VERSION "Version"

NS_ :

BS_:

BU_: VDC_VCU BMS MCU EVCC EOP VDC_ITS GWM Tester IPS DCU ITS IPU TEL VCU VDC AVNT LPC DCDC

BO_ 864 VCU_2_E: 8 VDC_VCU
 SG_ VCU_AHFShutImme : 23|1@0+ (1,0) [0|1] ""  GWM,TEL,ITS,MCU,DCU
 SG_ VCU_AHFDelayEn : 48|1@0+ (1,0) [0|1] ""  GWM,TEL,ITS,MCU,DCU
 SG_ VCU_AHFActivationSt : 51|3@0+ (1,0) [0|7] ""  GWM,TEL,ITS,MCU,DCU
 SG_ VCU_PlgConnSt : 63|1@0+ (1,0) [0|1] ""  GWM,TEL,ITS,MCU,DCU,IPU

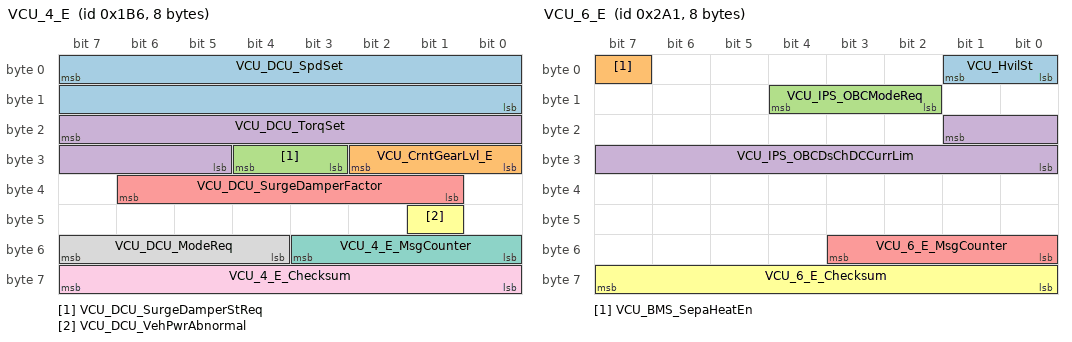
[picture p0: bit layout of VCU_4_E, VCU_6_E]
BO_ 438 VCU_4_E: 8 VDC_VCU
 SG_ VCU_DCU_SpdSet : 7|16@0+ (1,-32767) [-32767|32766] "rpm"  GWM,TEL,MCU,DCU,IPU
 SG_ VCU_CrntGearLvl_E : 26|3@0+ (1,0) [0|7] ""  GWM,TEL,MCU,DCU,IPU
 SG_ VCU_DCU_SurgeDamperStReq : 28|2@0+ (1,0) [0|3] ""  GWM,TEL,MCU,DCU,IPU
 SG_ VCU_DCU_TorqSet : 23|11@0+ (1,-1023) [-1023|1022] "Nm"  GWM,TEL,MCU,DCU,IPU
 SG_ VCU_DCU_SurgeDamperFactor : 38|6@0+ (0.125,0) [0|7.625] ""  GWM,TEL,MCU,DCU,IPU
 SG_ VCU_DCU_VehPwrAbnormal : 41|1@0+ (1,0) [0|1] ""  GWM,MCU,DCU
 SG_ VCU_4_E_MsgCounter : 51|4@0+ (1,0) [0|15] ""  GWM,TEL,MCU,DCU,IPU
 SG_ VCU_DCU_ModeReq : 55|4@0+ (1,0) [0|15] ""  GWM,TEL,MCU,DCU,IPU
 SG_ VCU_4_E_Checksum : 63|8@0+ (1,0) [0|255] ""  GWM,TEL,MCU,DCU,IPU

BO_ 680 VCU_5_E: 8 VDC_VCU
 SG_ VCU_IPS_DCDCVoltLvSet : 7|8@0+ (0.1,0) [0|25.5] "V"  GWM,TEL,MCU,IPS
 SG_ VCU_IPS_DCDCModeReq : 10|3@0+ (1,0) [0|7] ""  GWM,TEL,MCU,IPS
 SG_ VCU_IPS_DCDCLvCurrLim : 45|10@0+ (0.5,0) [0|511.5] "A"  GWM,TEL,MCU,IPS
 SG_ VCU_5_E_MsgCounter : 51|4@0+ (1,0) [0|15] ""  GWM,TEL,BMS,MCU,IPS
 SG_ VCU_5_E_Checksum : 63|8@0+ (1,0) [0|255] ""  GWM,TEL,BMS,MCU,IPS

BO_ 673 VCU_6_E: 8 VDC_VCU
 SG_ VCU_HvilSt : 1|2@0+ (1,0) [0|3] ""  GWM,TEL,BMS,MCU,DCU
 SG_ VCU_BMS_SepaHeatEn : 7|1@0+ (1,0) [0|1] ""  GWM,TEL,ITS,BMS,MCU,IPS
 SG_ VCU_IPS_OBCModeReq : 12|3@0+ (1,0) [0|7] ""  GWM,TEL,MCU,IPS
 SG_ VCU_IPS_OBCDsChDCCurrLim : 17|10@0+ (0.1,0) [0|102.3] "A"  GWM,TEL,MCU,IPS
 SG_ VCU_6_E_MsgCounter : 51|4@0+ (1,0) [0|15] ""  GWM,TEL,BMS,MCU,IPS
 SG_ VCU_6_E_Checksum : 63|8@0+ (1,0) [0|255] ""  GWM,TEL,BMS,MCU,IPS

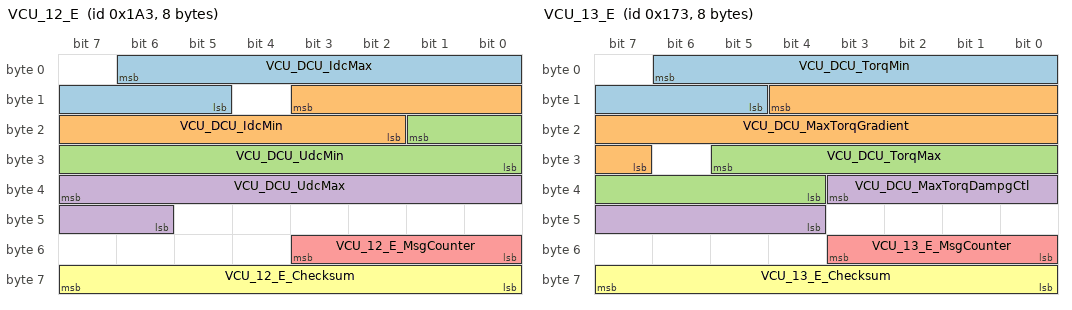
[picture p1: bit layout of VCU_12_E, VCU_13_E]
BO_ 419 VCU_12_E: 8 VDC_VCU
 SG_ VCU_DCU_IdcMax : 6|10@0+ (1,0) [0|1023] "A"  GWM,TEL,MCU,DCU,IPU
 SG_ VCU_DCU_IdcMin : 11|10@0+ (1,-1023) [-1023|0] "A"  GWM,TEL,MCU,DCU,IPU
 SG_ VCU_DCU_UdcMin : 17|10@0+ (1,0) [0|1021] "V"  GWM,TEL,MCU,DCU,IPU
 SG_ VCU_DCU_UdcMax : 39|10@0+ (1,0) [0|1021] "V"  GWM,TEL,MCU,DCU,IPU
 SG_ VCU_12_E_MsgCounter : 51|4@0+ (1,0) [0|15] ""  GWM,TEL,MCU,DCU,IPU
 SG_ VCU_12_E_Checksum : 63|8@0+ (1,0) [0|255] ""  GWM,TEL,MCU,DCU,IPU

BO_ 371 VCU_13_E: 8 VDC_VCU
 SG_ VCU_DCU_TorqMin : 6|10@0+ (1,-1023) [-1023|0] "Nm"  GWM,TEL,MCU,DCU,IPU
 SG_ VCU_DCU_MaxTorqGradient : 12|14@0+ (32,0) [0|524192] "Nm/s"  GWM,TEL,MCU,DCU,IPU
 SG_ VCU_DCU_TorqMax : 29|10@0+ (1,0) [0|1023] "Nm"  GWM,TEL,MCU,DCU,IPU
 SG_ VCU_DCU_MaxTorqDampgCtl : 35|8@0+ (1,0) [0|253] "Nm"  GWM,TEL,MCU,DCU,IPU
 SG_ VCU_13_E_MsgCounter : 51|4@0+ (1,0) [0|15] ""  GWM,TEL,MCU,DCU,IPS,IPU
 SG_ VCU_13_E_Checksum : 63|8@0+ (1,0) [0|255] ""  GWM,TEL,MCU,DCU,IPS,IPU

BO_ 893 VCU_16_E: 8 VDC_VCU
 SG_ VCU_IPS_OBCChgVoltReq : 7|16@0+ (0.1,0) [0|6553.5] "V"  GWM,TEL,MCU,IPS
 SG_ VCU_IPS_OBCChgCurrReq : 23|16@0+ (0.1,0) [0|6553.5] "A"  GWM,TEL,MCU,IPS
 SG_ VCU_16_E_MsgCounter : 51|4@0+ (1,0) [0|15] ""  GWM,TEL,MCU,IPS
 SG_ VCU_16_E_Checksum : 63|8@0+ (1,0) [0|255] ""  GWM,TEL,MCU,IPS

BO_ 779 VCU_20_E: 8 VDC_VCU
 SG_ VCU_AHFActivatePwr : 7|14@0+ (10,0) [0|163830] "W"  GWM,TEL,ITS,MCU,DCU
 SG_ VCU_DCU_IdcMeasure : 9|14@0+ (0.1,-819.2) [-819.2|819.1] "A"  GWM,TEL,ITS,MCU,DCU
 SG_ VCU_SwapHvBattModeSt : 62|2@0+ (1,0) [0|3] ""  DCU,ITS,GWM,EOP,MCU,DCDC,IPS,BMS
 SG_ VCU_SwapHvBattModeStVD : 63|1@0+ (1,0) [0|1] ""  DCU,ITS,GWM,EOP,MCU,DCDC,IPS,BMS

BO_ 964 VCU_22_E: 8 VDC_VCU
 SG_ VCU_22_E_MsgCounter : 51|4@0+ (1,0) [0|15] ""  GWM,TEL,MCU,DCU
 SG_ VCU_22_E_Checksum : 63|8@0+ (1,0) [0|255] ""  GWM,TEL,MCU,DCU

BO_ 983 VCU_25_E: 8 VDC_VCU
 SG_ VCU_TEL_AccPedalActPst : 39|8@0+ (1,0) [0|100] "%"  GWM,TEL,MCU,DCU

BO_ 357 VCU_42_E: 8 VDC_VCU
 SG_ VCU_DCU_SpdLmt : 7|16@0+ (1,-32767) [-32767|32766] "rpm"  GWM,TEL,MCU,DCU,IPU
 SG_ VCU_BrkPedPst_E : 23|8@0+ (0.392,0) [0|99.96] "%"  GWM,MCU,DCU
 SG_ VCU_EMS_AccPedalActPst_E : 31|8@0+ (0.392,0) [0|99.96] "%"  GWM,MCU,DCU

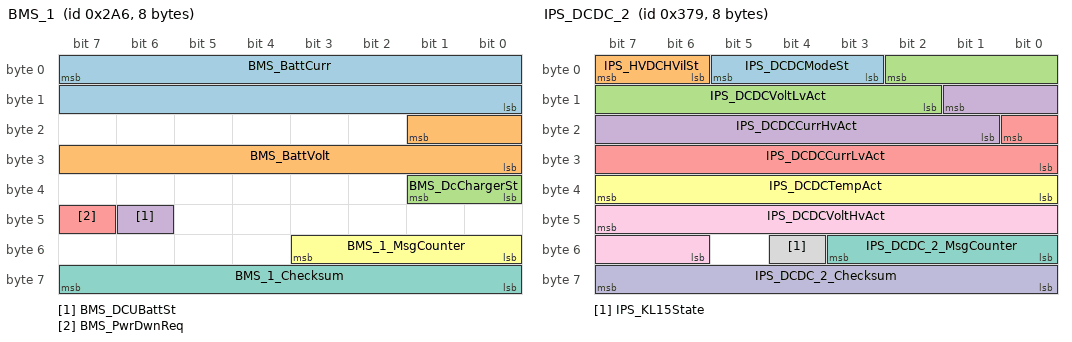
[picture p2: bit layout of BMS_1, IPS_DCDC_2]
BO_ 678 BMS_1: 8 BMS
 SG_ BMS_BattCurr : 7|16@0+ (0.1,-1000) [-1000|1000] "A"  GWM,TEL,MCU,DCU,IPU,VCU,VDC
 SG_ BMS_BattVolt : 17|10@0+ (1,0) [0|600] "V"  GWM,TEL,MCU,DCU,IPU,VCU,VDC,EVCC
 SG_ BMS_DcChargerSt : 33|2@0+ (1,0) [0|3] ""  GWM,TEL,MCU,DCU,IPU,VCU,VDC
 SG_ BMS_DCUBattSt : 46|1@0+ (1,0) [0|1] ""  GWM,TEL,ITS,MCU,DCU,IPS,IPU,VCU,VDC
 SG_ BMS_PwrDwnReq : 47|1@0+ (1,0) [0|1] ""  GWM,TEL,MCU,DCU,IPS,IPU,VCU,VDC
 SG_ BMS_1_MsgCounter : 51|4@0+ (1,0) [0|15] ""  GWM,TEL,MCU,DCU,IPS,IPU,VCU,VDC
 SG_ BMS_1_Checksum : 63|8@0+ (1,0) [0|255] ""  GWM,TEL,MCU,DCU,IPS,IPU,VCU,VDC

BO_ 887 BMS_3: 8 BMS
 SG_ BMS_DCVoltRx : 23|16@0+ (0.1,0) [0|750] "V"  GWM,TEL,MCU,DCU,VCU,VDC
 SG_ BMS_DCCurrRx : 39|16@0+ (0.1,-1000) [-1000|1000] "A"  GWM,TEL,MCU,DCU,VCU,VDC

BO_ 444 BMS_16: 8 BMS
 SG_ BMS_SepaHeatSt : 35|2@0+ (1,0) [0|3] ""  GWM,TEL,ITS,MCU,IPS,VCU,VDC
 SG_ BMS_16_MsgCounter : 51|4@0+ (1,0) [0|15] ""  GWM,TEL,MCU,IPS
 SG_ BMS_16_Checksum : 63|8@0+ (1,0) [0|255] ""  GWM,TEL,MCU,IPS

BO_ 889 IPS_DCDC_2: 8 MCU
 SG_ IPS_DCDCModeSt : 5|3@0+ (1,0) [0|7] ""  GWM,TEL,VCU,VDC
 SG_ IPS_HVDCHVilSt : 7|2@0+ (1,0) [0|3] ""  GWM,TEL,VCU,VDC
 SG_ IPS_DCDCVoltLvAct : 2|9@0+ (0.1,0) [0|51.1] "V"  GWM,TEL,ITS,DCU,VCU,VDC
 SG_ IPS_DCDCCurrHvAct : 9|9@0+ (0.125,0) [0|63.875] "A"  GWM,TEL,DCU,VCU,VDC
 SG_ IPS_DCDCCurrLvAct : 16|9@0+ (1,0) [0|511] "A"  GWM,TEL,VCU,VDC
 SG_ IPS_DCDCTempAct : 39|8@0+ (1,-40) [-40|215] "degC"  GWM,TEL,ITS,VCU,VDC
 SG_ IPS_DCDC_2_MsgCounter : 51|4@0+ (1,0) [0|15] ""  GWM,TEL,DCU,VCU,VDC
 SG_ IPS_KL15State : 52|1@0+ (1,0) [0|1] ""  GWM,TEL,VCU,VDC
 SG_ IPS_DCDCVoltHvAct : 47|10@0+ (1,0) [0|1023] "V"  GWM,TEL,DCU,VCU,VDC
 SG_ IPS_DCDC_2_Checksum : 63|8@0+ (1,0) [0|255] ""  GWM,TEL,DCU,VCU,VDC

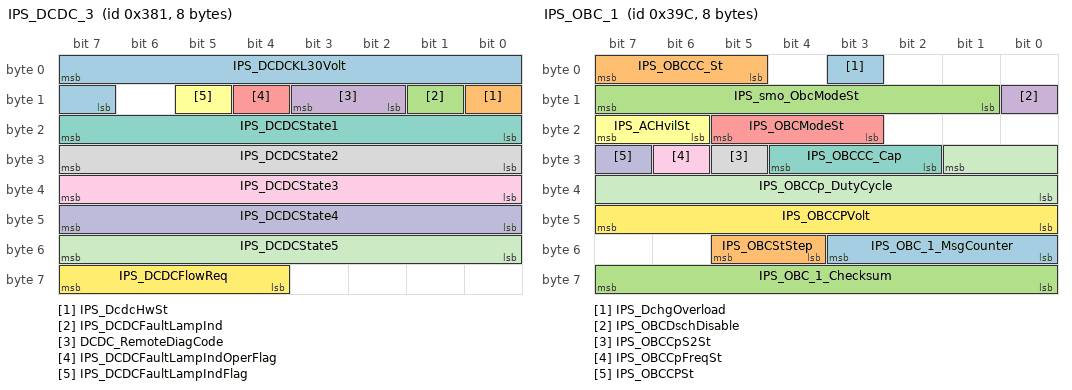
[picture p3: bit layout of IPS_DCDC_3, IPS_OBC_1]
BO_ 897 IPS_DCDC_3: 8 MCU
 SG_ IPS_DCDCKL30Volt : 7|9@0+ (0.125,0) [0|63.875] "V"  GWM,TEL,VCU,VDC
 SG_ IPS_DcdcHwSt : 8|1@0+ (1,0) [0|1] ""  GWM,TEL,VCU,VDC
 SG_ IPS_DCDCFaultLampInd : 9|1@0+ (1,0) [0|1] ""  GWM,TEL
 SG_ DCDC_RemoteDiagCode : 11|2@0+ (1,0) [0|3] ""  GWM,TEL,VCU,VDC
 SG_ IPS_DCDCFaultLampIndOperFlag : 12|1@0+ (1,0) [0|1] ""  GWM,TEL,VCU,VDC
 SG_ IPS_DCDCFaultLampIndFlag : 13|1@0+ (1,0) [0|1] ""  GWM,TEL,VCU,VDC
 SG_ IPS_DCDCState1 : 23|8@0+ (1,0) [0|255] ""  GWM,TEL
 SG_ IPS_DCDCState2 : 31|8@0+ (1,0) [0|255] ""  GWM,TEL
 SG_ IPS_DCDCState3 : 39|8@0+ (1,0) [0|255] ""  GWM,TEL
 SG_ IPS_DCDCState4 : 47|8@0+ (1,0) [0|255] ""  GWM,TEL
 SG_ IPS_DCDCState5 : 55|8@0+ (1,0) [0|255] ""  GWM,TEL
 SG_ IPS_DCDCFlowReq : 63|4@0+ (1,0) [0|15] "LpMin"  GWM,TEL,VCU,VDC

BO_ 924 IPS_OBC_1: 8 MCU
 SG_ IPS_DchgOverload : 3|1@0+ (1,0) [0|1] ""  GWM,TEL,VCU,VDC
 SG_ IPS_OBCCC_St : 7|3@0+ (1,0) [0|7] ""  GWM,TEL,ITS,BMS,DCU,VCU,VDC,EVCC
 SG_ IPS_smo_ObcModeSt : 15|7@0+ (1,0) [0|127] ""  GWM,TEL,VCU,VDC
 SG_ IPS_OBCDschDisable : 8|1@0+ (1,0) [0|1] ""  GWM,TEL,VCU,VDC
 SG_ IPS_OBCModeSt : 21|3@0+ (1,0) [0|7] ""  GWM,TEL,ITS,VCU,VDC
 SG_ IPS_ACHvilSt : 23|2@0+ (1,0) [0|3] ""  GWM,TEL,VCU,VDC
 SG_ IPS_OBCCC_Cap : 28|3@0+ (1,0) [0|7] ""  GWM,TEL,BMS,VCU,VDC
 SG_ IPS_OBCCpS2St : 29|1@0+ (1,0) [0|1] ""  GWM,TEL,VCU,VDC,EVCC
 SG_ IPS_OBCCpFreqSt : 30|1@0+ (1,0) [0|1] ""  GWM,TEL,VCU,VDC
 SG_ IPS_OBCCPSt : 31|1@0+ (1,0) [0|1] ""  GWM,TEL,VCU,VDC
 SG_ IPS_OBCCp_DutyCycle : 25|10@0+ (0.1,0) [0|100] ""  GWM,TEL
 SG_ IPS_OBCCPVolt : 47|8@0+ (0.1,0) [0|12.7] "V"  GWM,TEL,VCU,VDC
 SG_ IPS_OBC_1_MsgCounter : 51|4@0+ (1,0) [0|15] ""  GWM,TEL,BMS,VCU
 SG_ IPS_OBCStStep : 53|2@0+ (1,0) [0|3] ""  GWM,TEL
 SG_ IPS_OBC_1_Checksum : 63|8@0+ (1,0) [0|255] ""  GWM,TEL,VCU

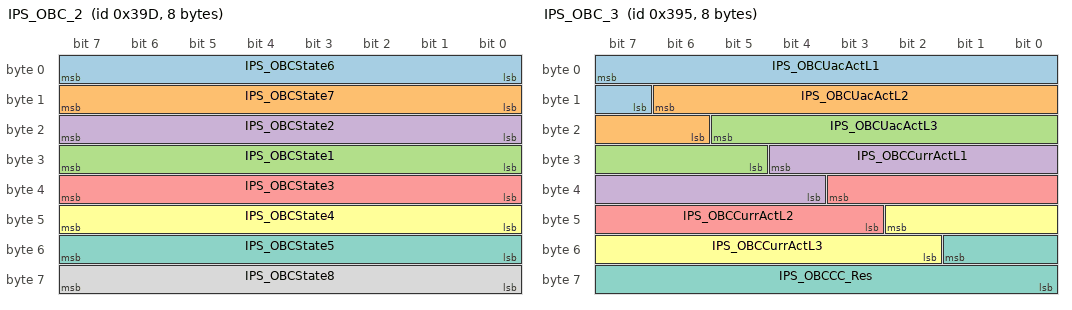
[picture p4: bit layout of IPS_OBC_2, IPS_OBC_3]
BO_ 925 IPS_OBC_2: 8 MCU
 SG_ IPS_OBCState6 : 7|8@0+ (1,0) [0|255] ""  GWM,TEL
 SG_ IPS_OBCState7 : 15|8@0+ (1,0) [0|255] ""  GWM,TEL
 SG_ IPS_OBCState1 : 31|8@0+ (1,0) [0|255] ""  GWM,TEL
 SG_ IPS_OBCState2 : 23|8@0+ (1,0) [0|255] ""  GWM,TEL
 SG_ IPS_OBCState3 : 39|8@0+ (1,0) [0|255] ""  GWM,TEL
 SG_ IPS_OBCState4 : 47|8@0+ (1,0) [0|255] ""  GWM,TEL
 SG_ IPS_OBCState5 : 55|8@0+ (1,0) [0|255] ""  GWM,TEL
 SG_ IPS_OBCState8 : 63|8@0+ (1,0) [0|255] ""  GWM,TEL

BO_ 917 IPS_OBC_3: 8 MCU
 SG_ IPS_OBCUacActL1 : 7|9@0+ (1,0) [0|511] "V"  GWM,TEL,VCU,VDC
 SG_ IPS_OBCUacActL2 : 14|9@0+ (1,0) [0|511] "V"  GWM,TEL,VCU,VDC
 SG_ IPS_OBCUacActL3 : 21|9@0+ (1,0) [0|511] "V"  GWM,TEL,VCU,VDC
 SG_ IPS_OBCCurrActL1 : 28|9@0+ (0.1,0) [0|51.1] "A"  GWM,TEL,VCU,VDC
 SG_ IPS_OBCCurrActL2 : 35|9@0+ (0.1,0) [0|51.1] "A"  GWM,TEL,VCU,VDC
 SG_ IPS_OBCCurrActL3 : 42|9@0+ (0.1,0) [0|51.1] "A"  GWM,TEL,VCU,VDC
 SG_ IPS_OBCCC_Res : 49|10@0+ (10,0) [0|10230] "Ω"  GWM,TEL,VCU,VDC

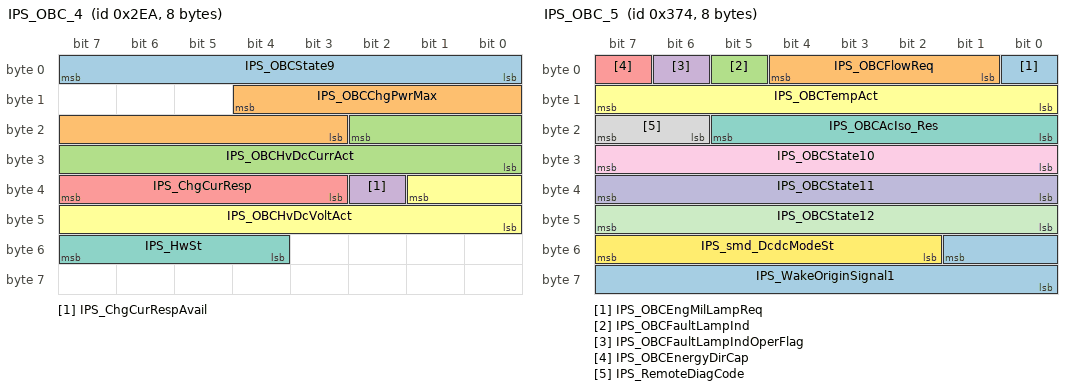
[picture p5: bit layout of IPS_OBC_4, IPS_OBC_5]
BO_ 746 IPS_OBC_4: 8 MCU
 SG_ IPS_OBCState9 : 7|8@0+ (1,0) [0|255] ""  GWM,TEL
 SG_ IPS_OBCChgPwrMax : 12|10@0+ (0.05,0) [0|51.15] "kW"  GWM,TEL,VCU,VDC
 SG_ IPS_OBCHvDcCurrAct : 18|11@0+ (0.1,-102.4) [-102.4|102.3] "A"  GWM,TEL,BMS,VCU,VDC
 SG_ IPS_ChgCurRespAvail : 34|1@0+ (1,0) [0|1] ""  GWM,TEL
 SG_ IPS_ChgCurResp : 39|5@0+ (1,0) [0|31] ""  GWM,TEL
 SG_ IPS_OBCHvDcVoltAct : 33|10@0+ (1,0) [0|1023] "V"  GWM,TEL,VCU,VDC
 SG_ IPS_HwSt : 55|4@0+ (1,0) [0|15] ""  GWM,TEL,VCU,VDC

BO_ 884 IPS_OBC_5: 8 MCU
 SG_ IPS_OBCEngMilLampReq : 0|1@0+ (1,0) [0|1] ""  GWM
 SG_ IPS_OBCFlowReq : 4|4@0+ (1,0) [0|15] "LpMin"  GWM,TEL,VCU,VDC
 SG_ IPS_OBCFaultLampInd : 5|1@0+ (1,0) [0|1] ""  GWM,TEL
 SG_ IPS_OBCFaultLampIndOperFlag : 6|1@0+ (1,0) [0|1] ""  GWM,TEL,VCU,VDC
 SG_ IPS_OBCEnergyDirCap : 7|1@0+ (1,0) [0|1] ""  GWM,TEL,VCU,VDC
 SG_ IPS_OBCTempAct : 15|8@0+ (1,-40) [-40|215] "degC"  GWM,TEL,ITS,VCU,VDC
 SG_ IPS_OBCAcIso_Res : 21|6@0+ (20,0) [0|1260] "kohm"  GWM,TEL
 SG_ IPS_RemoteDiagCode : 23|2@0+ (1,0) [0|3] ""  GWM,TEL,AVNT
 SG_ IPS_OBCState10 : 31|8@0+ (1,0) [0|255] ""  GWM,TEL
 SG_ IPS_OBCState11 : 39|8@0+ (1,0) [0|255] ""  GWM,TEL
 SG_ IPS_OBCState12 : 47|8@0+ (1,0) [0|255] ""  GWM
 SG_ IPS_smd_DcdcModeSt : 55|6@0+ (1,0) [0|63] ""  GWM
 SG_ IPS_WakeOriginSignal1 : 49|10@0+ (1,0) [0|1023] ""  GWM

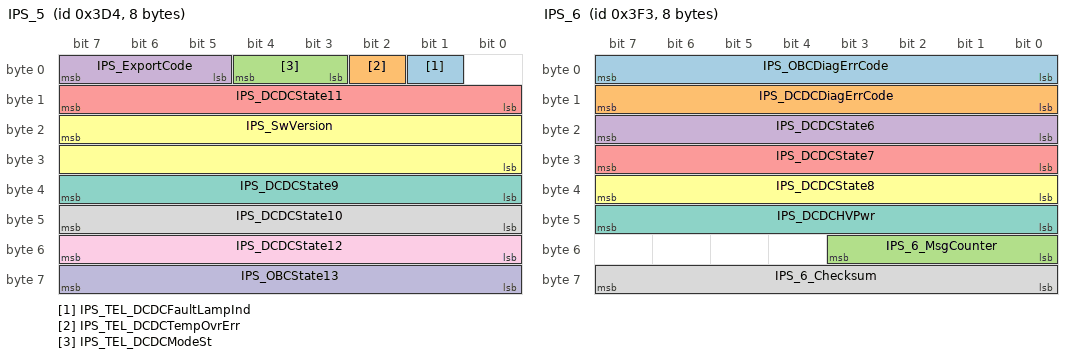
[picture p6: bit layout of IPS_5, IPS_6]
BO_ 980 IPS_5: 8 MCU
 SG_ IPS_TEL_DCDCFaultLampInd : 1|1@0+ (1,0) [0|1] ""  GWM,TEL
 SG_ IPS_TEL_DCDCTempOvrErr : 2|1@0+ (1,0) [0|1] ""  GWM,TEL
 SG_ IPS_TEL_DCDCModeSt : 4|2@0+ (1,0) [0|3] ""  GWM,TEL
 SG_ IPS_ExportCode : 7|3@0+ (1,0) [0|7] ""  GWM,TEL
 SG_ IPS_DCDCState11 : 15|8@0+ (1,0) [0|255] ""  GWM,TEL
 SG_ IPS_SwVersion : 23|16@0+ (1,0) [0|65535] ""  GWM,TEL
 SG_ IPS_DCDCState9 : 39|8@0+ (1,0) [0|255] ""  GWM,TEL
 SG_ IPS_DCDCState10 : 47|8@0+ (1,0) [0|255] ""  GWM,TEL
 SG_ IPS_DCDCState12 : 55|8@0+ (1,0) [0|255] ""  GWM,TEL
 SG_ IPS_OBCState13 : 63|8@0+ (1,0) [0|255] ""  GWM,TEL

BO_ 1011 IPS_6: 8 MCU
 SG_ IPS_OBCDiagErrCode : 7|8@0+ (1,0) [0|255] ""  GWM,TEL,VCU,VDC
 SG_ IPS_DCDCDiagErrCode : 15|8@0+ (1,0) [0|255] ""  GWM,TEL,VCU,VDC
 SG_ IPS_6_MsgCounter : 51|4@0+ (1,0) [0|15] ""  GWM,TEL,VCU,VDC
 SG_ IPS_DCDCState6 : 23|8@0+ (1,0) [0|255] ""  GWM,TEL
 SG_ IPS_DCDCState7 : 31|8@0+ (1,0) [0|255] ""  GWM,TEL
 SG_ IPS_DCDCState8 : 39|8@0+ (1,0) [0|255] ""  GWM,TEL
 SG_ IPS_DCDCHVPwr : 47|8@0+ (5,0) [0|1023] "W"  GWM,TEL
 SG_ IPS_6_Checksum : 63|8@0+ (1,0) [0|255] ""  GWM,TEL,VCU,VDC

BO_ 2683306134 IPS_DEBUG_1: 8 MCU
 SG_ IPS_ocm_AswVersion : 7|8@0+ (1,0) [0|255] ""  Tester
 SG_ IPS_PfcVersion : 47|8@0+ (1,0) [0|255] ""  Tester
 SG_ IPS_LlcVersion : 55|8@0+ (1,0) [0|255] ""  Tester
 SG_ IPS_DcdcVersion : 63|8@0+ (1,0) [0|255] ""  Tester

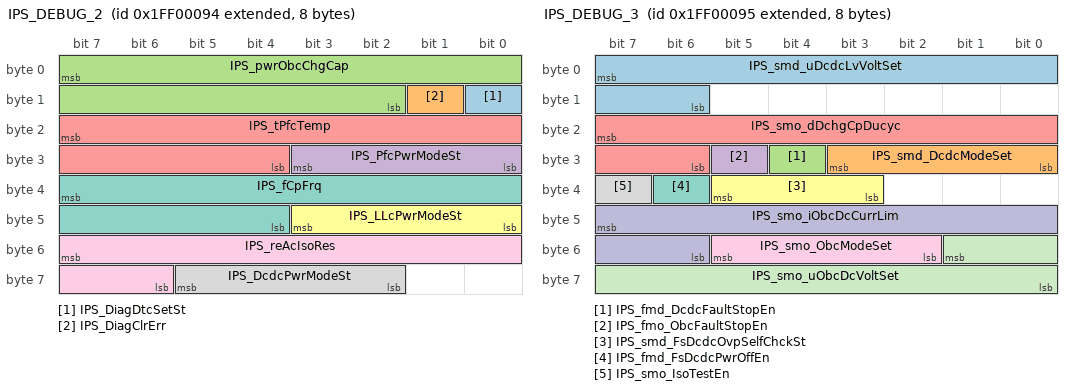
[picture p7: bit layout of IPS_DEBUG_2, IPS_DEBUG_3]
BO_ 2683306132 IPS_DEBUG_2: 8 MCU
 SG_ IPS_DiagDtcSetSt : 8|1@0+ (1,0) [0|1] ""  Tester
 SG_ IPS_DiagClrErr : 9|1@0+ (1,0) [0|1] ""  Tester
 SG_ IPS_pwrObcChgCap : 7|14@0+ (0.01,0) [0|163.83] "KW"  Tester
 SG_ IPS_PfcPwrModeSt : 27|4@0+ (1,0) [0|15] ""  Tester
 SG_ IPS_tPfcTemp : 23|12@0+ (0.1,-50) [-50|359.5] "degC"  Tester
 SG_ IPS_LLcPwrModeSt : 43|4@0+ (1,0) [0|15] ""  Tester
 SG_ IPS_fCpFrq : 39|12@0+ (1,0) [0|4095] "Hz"  Tester
 SG_ IPS_DcdcPwrModeSt : 61|4@0+ (1,0) [0|15] ""  Tester
 SG_ IPS_reAcIsoRes : 55|10@0+ (1,0) [0|1023] "KOhm"  Tester

BO_ 2683306133 IPS_DEBUG_3: 8 MCU
 SG_ IPS_smd_uDcdcLvVoltSet : 7|10@0+ (0.1,0) [0|102.3] "V"  Tester
 SG_ IPS_smd_DcdcModeSet : 27|4@0+ (1,0) [0|15] ""  Tester
 SG_ IPS_fmd_DcdcFaultStopEn : 28|1@0+ (1,0) [0|1] ""  Tester
 SG_ IPS_fmo_ObcFaultStopEn : 29|1@0+ (1,0) [0|1] ""  Tester
 SG_ IPS_smo_dDchgCpDucyc : 23|10@0+ (0.1,0) [0|100] "%"  Tester
 SG_ IPS_smd_FsDcdcOvpSelfChckSt : 37|3@0+ (1,0) [0|7] ""  Tester
 SG_ IPS_fmd_FsDcdcPwrOffEn : 38|1@0+ (1,0) [0|1] ""  Tester
 SG_ IPS_smo_IsoTestEn : 39|1@0+ (1,0) [0|1] ""  Tester
 SG_ IPS_smo_ObcModeSet : 53|4@0+ (1,0) [0|15] ""  Tester
 SG_ IPS_smo_iObcDcCurrLim : 47|10@0+ (0.1,0) [0|102.3] "A"  Tester
 SG_ IPS_smo_uObcDcVoltSet : 49|10@0+ (1,0) [0|1023] "V"  Tester

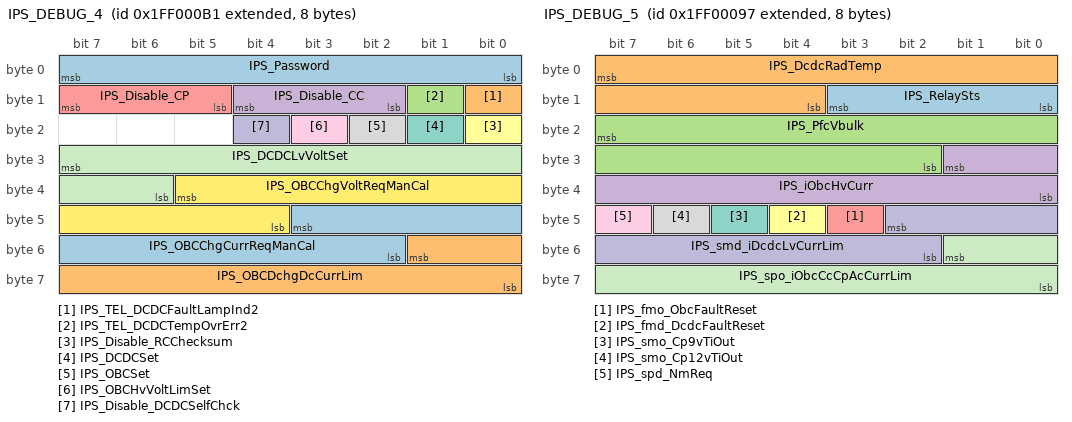
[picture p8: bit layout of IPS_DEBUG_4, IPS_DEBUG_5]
BO_ 2683306161 IPS_DEBUG_4: 8 Tester
 SG_ IPS_Password : 7|8@0+ (1,0) [0|255] ""  MCU
 SG_ IPS_TEL_DCDCFaultLampInd2 : 8|1@0+ (1,0) [0|1] ""  MCU
 SG_ IPS_TEL_DCDCTempOvrErr2 : 9|1@0+ (1,0) [0|1] ""  MCU
 SG_ IPS_Disable_CC : 12|3@0+ (1,0) [0|7] ""  MCU
 SG_ IPS_Disable_CP : 15|3@0+ (1,0) [0|7] ""  MCU
 SG_ IPS_Disable_RCChecksum : 16|1@0+ (1,0) [0|1] ""  MCU
 SG_ IPS_DCDCSet : 17|1@0+ (1,0) [0|1] ""  MCU
 SG_ IPS_OBCSet : 18|1@0+ (1,0) [0|1] ""  MCU
 SG_ IPS_OBCHvVoltLimSet : 19|1@0+ (1,0) [0|1] ""  MCU
 SG_ IPS_Disable_DCDCSelfChck : 20|1@0+ (1,0) [0|1] ""  MCU
 SG_ IPS_DCDCLvVoltSet : 31|10@0+ (0.1,0) [0|102.3] "V"  MCU
 SG_ IPS_OBCChgVoltReqManCal : 37|10@0+ (1,0) [0|1023] "V"  MCU
 SG_ IPS_OBCChgCurrReqManCal : 43|10@0+ (0.1,0) [0|102.3] "A"  MCU
 SG_ IPS_OBCDchgDcCurrLim : 49|10@0+ (0.1,0) [0|102.3] "A"  MCU

BO_ 2683306135 IPS_DEBUG_5: 8 MCU
 SG_ IPS_RelaySts : 11|4@0+ (1,0) [0|15] ""  Tester
 SG_ IPS_DcdcRadTemp : 7|12@0+ (0.1,-50) [-50|359.5] "degC"  Tester
 SG_ IPS_PfcVbulk : 23|14@0+ (0.1,0) [0|1638.3] "V"  Tester
 SG_ IPS_iObcHvCurr : 25|10@0+ (0.1,0) [0|102.3] "A"  Tester
 SG_ IPS_fmo_ObcFaultReset : 43|1@0+ (1,0) [0|1] ""  Tester
 SG_ IPS_fmd_DcdcFaultReset : 44|1@0+ (1,0) [0|1] ""  Tester
 SG_ IPS_smo_Cp9vTiOut : 45|1@0+ (1,0) [0|1] ""  Tester
 SG_ IPS_smo_Cp12vTiOut : 46|1@0+ (1,0) [0|1] ""  Tester
 SG_ IPS_spd_NmReq : 47|1@0+ (1,0) [0|1] ""  Tester
 SG_ IPS_smd_iDcdcLvCurrLim : 42|9@0+ (1,0) [0|511] "A"  Tester
 SG_ IPS_spo_iObcCcCpAcCurrLim : 49|10@0+ (0.1,0) [0|102.4] "A"  Tester

BO_ 2683306140 IPS_DEBUG_6: 8 MCU
 SG_ IPS_DcdcSRSts : 23|4@0+ (1,0) [0|15] ""  Tester
 SG_ IPS_LlcWorkFreq : 19|12@0+ (0.1,0) [0|409.5] ""  Tester
 SG_ IPS_DcdcBuckDuty : 39|10@0+ (0.1,0) [0|100] "%"  Tester
 SG_ IPS_uFsDcdcLvVolt : 45|10@0+ (0.1,0) [0|102.3] "V"  Tester

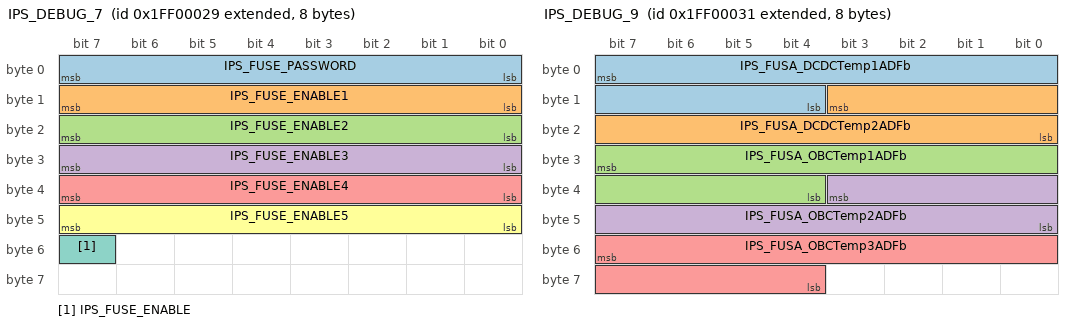
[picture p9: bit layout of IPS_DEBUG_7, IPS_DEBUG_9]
BO_ 2683306025 IPS_DEBUG_7: 8 Tester
 SG_ IPS_FUSE_PASSWORD : 7|8@0+ (1,0) [0|255] ""  MCU
 SG_ IPS_FUSE_ENABLE1 : 15|8@0+ (1,0) [0|255] ""  MCU
 SG_ IPS_FUSE_ENABLE2 : 23|8@0+ (1,0) [0|255] ""  MCU
 SG_ IPS_FUSE_ENABLE3 : 31|8@0+ (1,0) [0|255] ""  MCU
 SG_ IPS_FUSE_ENABLE4 : 39|8@0+ (1,0) [0|255] ""  MCU
 SG_ IPS_FUSE_ENABLE5 : 47|8@0+ (1,0) [0|255] ""  MCU
 SG_ IPS_FUSE_ENABLE : 55|1@0+ (1,0) [0|1] ""  MCU

BO_ 2683306032 IPS_DEBUG_8: 8 MCU
 SG_ IPS_FUSA_DCDCLvVsVoltADFb : 7|12@0+ (1,0) [0|4095] ""  Tester
 SG_ IPS_FUSA_DCDCLvVdVoltADFb : 11|12@0+ (1,0) [0|4095] ""  Tester
 SG_ IPS_FUSA_DCDCLvCur1ADFb : 31|12@0+ (1,0) [0|4095] ""  Tester
 SG_ IPS_FUSA_DCDCLvCur2ADFb : 35|12@0+ (1,0) [0|4095] ""  Tester

BO_ 2683306033 IPS_DEBUG_9: 8 MCU
 SG_ IPS_FUSA_DCDCTemp1ADFb : 7|12@0+ (1,0) [0|4095] ""  Tester
 SG_ IPS_FUSA_DCDCTemp2ADFb : 11|12@0+ (1,0) [0|4095] ""  Tester
 SG_ IPS_FUSA_OBCTemp1ADFb : 31|12@0+ (1,0) [0|4095] ""  Tester
 SG_ IPS_FUSA_OBCTemp2ADFb : 35|12@0+ (1,0) [0|4095] ""  Tester
 SG_ IPS_FUSA_OBCTemp3ADFb : 55|12@0+ (1,0) [0|4095] ""  Tester

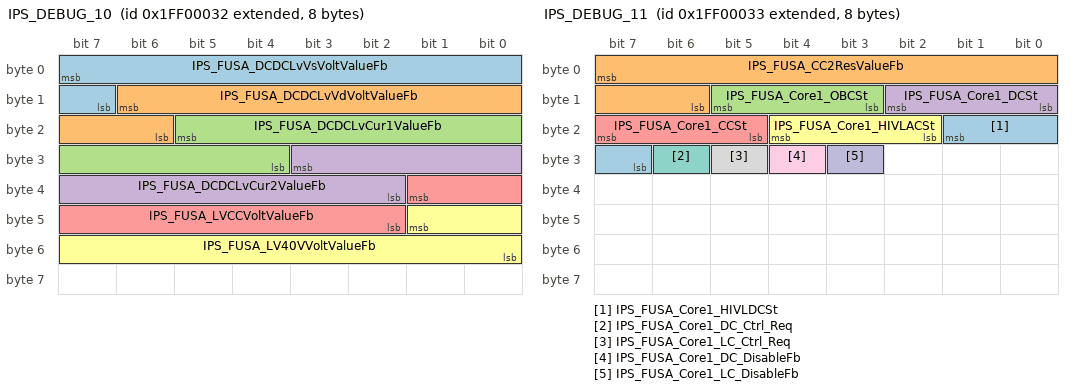
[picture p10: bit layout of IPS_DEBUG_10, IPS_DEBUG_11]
BO_ 2683306034 IPS_DEBUG_10: 8 MCU
 SG_ IPS_FUSA_DCDCLvVsVoltValueFb : 7|9@0+ (0.1,0) [0|51.1] "V"  Tester
 SG_ IPS_FUSA_DCDCLvVdVoltValueFb : 14|9@0+ (0.1,0) [0|51.1] "V"  Tester
 SG_ IPS_FUSA_DCDCLvCur1ValueFb : 21|10@0+ (1,-511) [-511|512] "A"  Tester
 SG_ IPS_FUSA_DCDCLvCur2ValueFb : 27|10@0+ (1,-511) [-511|512] "A"  Tester
 SG_ IPS_FUSA_LVCCVoltValueFb : 33|8@0+ (0.1,0) [0|25.5] "V"  Tester
 SG_ IPS_FUSA_LV40VVoltValueFb : 41|10@0+ (0.1,0) [0|102.3] "V"  Tester

BO_ 2683306035 IPS_DEBUG_11: 8 MCU
 SG_ IPS_FUSA_Core1_HIVLDCSt : 17|3@0+ (1,0) [0|7] ""  Tester
 SG_ IPS_FUSA_CC2ResValueFb : 7|10@0+ (10,0) [0|10230] "¦¸"  Tester
 SG_ IPS_FUSA_Core1_OBCSt : 13|3@0+ (1,0) [0|7] ""  Tester
 SG_ IPS_FUSA_Core1_DCSt : 10|3@0+ (1,0) [0|7] ""  Tester
 SG_ IPS_FUSA_Core1_CCSt : 23|3@0+ (1,0) [0|7] ""  Tester
 SG_ IPS_FUSA_Core1_HIVLACSt : 20|3@0+ (1,0) [0|7] ""  Tester
 SG_ IPS_FUSA_Core1_DC_Ctrl_Req : 30|1@0+ (1,0) [0|1] ""  Tester
 SG_ IPS_FUSA_Core1_LC_Ctrl_Req : 29|1@0+ (1,0) [0|1] ""  Tester
 SG_ IPS_FUSA_Core1_DC_DisableFb : 28|1@0+ (1,0) [0|1] ""  Tester
 SG_ IPS_FUSA_Core1_LC_DisableFb : 27|1@0+ (1,0) [0|1] ""  Tester

BO_ 2683306036 IPS_DEBUG_12: 8 MCU
 SG_ IPS_FUSA_Core1_MCUSBC_Byte0 : 7|8@0+ (1,0) [0|255] ""  Tester
 SG_ IPS_FUSA_Core1_MCUSBC_Byte1 : 15|8@0+ (1,0) [0|255] ""  Tester
 SG_ IPS_FUSA_Core1_MCUSBC_Byte2 : 23|8@0+ (1,0) [0|255] ""  Tester
 SG_ IPS_FUSA_Core1_MCUSBC_Byte3 : 31|8@0+ (1,0) [0|255] ""  Tester
 SG_ IPS_FUSA_Core1_MCUSBC_Byte4 : 39|8@0+ (1,0) [0|255] ""  Tester
 SG_ IPS_FUSA_Core1_MCUSBC_Byte5 : 47|8@0+ (1,0) [0|255] ""  Tester
 SG_ IPS_FUSA_Core1_MCUSBC_Byte6 : 55|8@0+ (1,0) [0|255] ""  Tester

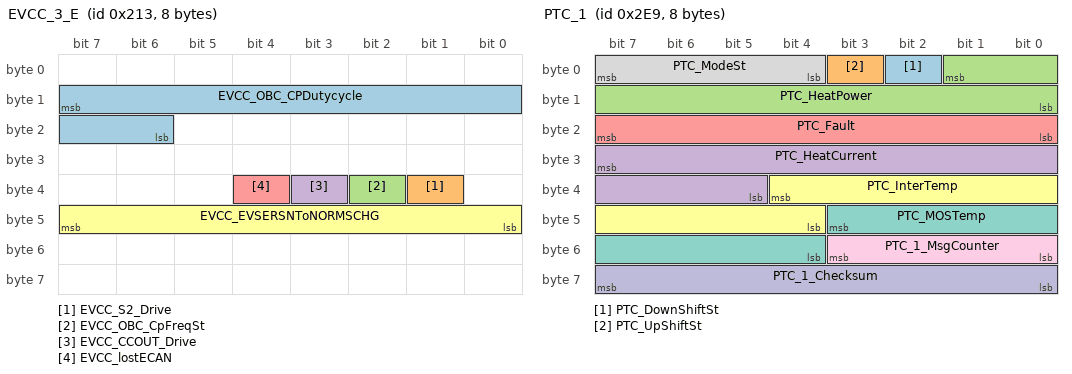
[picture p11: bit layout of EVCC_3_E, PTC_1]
BO_ 531 EVCC_3_E: 8 EVCC
 SG_ EVCC_OBC_CPDutycycle : 15|10@0+ (0.1,0) [0|102.3] ""  GWM,TEL,MCU,IPS
 SG_ EVCC_S2_Drive : 33|1@0+ (1,0) [0|1] ""  GWM,TEL,MCU,IPS
 SG_ EVCC_OBC_CpFreqSt : 34|1@0+ (1,0) [0|1] ""  GWM,TEL,MCU,IPS
 SG_ EVCC_CCOUT_Drive : 35|1@0+ (1,0) [0|1] ""  GWM,TEL,MCU,IPS
 SG_ EVCC_lostECAN : 36|1@0+ (1,0) [0|1] ""  GWM,TEL,MCU,IPS
 SG_ EVCC_EVSERSNToNORMSCHG : 47|8@0+ (1,0) [0|255] ""  GWM,TEL,MCU,IPS

BO_ 745 PTC_1: 8 MCU
 SG_ PTC_DownShiftSt : 2|1@0+ (1,0) [0|1] ""  GWM,TEL
 SG_ PTC_UpShiftSt : 3|1@0+ (1,0) [0|1] ""  GWM,TEL
 SG_ PTC_HeatPower : 1|10@0+ (10,0) [0|10200] "W"  GWM,TEL,ITS,VCU,VDC
 SG_ PTC_HeatCurrent : 31|11@0+ (0.1,-102.3) [-102.3|102.3] "A"  GWM,TEL,ITS,VDC
 SG_ PTC_Fault : 23|8@0+ (1,0) [0|255] ""  GWM,TEL,ITS,VDC
 SG_ PTC_InterTemp : 36|9@0+ (1,-40) [-40|471] "degC"  GWM,TEL,ITS,VCU,VDC
 SG_ PTC_MOSTemp : 43|8@0+ (1,-40) [-40|215] "degC"  GWM,TEL,ITS,VCU,VDC
 SG_ PTC_ModeSt : 7|4@0+ (1,0) [0|15] ""  GWM,TEL,ITS,VDC
 SG_ PTC_1_MsgCounter : 51|4@0+ (1,0) [0|15] ""  GWM,TEL,ITS,VCU,VDC
 SG_ PTC_1_Checksum : 63|8@0+ (1,0) [0|255] ""  GWM,TEL,ITS,VCU,VDC

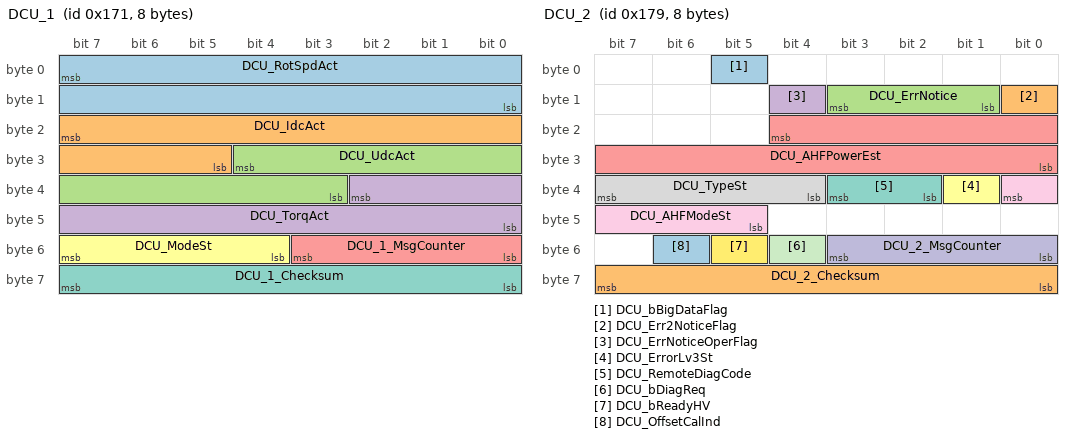
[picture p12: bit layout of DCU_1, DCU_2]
BO_ 369 DCU_1: 8 MCU
 SG_ DCU_RotSpdAct : 7|16@0+ (1,-32767) [-32767|32766] "rpm"  GWM,TEL,VCU,VDC
 SG_ DCU_IdcAct : 23|11@0+ (1,-1023) [-1023|1024] "A"  GWM,TEL,BMS,VCU,VDC
 SG_ DCU_UdcAct : 28|10@0+ (1,0) [0|1023] "V"  GWM,TEL,BMS,VCU,VDC
 SG_ DCU_TorqAct : 34|11@0+ (1,-1023) [-1023|1024] "Nm"  GWM,TEL,VCU,VDC
 SG_ DCU_1_MsgCounter : 51|4@0+ (1,0) [0|15] ""  GWM,TEL,BMS,VCU,VDC
 SG_ DCU_ModeSt : 55|4@0+ (1,0) [0|15] ""  GWM,TEL,BMS,VCU,VDC
 SG_ DCU_1_Checksum : 63|8@0+ (1,0) [0|255] ""  GWM,TEL,BMS,VCU,VDC

BO_ 377 DCU_2: 8 MCU
 SG_ DCU_bBigDataFlag : 5|1@0+ (1,0) [0|1] ""  GWM,TEL
 SG_ DCU_Err2NoticeFlag : 8|1@0+ (1,0) [0|1] ""  GWM,TEL
 SG_ DCU_ErrNotice : 11|3@0+ (1,0) [0|7] ""  GWM,TEL
 SG_ DCU_ErrNoticeOperFlag : 12|1@0+ (1,0) [0|1] ""  GWM,TEL
 SG_ DCU_AHFPowerEst : 20|13@0+ (10,0) [0|81910] ""  GWM,TEL,ITS,VCU,VDC
 SG_ DCU_ErrorLv3St : 33|1@0+ (1,0) [0|1] ""  GWM,TEL
 SG_ DCU_RemoteDiagCode : 35|2@0+ (1,0) [0|3] ""  GWM,TEL
 SG_ DCU_TypeSt : 39|4@0+ (1,0) [0|15] ""  GWM,TEL,VCU,VDC
 SG_ DCU_AHFModeSt : 32|4@0+ (1,0) [0|15] ""  GWM,TEL,ITS,VCU,VDC
 SG_ DCU_2_MsgCounter : 51|4@0+ (1,0) [0|15] ""  GWM,TEL,VCU,VDC
 SG_ DCU_bDiagReq : 52|1@0+ (1,0) [0|1] ""  GWM,TEL
 SG_ DCU_bReadyHV : 53|1@0+ (1,0) [0|1] ""  GWM,TEL
 SG_ DCU_OffsetCalInd : 54|1@0+ (1,0) [0|1] ""  GWM,TEL,VCU,VDC
 SG_ DCU_2_Checksum : 63|8@0+ (1,0) [0|255] ""  GWM,TEL,VCU,VDC

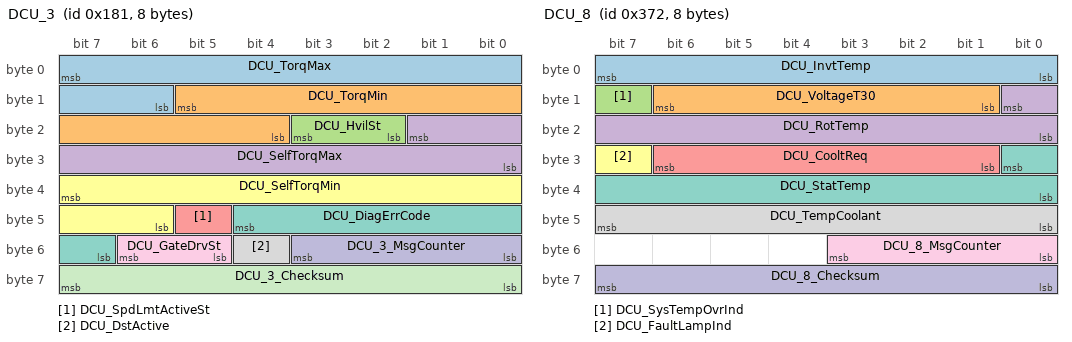
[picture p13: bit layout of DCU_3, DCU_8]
BO_ 385 DCU_3: 8 MCU
 SG_ DCU_TorqMax : 7|10@0+ (1,0) [0|1023] "Nm"  GWM,TEL,VCU,VDC
 SG_ DCU_TorqMin : 13|10@0+ (1,-1023) [-1023|0] "Nm"  GWM,TEL,VCU,VDC
 SG_ DCU_HvilSt : 19|2@0+ (1,0) [0|3] ""  GWM,TEL,VCU,VDC
 SG_ DCU_SelfTorqMax : 17|10@0+ (1,0) [0|1023] "Nm"  GWM,TEL,VCU,VDC
 SG_ DCU_SpdLmtActiveSt : 45|1@0+ (1,0) [0|1] ""  GWM,TEL
 SG_ DCU_SelfTorqMin : 39|10@0+ (1,-1023) [-1023|0] "Nm"  GWM,TEL,VCU,VDC
 SG_ DCU_DiagErrCode : 44|6@0+ (1,0) [0|63] ""  GWM,TEL,VCU,VDC
 SG_ DCU_DstActive : 52|1@0+ (1,0) [0|1] ""  GWM,TEL,VCU,VDC
 SG_ DCU_GateDrvSt : 54|2@0+ (1,0) [0|3] ""  GWM,TEL
 SG_ DCU_3_MsgCounter : 51|4@0+ (1,0) [0|15] ""  GWM,TEL,VCU,VDC
 SG_ DCU_3_Checksum : 63|8@0+ (1,0) [0|255] ""  GWM,TEL,VCU,VDC

BO_ 882 DCU_8: 8 MCU
 SG_ DCU_InvtTemp : 7|8@0+ (1,-40) [-40|215] "deg"  GWM,TEL,VCU,VDC
 SG_ DCU_VoltageT30 : 14|6@0+ (0.5,0) [0|31.5] "V"  GWM,TEL
 SG_ DCU_SysTempOvrInd : 15|1@0+ (1,0) [0|1] ""  GWM,TEL
 SG_ DCU_RotTemp : 8|9@0+ (1,-40) [-40|471] "deg"  GWM,TEL,VCU,VDC
 SG_ DCU_CooltReq : 30|6@0+ (0.25,0) [0|15.5] "L/min"  GWM,TEL,VCU,VDC
 SG_ DCU_FaultLampInd : 31|1@0+ (1,0) [0|1] ""  GWM,TEL
 SG_ DCU_StatTemp : 24|9@0+ (1,-40) [-40|471] "deg"  GWM,TEL,VCU,VDC
 SG_ DCU_TempCoolant : 47|8@0+ (1,-40) [-40|215] "deg"  GWM,TEL,ITS,VCU,VDC
 SG_ DCU_8_MsgCounter : 51|4@0+ (1,0) [0|15] ""  GWM,TEL,VCU,VDC
 SG_ DCU_8_Checksum : 63|8@0+ (1,0) [0|255] ""  GWM,TEL,VCU

BO_ 910 DCU_9: 8 MCU
 SG_ DCU_DataNo M : 7|8@0+ (1,0) [0|255] ""  GWM,TEL
 SG_ DCU_TEL_MotorNumOrder m1 : 15|3@0+ (1,0) [0|7] ""  GWM,TEL
 SG_ DCU_TEL_ECUTempOvrErr m1 : 8|1@0+ (1,0) [0|1] ""  GWM,TEL
 SG_ DCU_TEL_MotTempOvrErr m1 : 9|1@0+ (1,0) [0|1] ""  GWM,TEL
 SG_ DCU_TEL_MotorNumTotal m1 : 12|3@0+ (1,0) [0|7] ""  GWM,TEL
 SG_ DCU_TEL_InvtTemp m1 : 23|8@0+ (1,-40) [-40|215] "deg"  GWM,TEL
 SG_ DCU_TEL_RotSpdAct m1 : 31|16@0+ (1,-20000) [-20000|45535] "rpm"  GWM,TEL
 SG_ DCU_TEL_TorqAct m1 : 47|16@0+ (0.1,-2000) [-2000|4553.5] "Nm"  GWM,TEL
 SG_ DCU_TEL_StatTemp m1 : 63|8@0+ (1,-40) [-40|215] "deg"  GWM,TEL
 SG_ DCU_TEL_ModeSt m2 : 11|3@0+ (1,0) [0|7] ""  GWM,TEL
 SG_ DCU_TEL_CurrActAmend m2 : 23|16@0+ (0.1,-1000) [-1000|1000] "A"  GWM,TEL
 SG_ DCU_TEL_UdcAct m2 : 37|14@0+ (0.1,0) [0|1000] "V"  GWM,TEL
 SG_ DCU_TEL_BattCurr m2 : 55|16@0+ (0.1,-1000) [-1000|1000] "A"  GWM,TEL

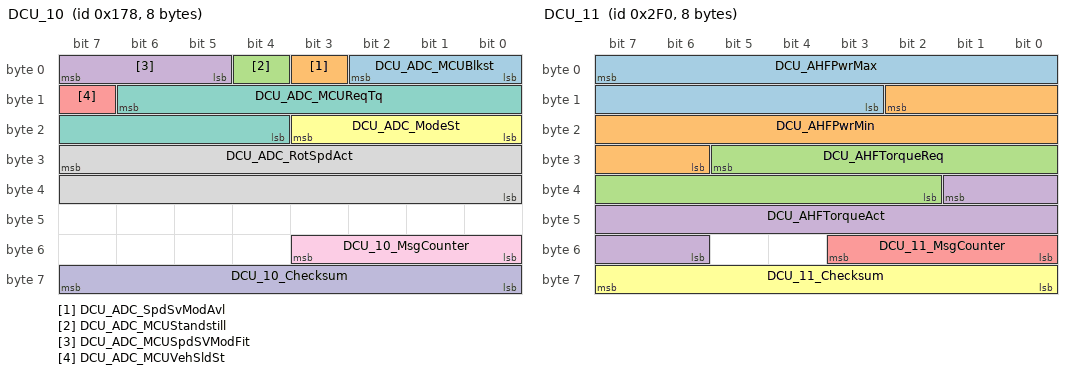
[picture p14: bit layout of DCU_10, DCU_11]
BO_ 376 DCU_10: 8 MCU
 SG_ DCU_ADC_MCUBlkst : 2|3@0+ (1,0) [0|7] ""  GWM,VCU,VDC
 SG_ DCU_ADC_SpdSvModAvl : 3|1@0+ (1,0) [0|1] ""  GWM,VCU,VDC
 SG_ DCU_ADC_MCUStandstill : 4|1@0+ (1,0) [0|1] ""  GWM,VCU,VDC
 SG_ DCU_ADC_MCUSpdSVModFit : 7|3@0+ (1,0) [0|7] ""  GWM,VCU,VDC
 SG_ DCU_ADC_MCUVehSldSt : 15|1@0+ (1,0) [0|1] ""  GWM,VCU,VDC
 SG_ DCU_ADC_ModeSt : 19|4@0+ (1,0) [0|15] ""  GWM,VCU,VDC
 SG_ DCU_ADC_MCUReqTq : 14|11@0+ (1,-1023) [-1023|1023] "Nm"  GWM,VCU,VDC
 SG_ DCU_ADC_RotSpdAct : 31|16@0+ (1,-32767) [-32767|32766] "rpm"  GWM,VCU,VDC
 SG_ DCU_10_MsgCounter : 51|4@0+ (1,0) [0|15] ""  GWM,VCU,VDC
 SG_ DCU_10_Checksum : 63|8@0+ (1,0) [0|255] ""  GWM,VCU,VDC

BO_ 752 DCU_11: 8 MCU
 SG_ DCU_AHFPwrMax : 7|13@0+ (10,0) [0|81910] "W"  GWM,TEL,ITS,VCU,VDC
 SG_ DCU_AHFPwrMin : 10|13@0+ (10,0) [0|81910] "W"  GWM,TEL,ITS,VCU,VDC
 SG_ DCU_AHFTorqueReq : 29|12@0+ (0.2,-409) [-409|409] "Nm"  GWM,TEL,ITS,VCU,VDC
 SG_ DCU_AHFTorqueAct : 33|12@0+ (0.2,-409) [-409|409] "Nm"  GWM,TEL,ITS,VCU,VDC
 SG_ DCU_11_MsgCounter : 51|4@0+ (1,0) [0|15] ""  GWM,TEL,ITS,VCU,VDC
 SG_ DCU_11_Checksum : 63|8@0+ (1,0) [0|255] ""  GWM,TEL,ITS,VCU,VDC

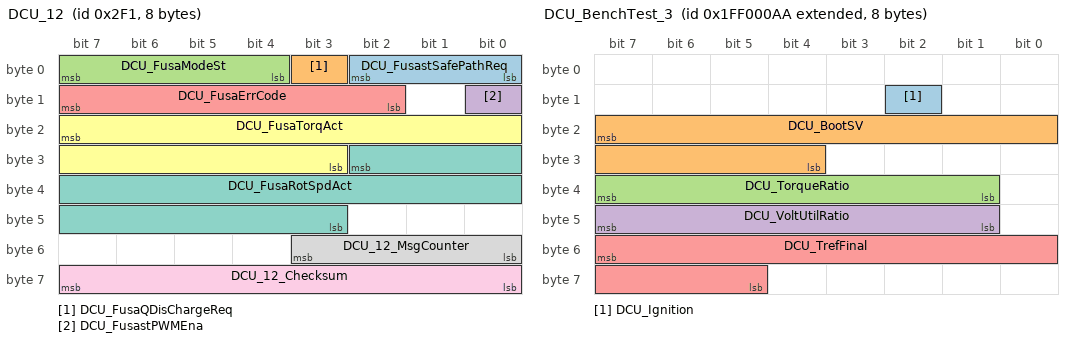
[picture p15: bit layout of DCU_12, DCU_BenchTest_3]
BO_ 753 DCU_12: 8 MCU
 SG_ DCU_FusastSafePathReq : 2|3@0+ (1,0) [0|7] ""  GWM,TEL
 SG_ DCU_FusaQDisChargeReq : 3|1@0+ (1,0) [0|1] ""  GWM,TEL
 SG_ DCU_FusaModeSt : 7|4@0+ (1,0) [0|15] ""  GWM,TEL
 SG_ DCU_FusastPWMEna : 8|1@0+ (1,0) [0|1] ""  GWM,TEL
 SG_ DCU_FusaErrCode : 15|6@0+ (1,0) [0|63] ""  GWM,TEL
 SG_ DCU_FusaTorqAct : 23|13@0+ (0.2,-819) [-819|819] "Nm"  GWM,TEL
 SG_ DCU_FusaRotSpdAct : 26|16@0+ (1,-32767) [-32767|32766] "rpm"  GWM,TEL
 SG_ DCU_12_MsgCounter : 51|4@0+ (1,0) [0|15] ""  GWM,TEL
 SG_ DCU_12_Checksum : 63|8@0+ (1,0) [0|255] ""  GWM,TEL

BO_ 2683306152 DCU_BenchTest_1: 8 MCU
 SG_ DCU_uVoltdRef : 7|15@0+ (0.1,-1500) [-1500|1776.7] "V"  Tester
 SG_ DCU_uVoltqRef : 23|15@0+ (0.1,-1500) [-1500|1776.7] "V"  Tester
 SG_ DCU_iCurdRef : 39|15@0+ (0.1,-1500) [-1500|1776.7] "A"  Tester
 SG_ DCU_iCurqRef : 55|15@0+ (0.1,-1500) [-1500|1776.7] "A"  Tester

BO_ 2683306153 DCU_BenchTest_2: 8 MCU
 SG_ DCU_Id : 7|15@0+ (0.1,-1500) [-1500|1776.7] "A"  Tester
 SG_ DCU_Iq : 23|15@0+ (0.1,-1500) [-1500|1776.7] "A"  Tester
 SG_ DCU_PWMFreq : 39|16@0+ (1,0) [0|65535] "Hz"  Tester
 SG_ DCU_TjMax : 55|8@0+ (1,-40) [-40|215] "degC"  Tester
 SG_ DCU_IgbtNtcTempMax : 63|8@0+ (1,-40) [-40|215] "degC"  Tester

BO_ 2683306154 DCU_BenchTest_3: 8 MCU
 SG_ DCU_Ignition : 10|1@0+ (1,0) [0|1] ""  Tester
 SG_ DCU_BootSV : 23|12@0+ (1,0) [0|4095] ""  Tester
 SG_ DCU_TorqueRatio : 39|7@0+ (0.01,0) [0|1.27] ""  Tester
 SG_ DCU_VoltUtilRatio : 47|7@0+ (0.01,0) [0|1.27] ""  Tester
 SG_ DCU_TrefFinal : 55|11@0+ (1,-1000) [-1000|1047] "Nm"  Tester

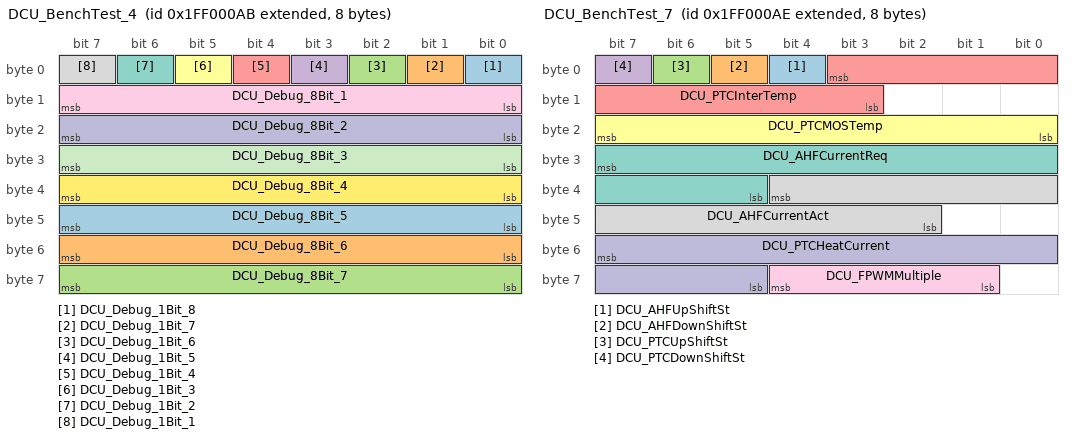
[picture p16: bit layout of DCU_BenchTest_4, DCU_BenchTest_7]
BO_ 2683306155 DCU_BenchTest_4: 8 MCU
 SG_ DCU_Debug_1Bit_8 : 0|1@0+ (1,0) [0|1] ""  Tester
 SG_ DCU_Debug_1Bit_7 : 1|1@0+ (1,0) [0|1] ""  Tester
 SG_ DCU_Debug_1Bit_6 : 2|1@0+ (1,0) [0|1] ""  Tester
 SG_ DCU_Debug_1Bit_5 : 3|1@0+ (1,0) [0|1] ""  Tester
 SG_ DCU_Debug_1Bit_4 : 4|1@0+ (1,0) [0|1] ""  Tester
 SG_ DCU_Debug_1Bit_3 : 5|1@0+ (1,0) [0|1] ""  Tester
 SG_ DCU_Debug_1Bit_2 : 6|1@0+ (1,0) [0|1] ""  Tester
 SG_ DCU_Debug_1Bit_1 : 7|1@0+ (1,0) [0|1] ""  Tester
 SG_ DCU_Debug_8Bit_1 : 15|8@0+ (1,0) [0|255] ""  Tester
 SG_ DCU_Debug_8Bit_2 : 23|8@0+ (1,0) [0|255] ""  Tester
 SG_ DCU_Debug_8Bit_3 : 31|8@0+ (1,0) [0|255] ""  Tester
 SG_ DCU_Debug_8Bit_4 : 39|8@0+ (1,0) [0|255] ""  Tester
 SG_ DCU_Debug_8Bit_5 : 47|8@0+ (1,0) [0|255] ""  Tester
 SG_ DCU_Debug_8Bit_6 : 55|8@0+ (1,0) [0|255] ""  Tester
 SG_ DCU_Debug_8Bit_7 : 63|8@0+ (1,0) [0|255] ""  Tester

BO_ 2683306156 DCU_BenchTest_5: 8 MCU
 SG_ DCU_Debug_16Bit_1 : 7|16@0+ (1,0) [0|65535] ""  Tester
 SG_ DCU_Debug_16Bit_2 : 23|16@0+ (1,0) [0|65535] ""  Tester
 SG_ DCU_Debug_16Bit_3 : 39|16@0+ (1,0) [0|65535] ""  Tester
 SG_ DCU_Debug_16Bit_4 : 55|16@0+ (1,0) [0|65535] ""  Tester

BO_ 2683306157 DCU_BenchTest_6: 8 MCU
 SG_ DCU_MotorTempEst : 11|8@0+ (1,-40) [-40|215] "degC"  Tester
 SG_ DCU_RotorPosn : 19|12@0+ (1,0) [0|4095] ""  Tester
 SG_ DCU_CapTemp : 39|8@0+ (1,-40) [-40|215] "degC"  Tester
 SG_ DCU_CtlBoardTemp : 47|8@0+ (1,-40) [-40|215] "degC"  Tester

BO_ 2683306158 DCU_BenchTest_7: 8 MCU
 SG_ DCU_AHFUpShiftSt : 4|1@0+ (1,0) [0|1] ""  Tester
 SG_ DCU_AHFDownShiftSt : 5|1@0+ (1,0) [0|1] ""  Tester
 SG_ DCU_PTCUpShiftSt : 6|1@0+ (1,0) [0|1] ""  Tester
 SG_ DCU_PTCDownShiftSt : 7|1@0+ (1,0) [0|1] ""  Tester
 SG_ DCU_PTCInterTemp : 3|9@0+ (1,-40) [-40|472] "degC"  Tester
 SG_ DCU_PTCMOSTemp : 23|8@0+ (1,-40) [-40|215] "degC"  Tester
 SG_ DCU_AHFCurrentReq : 31|11@0+ (1,0) [0|2047] "A"  Tester
 SG_ DCU_AHFCurrentAct : 36|11@0+ (1,0) [0|2047] "A"  Tester
 SG_ DCU_FPWMMultiple : 60|4@0+ (1,0) [0|15] ""  Tester
 SG_ DCU_PTCHeatCurrent : 55|11@0+ (0.1,-102.3) [-102.3|102.3] "A"  Tester

BO_ 2683306145 DCU_DEBUG_1: 8 MCU
 SG_ DCU_ID : 7|16@0+ (1,0) [0|65535] ""  Tester
 SG_ DCU_Swversion : 23|16@0+ (1,0) [0|65535] ""  Tester
 SG_ DCU_Hwversion : 39|16@0+ (1,0) [0|65535] ""  Tester
 SG_ DCU_SendDataSt : 53|1@0+ (1,0) [0|1] ""  Tester
 SG_ DCU_StoreDataSt : 55|2@0+ (1,0) [0|3] ""  Tester
 SG_ DCU_OffsetAngle : 51|12@0+ (1,0) [0|4095] ""  Tester

BO_ 2683306146 DCU_DEBUG_2: 8 MCU
 SG_ DCU_Fault1_Debug : 7|32@0+ (1,0) [0|1073741823] ""  Tester
 SG_ DCU_Fault2_Debug : 39|32@0+ (1,0) [0|1073741823] ""  Tester

BO_ 2683306147 DCU_DEBUG_3: 8 MCU
 SG_ DCU_Fault3_Debug : 7|32@0+ (1,0) [0|1073741823] ""  Tester
 SG_ DCU_Fault4_Debug : 39|32@0+ (1,0) [0|1073741823] ""  Tester

BO_ 2683306148 DCU_DEBUG_4: 8 MCU
 SG_ DCU_Fault5_Debug : 7|32@0+ (1,0) [0|1073741823] ""  Tester
 SG_ DCU_Fault6_Debug : 39|32@0+ (1,0) [0|1073741823] ""  Tester

BO_ 2683306149 DCU_DEBUG_5: 8 MCU
 SG_ DCU_FaultInfo7_Debug : 7|32@0+ (1,0) [0|1073741823] ""  Tester
 SG_ DCU_FaultInfo8_Debug : 39|32@0+ (1,0) [0|1073741823] ""  Tester

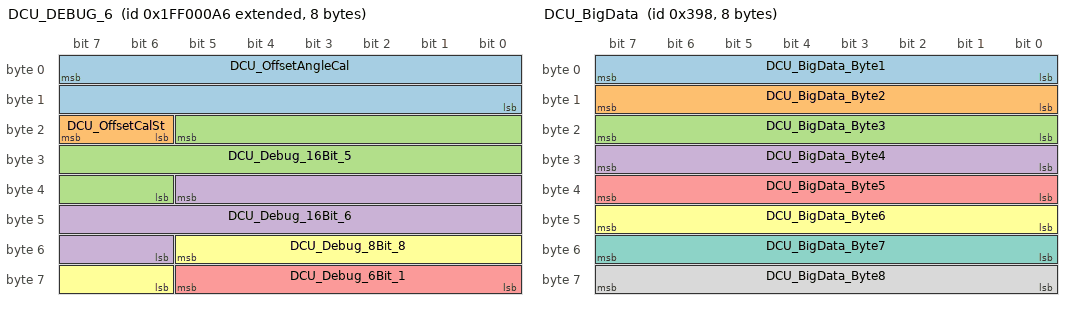
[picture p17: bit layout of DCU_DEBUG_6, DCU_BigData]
BO_ 2683306150 DCU_DEBUG_6: 8 MCU
 SG_ DCU_OffsetAngleCal : 7|16@0+ (1,0) [0|65535] ""  Tester
 SG_ DCU_OffsetCalSt : 23|2@0+ (1,0) [0|3] ""  Tester
 SG_ DCU_Debug_16Bit_5 : 21|16@0+ (1,0) [0|65535] ""  Tester
 SG_ DCU_Debug_16Bit_6 : 37|16@0+ (1,0) [0|65535] ""  Tester
 SG_ DCU_Debug_6Bit_1 : 61|6@0+ (1,0) [0|127] ""  Tester
 SG_ DCU_Debug_8Bit_8 : 53|8@0+ (1,0) [0|255] ""  Tester

BO_ 2683306151 DCU_DEBUG_7: 8 MCU
 SG_ DCU_BSWVersion : 7|16@0+ (1,0) [0|65535] ""  Tester
 SG_ DCU_SWConfig : 23|32@0+ (1,0) [0|4294967295] ""  Tester
 SG_ DCU_HWConfig : 55|16@0+ (1,0) [0|65535] ""  Tester

BO_ 555 DCU_EOP_1: 8 MCU
 SG_ DCU_EOP_SpdSet : 7|12@0+ (1,0) [0|4000] "rpm"  GWM,TEL,EOP
 SG_ DCU_EOP_OilTempAct : 23|8@0+ (1,-40) [-40|180] "degC"  GWM,TEL,EOP
 SG_ DCU_EOP_TrqAntiJerk : 31|8@0+ (1,-127) [-127|128] "Nm"  GWM,TEL,EOP
 SG_ DCU_EOP_stTorqLmtTsc : 39|20@0+ (1,0) [0|1048575] ""  GWM,TEL,EOP
 SG_ DCU_EOP_1_MsgCounter : 51|4@0+ (1,0) [0|15] ""  GWM,TEL,EOP
 SG_ DCU_EOP_1_Checksum : 63|8@0+ (1,0) [0|255] ""  GWM,TEL,EOP

BO_ 920 DCU_BigData: 8 MCU
 SG_ DCU_BigData_Byte1 : 7|8@0+ (1,0) [0|255] ""  GWM,TEL
 SG_ DCU_BigData_Byte2 : 15|8@0+ (1,0) [0|255] ""  GWM,TEL
 SG_ DCU_BigData_Byte3 : 23|8@0+ (1,0) [0|255] ""  GWM,TEL
 SG_ DCU_BigData_Byte4 : 31|8@0+ (1,0) [0|255] ""  GWM,TEL
 SG_ DCU_BigData_Byte5 : 39|8@0+ (1,0) [0|255] ""  GWM,TEL
 SG_ DCU_BigData_Byte6 : 47|8@0+ (1,0) [0|255] ""  GWM,TEL
 SG_ DCU_BigData_Byte7 : 55|8@0+ (1,0) [0|255] ""  GWM,TEL
 SG_ DCU_BigData_Byte8 : 63|8@0+ (1,0) [0|255] ""  GWM,TEL

BO_ 699 NIDU_BigData: 8 MCU
 SG_ NIDU_BigDataNo M : 7|8@0+ (1,0) [0|255] ""  GWM
 SG_ DCU_Fault1 m1 : 15|16@0+ (1,0) [0|65535] ""  GWM
 SG_ DCU_Fault2 m1 : 31|16@0+ (1,0) [0|65535] ""  GWM
 SG_ DCU_Fault3 m1 : 47|16@0+ (1,0) [0|65535] ""  GWM
 SG_ DCU_Fault4 m2 : 15|16@0+ (1,0) [0|65535] ""  GWM
 SG_ DCU_FusaFaultInfo7 m2 : 31|32@0+ (1,0) [0|1073741823] ""  GWM
 SG_ DCU_FusaFaultInfo8 m3 : 15|32@0+ (1,0) [0|1073741823] ""  GWM

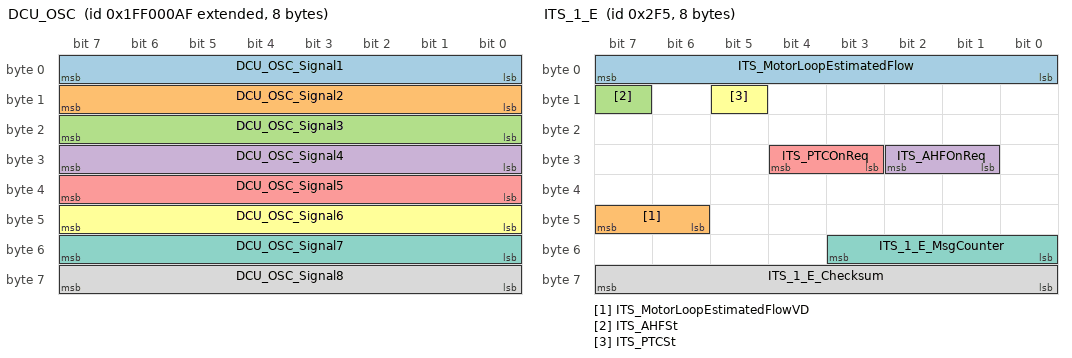
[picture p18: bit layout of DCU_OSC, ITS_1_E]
BO_ 2683306159 DCU_OSC: 8 MCU
 SG_ DCU_OSC_Signal1 : 7|8@0+ (1,0) [0|255] ""  Tester
 SG_ DCU_OSC_Signal2 : 15|8@0+ (1,0) [0|255] ""  Tester
 SG_ DCU_OSC_Signal3 : 23|8@0+ (1,0) [0|255] ""  Tester
 SG_ DCU_OSC_Signal4 : 31|8@0+ (1,0) [0|255] ""  Tester
 SG_ DCU_OSC_Signal5 : 39|8@0+ (1,0) [0|255] ""  Tester
 SG_ DCU_OSC_Signal6 : 47|8@0+ (1,0) [0|255] ""  Tester
 SG_ DCU_OSC_Signal7 : 55|8@0+ (1,0) [0|255] ""  Tester
 SG_ DCU_OSC_Signal8 : 63|8@0+ (1,0) [0|255] ""  Tester

BO_ 556 EOP_1: 8 EOP
 SG_ EOP_SpdAct : 7|16@0+ (1,0) [0|4000] "rpm"  GWM,TEL,MCU,DCU
 SG_ EOP_IdcAct : 23|8@0+ (0.2,0) [0|25] "A"  GWM,TEL,MCU,DCU
 SG_ EOP_CANCommunicationFailure : 24|1@0+ (1,0) [0|1] ""  GWM,TEL,MCU,DCU
 SG_ EOP_SensorFailure : 25|1@0+ (1,0) [0|1] ""  GWM,TEL,MCU,DCU
 SG_ EOP_DriverCircuitFailure : 26|1@0+ (1,0) [0|1] ""  GWM,TEL,MCU,DCU
 SG_ EOP_OverTemperature : 27|1@0+ (1,0) [0|1] ""  GWM,TEL,MCU,DCU
 SG_ EOP_OverVoltage : 28|1@0+ (1,0) [0|1] ""  GWM,TEL,MCU,DCU
 SG_ EOP_LowVoltage : 29|1@0+ (1,0) [0|1] ""  GWM,TEL,MCU,DCU
 SG_ EOP_OverCurrent : 30|1@0+ (1,0) [0|1] ""  GWM,TEL,MCU,DCU
 SG_ EOP_MotorStallingFailure : 31|1@0+ (1,0) [0|1] ""  GWM,TEL,MCU,DCU
 SG_ EOP_ErrLevel : 43|4@0+ (1,0) [0|7] ""  GWM,TEL,MCU,DCU
 SG_ EOP_LimitCurrentFlag : 44|1@0+ (1,0) [0|1] ""  GWM,TEL,MCU,DCU
 SG_ EOP_SelfCheckSt : 46|2@0+ (1,0) [0|3] ""  GWM,TEL,MCU,DCU
 SG_ EOP_UdcAct : 39|9@0+ (0.1,0) [0|25] "V"  GWM,TEL,MCU,DCU
 SG_ EOP_HighTempDePwrFlag : 52|1@0+ (1,0) [0|1] ""  GWM,TEL,MCU,DCU
 SG_ EOP_1_MsgCounter : 51|4@0+ (1,0) [0|15] ""  GWM,TEL,MCU,DCU
 SG_ EOP_1_Checksum : 63|8@0+ (1,0) [0|255] ""  GWM,TEL,MCU,DCU

BO_ 757 ITS_1_E: 8 VDC_ITS
 SG_ ITS_MotorLoopEstimatedFlow : 7|8@0+ (0.1,0) [0|20] "L/min"  DCU,MCU,VCU
 SG_ ITS_MotorLoopEstimatedFlowVD : 47|2@0+ (1,0) [0|3] ""  GWM,TEL,MCU,DCU,VCU
 SG_ ITS_AHFSt : 15|1@0+ (1,0) [0|1] ""  GWM,TEL,MCU,DCU,VCU
 SG_ ITS_AHFOnReq : 26|2@0+ (1,0) [0|3] ""  GWM,TEL,MCU,DCU,VCU
 SG_ ITS_PTCOnReq : 28|2@0+ (1,0) [0|3] ""  GWM,TEL,MCU,DCU
 SG_ ITS_PTCSt : 13|1@0+ (1,0) [0|1] ""  GWM,TEL,MCU,DCU,VCU
 SG_ ITS_1_E_MsgCounter : 51|4@0+ (1,0) [0|15] ""  GWM,TEL,MCU,DCU
 SG_ ITS_1_E_Checksum : 63|8@0+ (1,0) [0|255] ""  GWM,TEL,MCU,DCU

BO_ 831 ITS_2_E: 8 VDC_ITS
 SG_ ITS_ECPPwrConsump : 50|11@0+ (10,0) [0|20320] "w"  GWM,TEL,BMS,MCU,DCU,IPS,VCU

BO_ 834 ITS_3_E: 8 VDC_ITS
 SG_ ITS_MotorInletTemp : 7|16@0+ (0.1,-50) [-50|150] "degC"  GWM,TEL,MCU,DCU,VCU
 SG_ ITS_MotorInletTempErr : 40|1@0+ (1,0) [0|1] ""  DCU,MCU,VCU,TEL,GWM
 SG_ ITS_3_E_MsgCounter : 51|4@0+ (1,0) [0|15] ""  DCU,MCU,TEL,GWM
 SG_ ITS_3_E_Checksum : 63|8@0+ (1,0) [0|255] ""  DCU,MCU,TEL,GWM

BO_ 842 ITS_4_E: 8 VDC_ITS
 SG_ ITS_BattOutletTsnsrErrCode : 7|2@0+ (1,0) [0|3] ""  GWM,TEL,BMS,MCU,DCU
 SG_ ITS_ChlrExvErrCode : 3|9@0+ (1,0) [0|511] ""  GWM,TEL,BMS,MCU,DCU
 SG_ ITS_RawExterTempVD : 25|1@0+ (1,0) [0|1] ""  GWM,TEL,BMS,MCU,DCU,VCU
 SG_ ITS_PTCTargetDuty : 30|5@0+ (5,0) [0|100] "%"  GWM,TEL,MCU,DCU
 SG_ ITS_RawExterTemp : 39|8@0+ (0.5,-40) [-40|87.5] "degC"  GWM,TEL,BMS,MCU,DCU,VCU

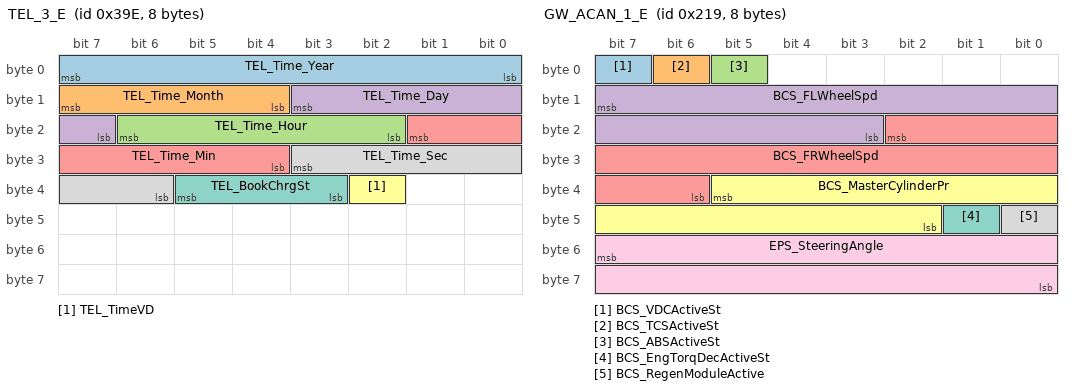
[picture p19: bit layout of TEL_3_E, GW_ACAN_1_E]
BO_ 926 TEL_3_E: 8 GWM
 SG_ TEL_Time_Year : 7|8@0+ (1,2000) [2000|2255] "y"  ITS,BMS,MCU,DCU,IPS,EOP,IPU,LPC,VCU,VDC
 SG_ TEL_Time_Month : 15|4@0+ (1,0) [1|12] "m"  ITS,BMS,MCU,DCU,IPS,EOP,IPU,LPC,VCU,VDC
 SG_ TEL_Time_Hour : 22|5@0+ (1,0) [0|23] "h"  ITS,BMS,MCU,DCU,IPS,EOP,IPU,LPC,VCU,VDC
 SG_ TEL_Time_Day : 11|5@0+ (1,0) [1|31] "d"  ITS,BMS,MCU,DCU,IPS,EOP,IPU,LPC,VCU,VDC
 SG_ TEL_Time_Min : 17|6@0+ (1,0) [0|59] "min"  ITS,BMS,MCU,DCU,IPS,EOP,IPU,LPC,VCU,VDC
 SG_ TEL_TimeVD : 34|1@0+ (1,0) [0|1] ""  ITS,BMS,MCU,EOP,VCU,VDC
 SG_ TEL_BookChrgSt : 37|3@0+ (1,0) [0|7] ""  ITS,BMS,MCU,EOP,VCU,VDC
 SG_ TEL_Time_Sec : 27|6@0+ (1,0) [0|59] "s"  ITS,BMS,MCU,DCU,IPS,EOP,IPU,LPC,VCU,VDC

BO_ 2683306160 Err_OSCManage: 8 Tester
 SG_ Err_OSCManage_Signal2 : 15|8@0+ (1,0) [0|255] ""  MCU
 SG_ Err_OSCManage_Signal1 : 7|8@0+ (1,0) [0|255] ""  MCU

BO_ 2015 Func_Diag_Rx: 8 Tester
 SG_ Func_Diag_Rx : 7|64@0+ (1,0) [0|1.84467440737096E+019] ""  ITS,BMS,MCU,DCU,IPS,EOP,IPU,LPC,VCU,VDC,EVCC

BO_ 1790 NIDU_Diag_Tx: 8 MCU
 SG_ NIDU_Diag_Response : 7|64@0+ (1,0) [0|1.84467440737096E+019] ""  Tester

BO_ 537 GW_ACAN_1_E: 8 GWM
 SG_ BCS_VDCActiveSt : 7|1@0+ (1,0) [0|1] ""  MCU,DCU
 SG_ BCS_TCSActiveSt : 6|1@0+ (1,0) [0|1] ""  MCU,DCU
 SG_ BCS_ABSActiveSt : 5|1@0+ (1,0) [0|1] ""  MCU,DCU
 SG_ BCS_FLWheelSpd : 15|13@0+ (0.05625,0) [0|240] "km/h"  MCU,DCU
 SG_ BCS_FRWheelSpd : 18|13@0+ (0.05625,0) [0|240] "km/h"  MCU,DCU
 SG_ BCS_MasterCylinderPr : 37|12@0+ (0.1,0) [0|250] "bar"  MCU,DCU
 SG_ BCS_EngTorqDecActiveSt : 41|1@0+ (1,0) [0|1] ""  MCU,DCU
 SG_ BCS_RegenModuleActive : 40|1@0+ (1,0) [0|1] ""  MCU,DCU
 SG_ EPS_SteeringAngle : 55|16@0+ (0.1,-780) [-780|779.9] "deg"  MCU,DCU

BO_ 806 GW_ACU_29_B_E: 8 GWM
 SG_ ACU_ACChgCurCfg : 44|5@0+ (1,0) [0|31] ""  TEL,MCU,IPS

BO_ 885 GW_BCM_2_E: 8 GWM
 SG_ BCM_KeySt : 9|2@0+ (1,0) [0|3] ""  ITS,BMS,MCU,DCU,IPS,IPU,LPC,VCU,VDC

BO_ 1507 VCU_NM_ECAN: 8 VDC_VCU
 SG_ VCU_NMNodeAddress : 7|8@0+ (1,0) [0|255] ""  GWM,TEL,ITS,BMS,MCU,DCU,IPS,EOP,IPU,LPC,VCU,VDC,EVCC
 SG_ VCU_NMDataField1 : 15|8@0+ (1,0) [0|255] ""  GWM,TEL,ITS,BMS,MCU,DCU,IPS,EOP,IPU,LPC,VCU,VDC,EVCC
 SG_ VCU_NMWakeupOrigin_ECAN : 23|8@0+ (1,0) [0|255] ""  GWM,TEL,ITS,BMS,MCU,DCU,IPS,EOP,IPU,LPC,VCU,VDC,EVCC
 SG_ VCU_SubNetWakeRq : 31|8@0+ (1,0) [0|255] ""  GWM,TEL,ITS,BMS,MCU,DCU,IPS,EOP,IPU,LPC,VCU,VDC,EVCC
 SG_ VCU_NMKeepingOrigin : 39|8@0+ (1,0) [0|255] ""  GWM,TEL,ITS,BMS,MCU,DCU,IPS,EOP,IPU,LPC,VCU,VDC,EVCC
 SG_ VCU_NMDataField2 : 47|24@0+ (1,0) [0|16777215] ""  GWM,TEL,ITS,BMS,MCU,DCU,IPS,EOP,IPU,LPC,VCU,VDC,EVCC

BO_ 1506 BMS_NM: 8 BMS
 SG_ BMS_NodeAddress : 7|8@0+ (1,0) [0|255] ""  GWM,TEL,ITS,BMS,MCU,DCU,IPS,EOP,IPU,LPC,VCU,VDC,EVCC
 SG_ BMS_NMDataField1 : 15|8@0+ (1,0) [0|255] ""  GWM,TEL,ITS,BMS,MCU,DCU,IPS,EOP,IPU,LPC,VCU,VDC,EVCC
 SG_ BMS_NMWakeupOrigin : 23|8@0+ (1,0) [0|255] ""  GWM,TEL,ITS,BMS,MCU,DCU,IPS,EOP,IPU,LPC,VCU,VDC,EVCC
 SG_ BMS_SubNetWakeRq : 31|8@0+ (1,0) [0|255] ""  GWM,TEL,ITS,BMS,MCU,DCU,IPS,EOP,IPU,LPC,VCU,VDC,EVCC
 SG_ BMS_NMKeepingOrigin : 39|8@0+ (1,0) [0|255] ""  GWM,TEL,ITS,BMS,MCU,DCU,IPS,EOP,IPU,LPC,VCU,VDC,EVCC
 SG_ BMS_NMDataField2 : 47|24@0+ (1,0) [0|16777215] ""  GWM,TEL,ITS,BMS,MCU,DCU,IPS,EOP,IPU,LPC,VCU,VDC,EVCC

BO_ 1510 IPS_NM: 8 IPS
 SG_ IPS_NMNodeAddress : 7|8@0+ (1,0) [0|255] ""  GWM,TEL,ITS,BMS,MCU,DCU,IPS,EOP,IPU,LPC,VCU,VDC,EVCC
 SG_ IPS_NMDataField1 : 15|8@0+ (1,0) [0|255] ""  GWM,TEL,ITS,BMS,MCU,DCU,IPS,EOP,IPU,LPC,VCU,VDC,EVCC
 SG_ IPS_NMWakeupOrigin : 23|8@0+ (1,0) [0|255] ""  GWM,TEL,ITS,BMS,MCU,DCU,IPS,EOP,IPU,LPC,VCU,VDC,EVCC
 SG_ IPS_SubNetWakeRq : 31|8@0+ (1,0) [0|255] ""  GWM,TEL,ITS,BMS,MCU,DCU,IPS,EOP,IPU,LPC,VCU,VDC,EVCC
 SG_ IPS_NMKeepingOrigin : 39|8@0+ (1,0) [0|255] ""  GWM,TEL,ITS,BMS,MCU,DCU,IPS,EOP,IPU,LPC,VCU,VDC,EVCC
 SG_ IPS_NMDataField2 : 47|24@0+ (1,0) [0|16777215] ""  GWM,TEL,ITS,BMS,MCU,DCU,IPS,EOP,IPU,LPC,VCU,VDC,EVCC

BO_ 1533 EVCC_NM: 8 EVCC
 SG_ EVCC_NMNodeAddress : 7|8@0+ (1,0) [0|255] ""  GWM,TEL,ITS,BMS,MCU,DCU,IPS,EOP,IPU,LPC,VCU,VDC
 SG_ EVCC_NMDataField1 : 15|8@0+ (1,0) [0|255] ""  GWM,TEL,ITS,BMS,MCU,DCU,IPS,EOP,IPU,LPC,VCU,VDC
 SG_ EVCC_NMWakeupOrigin : 23|8@0+ (1,0) [0|255] ""  GWM,TEL,ITS,BMS,MCU,DCU,IPS,EOP,IPU,LPC,VCU,VDC
 SG_ EVCC_SubNetWakeRq : 31|8@0+ (1,0) [0|255] ""  GWM,TEL,ITS,BMS,MCU,DCU,IPS,EOP,IPU,LPC,VCU,VDC
 SG_ EVCC_NMKeepingOrigin : 39|8@0+ (1,0) [0|255] ""  GWM,TEL,ITS,BMS,MCU,DCU,IPS,EOP,IPU,LPC,VCU,VDC
 SG_ EVCC_NMDataField2 : 47|24@0+ (1,0) [0|16777215] ""  GWM,TEL,ITS,BMS,MCU,DCU,IPS,EOP,IPU,LPC,VCU,VDC

BO_ 1376 EOP_NM: 8 EOP
 SG_ EOP_NMNodeAddress : 7|8@0+ (1,0) [0|255] ""  GWM,TEL,ITS,BMS,MCU,DCU,IPS,EOP,VCU,VDC,EVCC
 SG_ EOP_NMDataField1 : 15|8@0+ (1,0) [0|255] ""  GWM,TEL,ITS,BMS,MCU,DCU,IPS,EOP,VCU,VDC,EVCC
 SG_ EOP_NMWakeupOrigin : 23|8@0+ (1,0) [0|255] ""  GWM,TEL,ITS,BMS,MCU,DCU,IPS,EOP,VCU,VDC,EVCC
 SG_ EOP_SubNetWakeRq : 31|8@0+ (1,0) [0|255] ""  GWM,TEL,ITS,BMS,MCU,DCU,IPS,EOP,VCU,VDC,EVCC
 SG_ EOP_NMKeepingOrigin : 39|8@0+ (1,0) [0|255] ""  GWM,TEL,ITS,BMS,MCU,DCU,IPS,EOP,VCU,VDC,EVCC
 SG_ EOP_NMDataField2 : 47|24@0+ (1,0) [0|16777215] ""  GWM,TEL,ITS,BMS,MCU,DCU,IPS,EOP,VCU,VDC,EVCC

BO_ 1406 NIDU_NM: 8 MCU
 SG_ NIDU_NMNodeAddress : 7|8@0+ (1,0) [0|255] ""  GWM,TEL,ITS,BMS,MCU,DCU,IPS,EOP,VCU,VDC,EVCC
 SG_ NIDU_NMDataField1 : 15|8@0+ (1,0) [0|255] ""  GWM,TEL,ITS,BMS,MCU,DCU,IPS,EOP,VCU,VDC,EVCC
 SG_ NIDU_NMWakeupOrigin : 23|8@0+ (1,0) [0|255] ""  GWM,TEL,ITS,BMS,MCU,DCU,IPS,EOP,VCU,VDC,EVCC
 SG_ NIDU_SubNetWakeRq : 31|8@0+ (1,0) [0|255] ""  GWM,TEL,ITS,BMS,MCU,DCU,IPS,EOP,VCU,VDC,EVCC
 SG_ NIDU_NMKeepingOrigin : 39|8@0+ (1,0) [0|255] ""  GWM,TEL,ITS,BMS,MCU,DCU,IPS,EOP,VCU,VDC,EVCC
 SG_ NIDU_NMDataField2 : 47|24@0+ (1,0) [0|16777215] ""  GWM,TEL,ITS,BMS,MCU,DCU,IPS,EOP,VCU,VDC,EVCC

BO_ 1508 DCU_NM: 8 DCU
 SG_ DCU_NMNodeAddress : 7|8@0+ (1,0) [0|255] ""  GWM,TEL,ITS,BMS,MCU,DCU,IPS,EOP,VCU,VDC,EVCC
 SG_ DCU_NMDataField1 : 15|8@0+ (1,0) [0|255] ""  GWM,TEL,ITS,BMS,MCU,DCU,IPS,EOP,VCU,VDC,EVCC
 SG_ DCU_NMWakeupOrigin : 23|8@0+ (1,0) [0|255] ""  GWM,TEL,ITS,BMS,MCU,DCU,IPS,EOP,VCU,VDC,EVCC
 SG_ DCU_SubNetWakeRq : 31|8@0+ (1,0) [0|255] ""  GWM,TEL,ITS,BMS,MCU,DCU,IPS,EOP,VCU,VDC,EVCC
 SG_ DCU_NMKeepingOrigin : 39|8@0+ (1,0) [0|255] ""  GWM,TEL,ITS,BMS,MCU,DCU,IPS,EOP,VCU,VDC,EVCC
 SG_ DCU_NMDataField2 : 47|24@0+ (1,0) [0|16777215] ""  GWM,TEL,ITS,BMS,MCU,DCU,IPS,EOP,VCU,VDC,EVCC

BO_ 1531 ITS_NM: 8 ITS
 SG_ ITS_NMNodeAddress : 7|8@0+ (1,0) [0|255] ""  GWM,TEL,ITS,BMS,MCU,DCU,IPS,EOP,VCU,VDC,EVCC
 SG_ ITS_NMDataField1 : 15|8@0+ (1,0) [0|255] ""  GWM,TEL,ITS,BMS,MCU,DCU,IPS,EOP,VCU,VDC,EVCC
 SG_ ITS_NMWakeupOrigin : 23|8@0+ (1,0) [0|255] ""  GWM,TEL,ITS,BMS,MCU,DCU,IPS,EOP,VCU,VDC,EVCC
 SG_ ITS_SubNetWakeRq : 31|8@0+ (1,0) [0|255] ""  GWM,TEL,ITS,BMS,MCU,DCU,IPS,EOP,VCU,VDC,EVCC
 SG_ ITS_NMKeepingOrigin : 39|8@0+ (1,0) [0|255] ""  GWM,TEL,ITS,BMS,MCU,DCU,IPS,EOP,VCU,VDC,EVCC
 SG_ ITS_NMDataField2 : 47|24@0+ (1,0) [0|16777215] ""  GWM,TEL,ITS,BMS,MCU,DCU,IPS,EOP,VCU,VDC,EVCC

BO_ 1509 GCU_NM: 8 IPU
 SG_ GCU_NodeAddress : 7|8@0+ (1,0) [0|255] ""  BMS,MCU,DCU,IPS,EOP,LPC,VCU,VDC,EVCC
 SG_ GCU_NMDataField1 : 15|8@0+ (1,0) [0|255] ""  BMS,MCU,DCU,IPS,EOP,LPC,VCU,VDC,EVCC
 SG_ GCU_NMWakeupOrignin : 23|8@0+ (1,0) [0|255] ""  BMS,MCU,DCU,IPS,EOP,LPC,VCU,VDC,EVCC
 SG_ GCU_SubNetWakeRq : 31|8@0+ (1,0) [0|255] ""  BMS,MCU,DCU,IPS,EOP,LPC,VCU,VDC,EVCC
 SG_ GCU_NMKeepingOrigin : 39|8@0+ (1,0) [0|255] ""  BMS,MCU,DCU,IPS,EOP,LPC,VCU,VDC,EVCC
 SG_ GCU_NMDataField2 : 47|24@0+ (1,0) [0|16777215] ""  BMS,MCU,DCU,IPS,EOP,LPC,VCU,VDC,EVCC

BO_ 1359 GWM_NM_ECAN: 8 GWM
 SG_ GWM_NMNodeAddress : 7|8@0+ (1,0) [0|255] ""  TEL,ITS,BMS,MCU,DCU,IPS,EOP,IPU,LPC,VCU,VDC,EVCC
 SG_ GWM_NMDataField1 : 15|8@0+ (1,0) [0|255] ""  TEL,ITS,BMS,MCU,DCU,IPS,EOP,IPU,LPC,VCU,VDC,EVCC
 SG_ GWM_NMWakeupOrigin_ECAN : 23|8@0+ (1,0) [0|255] ""  TEL,ITS,BMS,MCU,DCU,IPS,EOP,IPU,LPC,VCU,VDC,EVCC
 SG_ GWM_SubNetWakeRq : 31|8@0+ (1,0) [0|255] ""  TEL,ITS,BMS,MCU,DCU,IPS,EOP,IPU,LPC,VCU,VDC,EVCC
 SG_ GWM_NMKeepingOrigin : 39|8@0+ (1,0) [0|255] ""  TEL,ITS,BMS,MCU,DCU,IPS,EOP,IPU,LPC,VCU,VDC,EVCC
 SG_ GWM_NMKeepingOrigin2 : 47|8@0+ (1,0) [0|255] ""  TEL,ITS,BMS,MCU,DCU,IPS,EOP,IPU,LPC,VCU,VDC,EVCC
 SG_ GWM_NMDataField2 : 55|16@0+ (1,0) [0|65535] ""  TEL,ITS,BMS,MCU,DCU,IPS,EOP,IPU,LPC,VCU,VDC,EVCC

BO_ 1662 NIDU_Phys_Diag_Rx: 8 Tester
 SG_ NIDU_Diag_Request : 7|64@0+ (1,0) [0|1.84467440737096E+019] ""  MCU

CM_ SG_ 864 VCU_AHFShutImme "AHF immediate shutdown request";
CM_ SG_ 864 VCU_AHFDelayEn "AHF OFF or downshift should be delayed if enable this signal, othewise not";
CM_ SG_ 864 VCU_AHFActivationSt "Indicate AHF activated or not";
CM_ SG_ 864 VCU_PlgConnSt "Charge connector  connected Status";
CM_ SG_ 438 VCU_DCU_SpdSet "target speed for drive motor, only with openclutch";
CM_ SG_ 438 VCU_CrntGearLvl_E "VCU current carry out gear level";
CM_ SG_ 438 VCU_DCU_SurgeDamperStReq "Desired state for damping control feature";
CM_ SG_ 438 VCU_DCU_TorqSet "target torque for drive motor";
CM_ SG_ 438 VCU_DCU_SurgeDamperFactor "Dynamic factor used to convert vibrations due to speed into equivalent damping";
CM_ SG_ 438 VCU_DCU_VehPwrAbnormal "The motor power consumption is inconsistent with the VCU request";
CM_ SG_ 438 VCU_4_E_MsgCounter "The MessageCounter is a 0 ~ 15 counter, increased of one unit on every message transmission";
CM_ SG_ 438 VCU_DCU_ModeReq "requestable state/mode of drive motor";
CM_ SG_ 438 VCU_4_E_Checksum "Message checksum CRC in accordance with J1850";
CM_ SG_ 680 VCU_IPS_DCDCVoltLvSet "requestable target output DC voltage at LV of DCDC";
CM_ SG_ 680 VCU_IPS_DCDCModeReq "requestable target mode for DCDC ";
CM_ SG_ 680 VCU_IPS_DCDCLvCurrLim "Limitation of DCDC LV output current. Current is positive, if energy flow is from IPS into the LV system.";
CM_ SG_ 680 VCU_5_E_MsgCounter "The MessageCounter is a 0 ~ 15 counter, increased of one unit on every message transmission";
CM_ SG_ 680 VCU_5_E_Checksum "Message checksum CRC in accordance with J1850";
CM_ SG_ 673 VCU_HvilSt "HVIL status";
CM_ SG_ 673 VCU_BMS_SepaHeatEn "enable or disable separate heat request from BMS";
CM_ SG_ 673 VCU_IPS_OBCModeReq "OBC mode request (0: no request, sleep indication allowed)";
CM_ SG_ 673 VCU_IPS_OBCDsChDCCurrLim "max allowed (limit) discharging current on DC side of OBC";
CM_ SG_ 673 VCU_6_E_MsgCounter "The MessageCounter is a 0 ~ 15 counter, increased of one unit on every message transmission";
CM_ SG_ 673 VCU_6_E_Checksum "Message checksum CRC in accordance with J1850";
CM_ SG_ 419 VCU_DCU_IdcMax "max current for drive torque";
CM_ SG_ 419 VCU_DCU_IdcMin "max current for regenerative torque";
CM_ SG_ 419 VCU_DCU_UdcMin "min voltage limt for inverter for torque generation (driving)";
CM_ SG_ 419 VCU_DCU_UdcMax "max.voltage limit for the inverter for el. energy generation (recuperation)";
CM_ SG_ 419 VCU_12_E_MsgCounter "The MessageCounter is a 0 ~ 15 counter, increased of one unit on every message transmission";
CM_ SG_ 419 VCU_12_E_Checksum "Message checksum CRC in accordance with J1850";
CM_ SG_ 371 VCU_DCU_TorqMin "max limit of negative torque for drive motor";
CM_ SG_ 371 VCU_DCU_MaxTorqGradient "Maximum change rate of the torque demand";
CM_ SG_ 371 VCU_DCU_TorqMax "max limit of positive torque for drive motor";
CM_ SG_ 371 VCU_DCU_MaxTorqDampgCtl "Maximum limit for damping torque that shall be applied (in Nm).";
CM_ SG_ 371 VCU_13_E_MsgCounter "The MessageCounter is a 0 ~ 15 counter, increased of one unit on every message transmission";
CM_ SG_ 371 VCU_13_E_Checksum "Message checksum CRC in accordance with J1850";
CM_ SG_ 893 VCU_IPS_OBCChgVoltReq "Required AC charge valtage from IPS_OBC";
CM_ SG_ 893 VCU_IPS_OBCChgCurrReq "Required AC charge current  from IPS_OBC";
CM_ SG_ 893 VCU_16_E_MsgCounter "The MessageCounter is a 0 ~ 15 counter, increased of one unit on every message transmission";
CM_ SG_ 893 VCU_16_E_Checksum "Message checksum CRC in accordance with J1850";
CM_ SG_ 779 VCU_AHFActivatePwr "AHF activated judgment condition";
CM_ SG_ 779 VCU_DCU_IdcMeasure "DCU dc current mesured value";
CM_ SG_ 779 VCU_SwapHvBattModeSt "VCU swap Hvbattery mode status";
CM_ SG_ 779 VCU_SwapHvBattModeStVD "VCU swap Hvbattery mode statue VD";
CM_ SG_ 964 VCU_22_E_MsgCounter "The MessageCounter is a 0 ~ 15 counter, increased of one unit on every message transmission";
CM_ SG_ 964 VCU_22_E_Checksum "Message checksum CRC in accordance with J1850";
CM_ SG_ 983 VCU_TEL_AccPedalActPst "Current accelerate pedal actual position";
CM_ SG_ 357 VCU_DCU_SpdLmt "Speed limit for drive motor";
CM_ SG_ 357 VCU_BrkPedPst_E "Current brake pedal position";
CM_ SG_ 357 VCU_EMS_AccPedalActPst_E "Current accelerate pedal actual position";
CM_ SG_ 678 BMS_BattCurr "actual current of battery";
CM_ SG_ 678 BMS_BattVolt "actual voltage of battery pack (inside of main relay)";
CM_ SG_ 678 BMS_DcChargerSt "DC charger connet link state";
CM_ SG_ 678 BMS_DCUBattSt "working state of battery system for DCU";
CM_ SG_ 678 BMS_PwrDwnReq "Emergency power-off warning. when the HV battery needs an emergency power-off, this signal is used to notify each HV node. The received node should reduce their power  to 0  as soon as possible.";
CM_ SG_ 678 BMS_1_MsgCounter "The MessageCounter is a 0 ~ 15 counter, increased of one unit on every message transmission";
CM_ SG_ 678 BMS_1_Checksum "Message checksum CRC in accordance with J1850";
CM_ SG_ 887 BMS_DCVoltRx "voltage received from DC charger";
CM_ SG_ 887 BMS_DCCurrRx "current received from DC charger";
CM_ SG_ 444 BMS_SepaHeatSt "BMS separate heat heat state";
CM_ SG_ 444 BMS_16_MsgCounter "The MessageCounter is a 0 ~ 15 counter, increased of one unit on every message transmission";
CM_ SG_ 444 BMS_16_Checksum "Message checksum CRC in accordance with J1850";
CM_ SG_ 889 IPS_DCDCModeSt "mode status of DCDC";
CM_ SG_ 889 IPS_HVDCHVilSt "IPS send DC side HVIL status measued by itself";
CM_ SG_ 889 IPS_DCDCVoltLvAct "actual LV voltage at DCDC";
CM_ SG_ 889 IPS_DCDCCurrHvAct "actual (input) current at HV voltageof DCDC";
CM_ SG_ 889 IPS_DCDCCurrLvAct "actual (output) Current at LVvoltage of DCDC";
CM_ SG_ 889 IPS_DCDCTempAct "Actual temperature of DCDC";
CM_ SG_ 889 IPS_DCDC_2_MsgCounter "The MessageCounter is a 0 ~ 15 counter, increased of one unit on every message transmission";
CM_ SG_ 889 IPS_KL15State "IPS or DCDC Enable state";
CM_ SG_ 889 IPS_DCDCVoltHvAct "actual HV voltage at DCDC";
CM_ SG_ 889 IPS_DCDC_2_Checksum "Message checksum CRC in accordance with J1850";
CM_ SG_ 897 IPS_DCDCKL30Volt "IPS or DCDC LV power supply voltage";
CM_ SG_ 897 IPS_DcdcHwSt "tell it is that IPS orDCDC(because they have sameID)";
CM_ SG_ 897 IPS_DCDCFaultLampInd "Warning indicator to lighten faultlamp (Malfunction Indication Lamp,MIL";
CM_ SG_ 897 DCDC_RemoteDiagCode "The flag that ECU need to be remote diagnosed";
CM_ SG_ 897 IPS_DCDCFaultLampIndOperFlag "Operation flag for IPS_DCDCFaultLampInd";
CM_ SG_ 897 IPS_DCDCFaultLampIndFlag "Popup?flag?for??DCDC?error?notice";
CM_ SG_ 897 IPS_DCDCState1 "DCDC state information 1";
CM_ SG_ 897 IPS_DCDCState2 "DCDC state information 2";
CM_ SG_ 897 IPS_DCDCState3 "DCDC state information 3";
CM_ SG_ 897 IPS_DCDCState4 "DCDC state information 4";
CM_ SG_ 897 IPS_DCDCState5 "DCDC state information 5";
CM_ SG_ 897 IPS_DCDCFlowReq "The DCDC required coolant flow speed  (L/min)";
CM_ SG_ 924 IPS_DchgOverload "Discharge Overload";
CM_ SG_ 924 IPS_OBCCC_St "Status of slow charging cable connection (CC) including type of connected cable (charging/V2V, or V2L)";
CM_ SG_ 924 IPS_OBCDschDisable "Status of control pilot signal (CP) for discharging";
CM_ SG_ 924 IPS_OBCModeSt "OBC mode state";
CM_ SG_ 924 IPS_ACHvilSt "IPS send AC side HVIL status measued by itself";
CM_ SG_ 924 IPS_OBCCC_Cap "AC charging capability of the charging cable detected by OBC";
CM_ SG_ 924 IPS_OBCCpS2St "S2 swtich state";
CM_ SG_ 924 IPS_OBCCpFreqSt "CP frequency is in the GB range ";
CM_ SG_ 924 IPS_OBCCPSt "Status of control pilot signal (CP) for charging";
CM_ SG_ 924 IPS_OBCCp_DutyCycle "CP Duty";
CM_ SG_ 924 IPS_OBCCPVolt "CP high level";
CM_ SG_ 924 IPS_OBC_1_MsgCounter "The MessageCounter is a 0 ~ 15 counter, increased of one unit on every message transmission";
CM_ SG_ 924 IPS_OBCStStep "OBC Charging or V2V orV2L state Step";
CM_ SG_ 924 IPS_OBC_1_Checksum "Message checksum CRC in accordance with J1850";
CM_ SG_ 925 IPS_OBCState6 "OBC state information 6";
CM_ SG_ 925 IPS_OBCState7 "OBC state information 7";
CM_ SG_ 925 IPS_OBCState1 "OBC state information 1";
CM_ SG_ 925 IPS_OBCState2 "OBC state information 2";
CM_ SG_ 925 IPS_OBCState3 "OBC state information 3";
CM_ SG_ 925 IPS_OBCState4 "OBC state information 4";
CM_ SG_ 925 IPS_OBCState5 "OBC state information 5";
CM_ SG_ 925 IPS_OBCState8 "OBC state information 8";
CM_ SG_ 917 IPS_OBCUacActL1 "L1 phase voltage";
CM_ SG_ 917 IPS_OBCUacActL2 "L2 phase voltage";
CM_ SG_ 917 IPS_OBCUacActL3 "L3 phase voltage";
CM_ SG_ 917 IPS_OBCCurrActL1 "L1 phase current";
CM_ SG_ 917 IPS_OBCCurrActL2 "L2 phase current";
CM_ SG_ 917 IPS_OBCCurrActL3 "L3 phase current";
CM_ SG_ 917 IPS_OBCCC_Res "CC Resistance value in Ohm";
CM_ SG_ 746 IPS_OBCState9 "OBC state information 9";
CM_ SG_ 746 IPS_OBCChgPwrMax "Available OBC charging power depending on provided current and voltage from charging station, limitations from cable OBC efficiency and OBC derating.";
CM_ SG_ 746 IPS_OBCHvDcCurrAct "OBC HVDC actual current (Positive current+：Charging mode output current from IPS to HVBAT, Negative current-：DisCharging mode input current from HVBAT)";
CM_ SG_ 746 IPS_ChgCurRespAvail "To indicate if Charge current of HV IPS isavailable";
CM_ SG_ 746 IPS_ChgCurResp "Charge current response of IPS for display";
CM_ SG_ 746 IPS_OBCHvDcVoltAct "OBC HVDC voltage";
CM_ SG_ 884 IPS_OBCEngMilLampReq "OBC  request engine MIL lamp on";
CM_ SG_ 884 IPS_OBCFlowReq "The OBC required coolant flow speed  (L/min)";
CM_ SG_ 884 IPS_OBCFaultLampInd "Warning indicator to lighten fault lamp (Malfunction Indication Lamp, MIL";
CM_ SG_ 884 IPS_OBCFaultLampIndOperFlag "Operation flag for  IPS_OBCFaultLampInd";
CM_ SG_ 884 IPS_OBCEnergyDirCap "The capability of energy flow direction of IPS_OBC";
CM_ SG_ 884 IPS_OBCTempAct "OBC internal temperature";
CM_ SG_ 884 IPS_OBCAcIso_Res "AC iso Resistance value";
CM_ SG_ 884 IPS_RemoteDiagCode "The flag that ECU need to be remote diagnosed";
CM_ SG_ 884 IPS_OBCState10 "OBC state information 10";
CM_ SG_ 884 IPS_OBCState11 "OBC state information 11";
CM_ SG_ 884 IPS_OBCState12 "OBC state information 12";
CM_ SG_ 884 IPS_smd_DcdcModeSt "DCDC basic StateMation";
CM_ SG_ 884 IPS_WakeOriginSignal1 "WakeOriginSignal1";
CM_ SG_ 980 IPS_TEL_DCDCFaultLampInd "Warning indicator to lighten fault lamp (Malfunction Indication Lamp, MIL), FOR TEL";
CM_ SG_ 980 IPS_TEL_DCDCTempOvrErr "over temperature, DCDC not able to work, FOR TEL";
CM_ SG_ 980 IPS_TEL_DCDCModeSt "mode status of DCDC for TEL ";
CM_ SG_ 980 IPS_ExportCode "IPS Export Code";
CM_ SG_ 1011 IPS_OBCDiagErrCode "OBC diagnostics error code";
CM_ SG_ 1011 IPS_DCDCDiagErrCode "DCDC diagnostics error code";
CM_ SG_ 1011 IPS_6_MsgCounter "The MessageCounter is a 0 ~ 15 counter, increased of one unit on every message transmission";
CM_ SG_ 1011 IPS_DCDCState6 "DCDC state information 6";
CM_ SG_ 1011 IPS_DCDCState7 "DCDC state information 7";
CM_ SG_ 1011 IPS_DCDCState8 "DCDC state information 8";
CM_ SG_ 1011 IPS_DCDCHVPwr "DCDC high-voltage power";
CM_ SG_ 1011 IPS_6_Checksum "Message checksum CRC in accordance with J1850";
CM_ SG_ 531 EVCC_OBC_CPDutycycle "CP_Dutycycle";
CM_ SG_ 531 EVCC_S2_Drive "S2_Drive";
CM_ SG_ 531 EVCC_OBC_CpFreqSt "EVCC_OBCCpFreqSt";
CM_ SG_ 531 EVCC_CCOUT_Drive "CCOUT_Drive";
CM_ SG_ 531 EVCC_lostECAN "EVCC_lostECAN";
CM_ SG_ 531 EVCC_EVSERSNToNORMSCHG "Normal stop charging";
CM_ SG_ 745 PTC_DownShiftSt "PTC Heat DownShift State";
CM_ SG_ 745 PTC_UpShiftSt "PTC Heat UpShift State";
CM_ SG_ 745 PTC_HeatPower "Power of IPS PTC";
CM_ SG_ 745 PTC_HeatCurrent "DC Current of IPS PTC";
CM_ SG_ 745 PTC_Fault "PTC fault information";
CM_ SG_ 745 PTC_InterTemp "PTC's media temperture internal signal in PTC";
CM_ SG_ 745 PTC_MOSTemp "PTC MOSFET temperture ";
CM_ SG_ 745 PTC_ModeSt "PTC Mode ";
CM_ SG_ 745 PTC_1_MsgCounter "Message counter signal for frame";
CM_ SG_ 745 PTC_1_Checksum "Message checksum CRC in accordance with J1850";
CM_ SG_ 369 DCU_RotSpdAct "actual rotation speed of drvie motor";
CM_ SG_ 369 DCU_IdcAct "actual current at HV of DCU";
CM_ SG_ 369 DCU_UdcAct "actual voltage at HV of DCU";
CM_ SG_ 369 DCU_TorqAct "actual torque of drive motor";
CM_ SG_ 369 DCU_1_MsgCounter "The MessageCounter is a 0 ~ 15 counter, increased of one unit on every message transmission";
CM_ SG_ 369 DCU_ModeSt "mode status of drive motor";
CM_ SG_ 369 DCU_1_Checksum "Message checksum CRC in accordance with J1850";
CM_ SG_ 377 DCU_bBigDataFlag "DCU request  TEL upload data ";
CM_ SG_ 377 DCU_Err2NoticeFlag "Lever2 Error for DCU Popup flag";
CM_ SG_ 377 DCU_ErrNotice "DCU error notice";
CM_ SG_ 377 DCU_ErrNoticeOperFlag "Operation flag for DCU error notice";
CM_ SG_ 377 DCU_RemoteDiagCode "The flag that ECU need to be remote diagnosed";
CM_ SG_ 377 DCU_TypeSt "DCU type state for configuration";
CM_ SG_ 377 DCU_2_MsgCounter "The MessageCounter is a 0 ~ 15 counter, increased of one unit on every message transmission";
CM_ SG_ 377 DCU_bDiagReq "Diag request for e-machine Inverter Calibration";
CM_ SG_ 377 DCU_bReadyHV "HV voltage operational";
CM_ SG_ 377 DCU_OffsetCalInd "indication of óffset calibration successfull flag";
CM_ SG_ 377 DCU_2_Checksum "Message checksum CRC in accordance with J1850";
CM_ SG_ 385 DCU_TorqMax "maximum positive Torque allowed (motor)";
CM_ SG_ 385 DCU_TorqMin "maximum negative torque allowed (generator)";
CM_ SG_ 385 DCU_HvilSt "DCU send HVIL status by itself";
CM_ SG_ 385 DCU_SelfTorqMax "Actual value of maximum positive Torque without Idc max limit";
CM_ SG_ 385 DCU_SpdLmtActiveSt "Indication that active of speed limit for drive motor";
CM_ SG_ 385 DCU_SelfTorqMin "Actual value maximum negative torque  without Idc mini limit";
CM_ SG_ 385 DCU_DiagErrCode "DCU diagnostics error code";
CM_ SG_ 385 DCU_DstActive "Surge Damping state active";
CM_ SG_ 385 DCU_GateDrvSt "state of gate driver";
CM_ SG_ 385 DCU_3_MsgCounter "The MessageCounter is a 0 ~ 15 counter, increased of one unit on every message transmission";
CM_ SG_ 385 DCU_3_Checksum "Message checksum CRC in accordance with J1850";
CM_ SG_ 882 DCU_InvtTemp "Current temperature of inverter";
CM_ SG_ 882 DCU_VoltageT30 "Current UT30 Voltage at inverter";
CM_ SG_ 882 DCU_SysTempOvrInd "Indicator of overheat warning lamp, which is lighten if temperature of drive motor system is too high.";
CM_ SG_ 882 DCU_RotTemp "Current temperature of rotor";
CM_ SG_ 882 DCU_CooltReq "Requested DCU coolant massflow";
CM_ SG_ 882 DCU_FaultLampInd "Warning indicator to lighten fault lamp (Malfunction Indication Lamp,MIL)";
CM_ SG_ 882 DCU_StatTemp "Current temperature of stator";
CM_ SG_ 882 DCU_TempCoolant "temperature of inverter cooling water";
CM_ SG_ 882 DCU_8_MsgCounter "The MessageCounter is a 0 ~ 15 counter, increased of one unit on every message transmission";
CM_ SG_ 882 DCU_8_Checksum "Message checksum CRC in accordance with J1850";
CM_ SG_ 910 DCU_DataNo "DCU Data Number 1";
CM_ SG_ 910 DCU_TEL_MotorNumOrder "The order number of motors in the vehicle (this value cannot be larger than the total number)";
CM_ SG_ 910 DCU_TEL_ECUTempOvrErr "The  temperature  of ECU is too high";
CM_ SG_ 910 DCU_TEL_MotTempOvrErr "The  temperature  of Motor is too high";
CM_ SG_ 910 DCU_TEL_MotorNumTotal "The total number of motors in the vehicle";
CM_ SG_ 910 DCU_TEL_InvtTemp "Current temperature of inverter";
CM_ SG_ 910 DCU_TEL_RotSpdAct "actual rotation speed of drvie motor";
CM_ SG_ 910 DCU_TEL_TorqAct "actual torque of drive motor";
CM_ SG_ 910 DCU_TEL_StatTemp "Current temperature of stator";
CM_ SG_ 910 DCU_TEL_ModeSt "Mode state for TEL ONLY";
CM_ SG_ 910 DCU_TEL_CurrActAmend "actual current at HV of DCU（by amend）";
CM_ SG_ 910 DCU_TEL_UdcAct "actual voltage at HV of DCU";
CM_ SG_ 910 DCU_TEL_BattCurr "actual current of battery(BMS_BattCurr)";
CM_ SG_ 376 DCU_ADC_MCUBlkst "DCU block state";
CM_ SG_ 376 DCU_ADC_SpdSvModAvl "DCU speed mode available state";
CM_ SG_ 376 DCU_ADC_MCUStandstill "DCU standstill state";
CM_ SG_ 376 DCU_ADC_MCUSpdSVModFit "DCU speed mode fault";
CM_ SG_ 376 DCU_ADC_MCUVehSldSt "DCU detect vehicle slide state";
CM_ SG_ 376 DCU_ADC_ModeSt "mode status of drive motor";
CM_ SG_ 376 DCU_ADC_MCUReqTq "DCU innner request torque";
CM_ SG_ 376 DCU_ADC_RotSpdAct "actual rotation speed of drvie motor";
CM_ SG_ 376 DCU_10_MsgCounter " 0-15 counter, increased of one unit on every message transmission";
CM_ SG_ 376 DCU_10_Checksum "Message checksum CRC in accordance with J1850";
CM_ SG_ 752 DCU_AHFPwrMax "Max Power of AHF";
CM_ SG_ 752 DCU_AHFPwrMin "Min Power of AHF";
CM_ SG_ 752 DCU_AHFTorqueReq "AHF torque of drive motor";
CM_ SG_ 752 DCU_AHFTorqueAct "AHF torque of drive motor";
CM_ SG_ 752 DCU_11_MsgCounter "The MessageCounter is a 0 ~ 15 counter, increased of one unit on every message transmission";
CM_ SG_ 752 DCU_11_Checksum "Message checksum CRC in accordance with J1850";
CM_ SG_ 753 DCU_12_MsgCounter "The MessageCounter is a 0 ~ 15 counter, increased of one unit on every message transmission";
CM_ SG_ 753 DCU_12_Checksum "Message checksum CRC in accordance with J1850";
CM_ SG_ 555 DCU_EOP_SpdSet "requestable oil pump speed";
CM_ SG_ 555 DCU_EOP_1_MsgCounter "The MessageCounter is a 0 ~ 15 counter, increased of one unit on every message transmission";
CM_ SG_ 555 DCU_EOP_1_Checksum "Message checksum CRC in accordance with J1850";
CM_ SG_ 699 NIDU_BigDataNo "NIDU Big Data Number 1";
CM_ SG_ 556 EOP_SpdAct "Actual speed of oil pump";
CM_ SG_ 556 EOP_IdcAct "oil pump DC current";
CM_ SG_ 556 EOP_CANCommunicationFailure "CAN Communication Failure";
CM_ SG_ 556 EOP_SensorFailure "Sensor Failure";
CM_ SG_ 556 EOP_DriverCircuitFailure "Driver Circuit Failure";
CM_ SG_ 556 EOP_OverTemperature "Over Temperature";
CM_ SG_ 556 EOP_OverVoltage "Over Voltage";
CM_ SG_ 556 EOP_LowVoltage "Low Voltage";
CM_ SG_ 556 EOP_OverCurrent "Over Current";
CM_ SG_ 556 EOP_MotorStallingFailure "Motor Stalling Failure";
CM_ SG_ 556 EOP_ErrLevel "to inform DCU that the error level of the EOP";
CM_ SG_ 556 EOP_LimitCurrentFlag "Limit Current Flag";
CM_ SG_ 556 EOP_SelfCheckSt "self check of OPC";
CM_ SG_ 556 EOP_UdcAct "actual voltage of oil pump";
CM_ SG_ 556 EOP_HighTempDePwrFlag "High Temperature Derating Power Flag";
CM_ SG_ 556 EOP_1_MsgCounter "The MessageCounter is a 0 ~ 15 counter, increased of one unit on every message transmission";
CM_ SG_ 556 EOP_1_Checksum "Message checksum CRC in accordance with J1850";
CM_ SG_ 757 ITS_MotorLoopEstimatedFlow "Estimated flow of the motor loop";
CM_ SG_ 757 ITS_MotorLoopEstimatedFlowVD "whether the estimated flow of the motor loop is valid";
CM_ SG_ 757 ITS_AHFSt "AHF Heat DownShift State";
CM_ SG_ 757 ITS_AHFOnReq "Enable AHF";
CM_ SG_ 757 ITS_PTCOnReq "Enables operation of HV-PTC";
CM_ SG_ 757 ITS_PTCSt "HVAC's PTC OFF or downshift status";
CM_ SG_ 757 ITS_1_E_MsgCounter "The MessageCounter is a 0 ~ 15 counter, increased of one unit on every message transmission";
CM_ SG_ 757 ITS_1_E_Checksum "Message checksum CRC in accordance with J1850";
CM_ SG_ 831 ITS_ECPPwrConsump "ECP power consumption";
CM_ SG_ 834 ITS_MotorInletTemp "Motor Loop Temperature";
CM_ SG_ 834 ITS_MotorInletTempErr "Motor Loop Temperature sensor error";
CM_ SG_ 834 ITS_3_E_MsgCounter "The MessageCounter is a 0 ~ 15 counter, increased of one unit on every message transmission";
CM_ SG_ 834 ITS_3_E_Checksum "Message checksum CRC in accordance with J1850";
CM_ SG_ 842 ITS_BattOutletTsnsrErrCode "Battery outlet temperature sensor error code";
CM_ SG_ 842 ITS_ChlrExvErrCode "Chiller EXV error code";
CM_ SG_ 842 ITS_RawExterTempVD "Raw External temperature valid data";
CM_ SG_ 842 ITS_PTCTargetDuty "PTC target Duty";
CM_ SG_ 842 ITS_RawExterTemp "Raw External temperature";
CM_ SG_ 926 TEL_Time_Year "Year number";
CM_ SG_ 926 TEL_Time_Month "Month number";
CM_ SG_ 926 TEL_Time_Hour "Hour number";
CM_ SG_ 926 TEL_Time_Day "Day number";
CM_ SG_ 926 TEL_Time_Min "Minute number";
CM_ SG_ 926 TEL_TimeVD "TEL time valid value";
CM_ SG_ 926 TEL_BookChrgSt "Book charge state";
CM_ SG_ 926 TEL_Time_Sec "Second number";
CM_ SG_ 1790 NIDU_Diag_Response "NIDU diagnostic response";
CM_ SG_ 537 BCS_VDCActiveSt "Indication that VDC system currently performs a brake/engine intervention when ESP adjust the posture of vehicle ";
CM_ SG_ 537 BCS_TCSActiveSt "Indication that TCS system currently performs a brake/engine intervention";
CM_ SG_ 537 BCS_ABSActiveSt "Indication that ABS system currently performs a brake intervention";
CM_ SG_ 537 BCS_FLWheelSpd "Current wheel speed information of front left wheel";
CM_ SG_ 537 BCS_FRWheelSpd "Current wheel speed information of FR wheel";
CM_ SG_ 537 BCS_MasterCylinderPr "Master cylinder pressure";
CM_ SG_ 537 BCS_EngTorqDecActiveSt "Decrease enginetorque  active status (fast and low)";
CM_ SG_ 537 BCS_RegenModuleActive "Reduce repcuperation torque requested by oppotize TCS control active status";
CM_ SG_ 537 EPS_SteeringAngle "steering wheel angle";
CM_ SG_ 806 ACU_ACChgCurCfg "ACCharge current setting to IPS";
CM_ SG_ 885 BCM_KeySt "Ignition key position status";
CM_ SG_ 1507 VCU_NMNodeAddress "VCU node adress";
CM_ SG_ 1507 VCU_NMDataField1 "VCU Network management data ";
CM_ SG_ 1507 VCU_NMWakeupOrigin_ECAN "Origin of the wake up";
CM_ SG_ 1507 VCU_SubNetWakeRq "SubNet wake up request";
CM_ SG_ 1507 VCU_NMKeepingOrigin "Origin of keeping network awake";
CM_ SG_ 1507 VCU_NMDataField2 "VCU Network management data ";
CM_ SG_ 1506 BMS_NodeAddress "BMS node adress";
CM_ SG_ 1506 BMS_NMDataField1 "BMS Network management data";
CM_ SG_ 1506 BMS_NMWakeupOrigin "BMS Network management data";
CM_ SG_ 1506 BMS_SubNetWakeRq "SubNet wake up request";
CM_ SG_ 1506 BMS_NMKeepingOrigin "Origin of keeping network awake";
CM_ SG_ 1506 BMS_NMDataField2 "BMS Network management data";
CM_ SG_ 1510 IPS_NMNodeAddress "IPS node address";
CM_ SG_ 1510 IPS_NMDataField1 "IPS Network management data ";
CM_ SG_ 1510 IPS_NMWakeupOrigin "Origin of the wake up";
CM_ SG_ 1510 IPS_SubNetWakeRq "SubNet wake up request";
CM_ SG_ 1510 IPS_NMKeepingOrigin "Origin of keeping network awake";
CM_ SG_ 1510 IPS_NMDataField2 "IPS Network management data ";
CM_ SG_ 1533 EVCC_NMNodeAddress "EVCC node address";
CM_ SG_ 1533 EVCC_NMDataField1 "EVCC Network management data ";
CM_ SG_ 1533 EVCC_NMWakeupOrigin "Origin of the wake up";
CM_ SG_ 1533 EVCC_SubNetWakeRq "SubNet wake up request";
CM_ SG_ 1533 EVCC_NMKeepingOrigin "Origin of keeping network awake";
CM_ SG_ 1533 EVCC_NMDataField2 "EVCC Network management data ";
CM_ SG_ 1376 EOP_NMNodeAddress "EOP node address";
CM_ SG_ 1376 EOP_NMDataField1 "EOP Network management data ";
CM_ SG_ 1376 EOP_NMWakeupOrigin "Origin of the wake up";
CM_ SG_ 1376 EOP_SubNetWakeRq "SubNet wake up request";
CM_ SG_ 1376 EOP_NMKeepingOrigin "Origin of keeping network awake";
CM_ SG_ 1376 EOP_NMDataField2 "EOP Network management data ";
CM_ SG_ 1406 NIDU_NMNodeAddress "NIDU node address";
CM_ SG_ 1406 NIDU_NMDataField1 "NIDU Network management data ";
CM_ SG_ 1406 NIDU_NMWakeupOrigin "Origin of the wake up";
CM_ SG_ 1406 NIDU_SubNetWakeRq "SubNet wake up request";
CM_ SG_ 1406 NIDU_NMKeepingOrigin "Origin of keeping network awake";
CM_ SG_ 1406 NIDU_NMDataField2 "NIDU Network management data ";
CM_ SG_ 1508 DCU_NMNodeAddress "DCU node address";
CM_ SG_ 1508 DCU_NMDataField1 "DCU Network management data ";
CM_ SG_ 1508 DCU_NMWakeupOrigin "Origin of the wake up";
CM_ SG_ 1508 DCU_SubNetWakeRq "SubNet wake up request";
CM_ SG_ 1508 DCU_NMKeepingOrigin "Origin of keeping network awake";
CM_ SG_ 1508 DCU_NMDataField2 "DCU Network management data ";
CM_ SG_ 1531 ITS_NMNodeAddress "ITS node address";
CM_ SG_ 1531 ITS_NMDataField1 "ITS Network management data ";
CM_ SG_ 1531 ITS_NMWakeupOrigin "Origin of the wake up";
CM_ SG_ 1531 ITS_SubNetWakeRq "SubNet wake up request";
CM_ SG_ 1531 ITS_NMKeepingOrigin "Origin of keeping network awake";
CM_ SG_ 1531 ITS_NMDataField2 "ITS Network management data ";
CM_ SG_ 1509 GCU_NodeAddress "GCU node address";
CM_ SG_ 1509 GCU_NMDataField1 "GCU Network management data";
CM_ SG_ 1509 GCU_NMWakeupOrignin "Origin of the wake up";
CM_ SG_ 1509 GCU_SubNetWakeRq "SubNet wake up request";
CM_ SG_ 1509 GCU_NMKeepingOrigin "Origin of keeping network awake";
CM_ SG_ 1509 GCU_NMDataField2 "GCU Network management data";
CM_ SG_ 1359 GWM_NMNodeAddress "GWM node address";
CM_ SG_ 1359 GWM_NMDataField1 "GWM Network management data";
CM_ SG_ 1359 GWM_NMWakeupOrigin_ECAN "Origin of the wake up";
CM_ SG_ 1359 GWM_SubNetWakeRq "SubNet wake up request";
CM_ SG_ 1359 GWM_NMKeepingOrigin "Origin of keeping network awake";
CM_ SG_ 1359 GWM_NMKeepingOrigin2 "Origin of keeping network awake2";
CM_ SG_ 1359 GWM_NMDataField2 "GWM Network management data ";
CM_ SG_ 1662 NIDU_Diag_Request "Diagnostic physical request";
BA_DEF_ BO_  "GenMsgCycleTime" INT 0 0;
BA_DEF_ BO_  "GenMsgCycleTimeFast" INT 0 0;
BA_DEF_ BO_  "GenMsgSendType" ENUM  "Periodic","Event","IfActive","POE","PA","FixedPeriodic","Event","EnabledPeriodic","NotUsed","NotUsed","EventPeriodic","NotUsed","NotUsed","NoMsgSendType";
BA_DEF_ BO_  "VFrameFormat" ENUM  "StandardCAN","ExtendedCAN","reserved","reserved","reserved","reserved","reserved","reserved","reserved","reserved","reserved","reserved","reserved","reserved","StandardCAN_FD","ExtendedCAN_FD";
BA_DEF_ SG_  "EventCommandSignal" ENUM  "No","Yes";
BA_DEF_ SG_  "GatewayedSignals" ENUM  "No","Yes";
BA_DEF_ SG_  "GenSigInactiveValue" HEX 0 0;
BA_DEF_ SG_  "GenSigInvalidValue" HEX 0 0;
BA_DEF_ SG_  "GenSigSendType" ENUM  "Trigger","Passive","Cyclic","OnWrite","OnWriteWithRepetition","OnChange","OnChangeWithRepetition","IfActive","IfActiveWithRepetition","NoSigSendType";
BA_DEF_ SG_  "GenSigStartValue" HEX 0 0;
BA_DEF_ SG_  "GenSigTimeoutValue" HEX 0 0;
BA_DEF_ SG_  "Remark" STRING ;
BA_DEF_  "Manufacturer" STRING ;
BA_DEF_  "Project" STRING ;
BA_DEF_  "Version" STRING ;
BA_DEF_  "Date" STRING ;
BA_DEF_  "Author" STRING ;
BA_DEF_  "DBName" STRING ;
BA_DEF_  "BusType" STRING ;
BA_DEF_  "Checker" STRING ;
BA_DEF_  "Approver" STRING ;
BA_DEF_DEF_  "GenMsgCycleTime" 0;
BA_DEF_DEF_  "GenMsgCycleTimeFast" 0;
BA_DEF_DEF_  "GenMsgSendType" "";
BA_DEF_DEF_  "VFrameFormat" "";
BA_DEF_DEF_  "EventCommandSignal" "";
BA_DEF_DEF_  "GatewayedSignals" "";
BA_DEF_DEF_  "GenSigInactiveValue" 0;
BA_DEF_DEF_  "GenSigInvalidValue" 0;
BA_DEF_DEF_  "GenSigSendType" "";
BA_DEF_DEF_  "GenSigStartValue" 0;
BA_DEF_DEF_  "GenSigTimeoutValue" 0;
BA_DEF_DEF_  "Remark" "";
BA_DEF_DEF_  "Manufacturer" "";
BA_DEF_DEF_  "Project" "";
BA_DEF_DEF_  "Version" "";
BA_DEF_DEF_  "Date" "";
BA_DEF_DEF_  "Author" "";
BA_DEF_DEF_  "DBName" "";
BA_DEF_DEF_  "BusType" "";
BA_DEF_DEF_  "Checker" "";
BA_DEF_DEF_  "Approver" "";
BA_ "Manufacturer" "GACRND";
BA_ "Project" "A88";
BA_ "Version" "0.1";
BA_ "Date" "2025-4-30 16:29:33";
BA_ "Author" "LeoFeng";
BA_ "BusType" "CAN";
BA_ "Checker" "Miss Fan";
BA_ "Approver" "Mr Hu";
BA_ "DBName" "NIDUECAN";
BA_ "GenMsgCycleTime" BO_ 864 100;
BA_ "GenMsgSendType" BO_ 864 0;
BA_ "VFrameFormat" BO_ 864 0;
BA_ "GenMsgCycleTime" BO_ 438 10;
BA_ "GenMsgSendType" BO_ 438 0;
BA_ "VFrameFormat" BO_ 438 0;
BA_ "GenMsgCycleTime" BO_ 680 100;
BA_ "GenMsgSendType" BO_ 680 0;
BA_ "VFrameFormat" BO_ 680 0;
BA_ "GenMsgCycleTime" BO_ 673 20;
BA_ "GenMsgSendType" BO_ 673 0;
BA_ "VFrameFormat" BO_ 673 0;
BA_ "GenMsgCycleTime" BO_ 419 10;
BA_ "GenMsgSendType" BO_ 419 0;
BA_ "VFrameFormat" BO_ 419 0;
BA_ "GenMsgCycleTime" BO_ 371 20;
BA_ "GenMsgSendType" BO_ 371 0;
BA_ "VFrameFormat" BO_ 371 0;
BA_ "GenMsgCycleTime" BO_ 893 200;
BA_ "GenMsgSendType" BO_ 893 0;
BA_ "VFrameFormat" BO_ 893 0;
BA_ "GenMsgCycleTime" BO_ 779 100;
BA_ "GenMsgSendType" BO_ 779 0;
BA_ "VFrameFormat" BO_ 779 0;
BA_ "GenMsgCycleTime" BO_ 964 500;
BA_ "GenMsgSendType" BO_ 964 0;
BA_ "VFrameFormat" BO_ 964 0;
BA_ "GenMsgCycleTime" BO_ 983 1000;
BA_ "GenMsgSendType" BO_ 983 0;
BA_ "VFrameFormat" BO_ 983 0;
BA_ "GenMsgCycleTime" BO_ 357 10;
BA_ "GenMsgSendType" BO_ 357 0;
BA_ "VFrameFormat" BO_ 357 0;
BA_ "GenMsgCycleTime" BO_ 678 10;
BA_ "GenMsgSendType" BO_ 678 0;
BA_ "VFrameFormat" BO_ 678 0;
BA_ "GenMsgCycleTime" BO_ 887 100;
BA_ "GenMsgSendType" BO_ 887 0;
BA_ "VFrameFormat" BO_ 887 0;
BA_ "GenMsgCycleTime" BO_ 444 100;
BA_ "GenMsgSendType" BO_ 444 0;
BA_ "VFrameFormat" BO_ 444 0;
BA_ "GenMsgCycleTime" BO_ 889 20;
BA_ "GenMsgSendType" BO_ 889 0;
BA_ "VFrameFormat" BO_ 889 0;
BA_ "GenMsgCycleTime" BO_ 897 200;
BA_ "GenMsgSendType" BO_ 897 0;
BA_ "VFrameFormat" BO_ 897 0;
BA_ "GenMsgCycleTime" BO_ 924 20;
BA_ "GenMsgSendType" BO_ 924 0;
BA_ "VFrameFormat" BO_ 924 0;
BA_ "GenMsgCycleTime" BO_ 925 100;
BA_ "GenMsgSendType" BO_ 925 0;
BA_ "VFrameFormat" BO_ 925 0;
BA_ "GenMsgCycleTime" BO_ 917 100;
BA_ "GenMsgSendType" BO_ 917 0;
BA_ "VFrameFormat" BO_ 917 0;
BA_ "GenMsgCycleTime" BO_ 746 100;
BA_ "GenMsgSendType" BO_ 746 0;
BA_ "VFrameFormat" BO_ 746 0;
BA_ "GenMsgCycleTime" BO_ 884 500;
BA_ "GenMsgSendType" BO_ 884 0;
BA_ "VFrameFormat" BO_ 884 0;
BA_ "GenMsgCycleTime" BO_ 980 500;
BA_ "GenMsgSendType" BO_ 980 0;
BA_ "VFrameFormat" BO_ 980 0;
BA_ "GenMsgCycleTime" BO_ 1011 20;
BA_ "GenMsgSendType" BO_ 1011 0;
BA_ "VFrameFormat" BO_ 1011 0;
BA_ "VFrameFormat" BO_ 2683306134 1;
BA_ "GenMsgSendType" BO_ 2683306134 0;
BA_ "GenMsgCycleTime" BO_ 2683306134 1000;
BA_ "VFrameFormat" BO_ 2683306132 1;
BA_ "GenMsgSendType" BO_ 2683306132 0;
BA_ "GenMsgCycleTime" BO_ 2683306132 1000;
BA_ "VFrameFormat" BO_ 2683306133 1;
BA_ "GenMsgSendType" BO_ 2683306133 0;
BA_ "GenMsgCycleTime" BO_ 2683306133 1000;
BA_ "VFrameFormat" BO_ 2683306161 1;
BA_ "GenMsgSendType" BO_ 2683306161 0;
BA_ "GenMsgCycleTime" BO_ 2683306161 200;
BA_ "VFrameFormat" BO_ 2683306135 1;
BA_ "GenMsgSendType" BO_ 2683306135 0;
BA_ "GenMsgCycleTime" BO_ 2683306135 1000;
BA_ "VFrameFormat" BO_ 2683306140 1;
BA_ "GenMsgSendType" BO_ 2683306140 0;
BA_ "GenMsgCycleTime" BO_ 2683306140 1000;
BA_ "VFrameFormat" BO_ 2683306025 1;
BA_ "GenMsgSendType" BO_ 2683306025 0;
BA_ "GenMsgCycleTime" BO_ 2683306025 200;
BA_ "VFrameFormat" BO_ 2683306032 1;
BA_ "GenMsgSendType" BO_ 2683306032 0;
BA_ "GenMsgCycleTime" BO_ 2683306032 500;
BA_ "VFrameFormat" BO_ 2683306033 1;
BA_ "GenMsgSendType" BO_ 2683306033 0;
BA_ "GenMsgCycleTime" BO_ 2683306033 500;
BA_ "VFrameFormat" BO_ 2683306034 1;
BA_ "GenMsgSendType" BO_ 2683306034 0;
BA_ "GenMsgCycleTime" BO_ 2683306034 500;
BA_ "VFrameFormat" BO_ 2683306035 1;
BA_ "GenMsgSendType" BO_ 2683306035 0;
BA_ "GenMsgCycleTime" BO_ 2683306035 500;
BA_ "VFrameFormat" BO_ 2683306036 1;
BA_ "GenMsgSendType" BO_ 2683306036 0;
BA_ "GenMsgCycleTime" BO_ 2683306036 500;
BA_ "GenMsgCycleTime" BO_ 531 20;
BA_ "GenMsgSendType" BO_ 531 0;
BA_ "VFrameFormat" BO_ 531 0;
BA_ "GenMsgCycleTime" BO_ 745 100;
BA_ "GenMsgSendType" BO_ 745 0;
BA_ "VFrameFormat" BO_ 745 0;
BA_ "GenMsgCycleTime" BO_ 369 10;
BA_ "GenMsgSendType" BO_ 369 0;
BA_ "VFrameFormat" BO_ 369 0;
BA_ "GenMsgCycleTime" BO_ 377 100;
BA_ "GenMsgSendType" BO_ 377 0;
BA_ "VFrameFormat" BO_ 377 0;
BA_ "GenMsgCycleTime" BO_ 385 20;
BA_ "GenMsgSendType" BO_ 385 0;
BA_ "VFrameFormat" BO_ 385 0;
BA_ "GenMsgCycleTime" BO_ 882 500;
BA_ "GenMsgSendType" BO_ 882 0;
BA_ "VFrameFormat" BO_ 882 0;
BA_ "GenMsgCycleTime" BO_ 910 200;
BA_ "GenMsgSendType" BO_ 910 0;
BA_ "VFrameFormat" BO_ 910 0;
BA_ "GenMsgCycleTime" BO_ 376 10;
BA_ "GenMsgSendType" BO_ 376 0;
BA_ "VFrameFormat" BO_ 376 0;
BA_ "GenMsgCycleTime" BO_ 752 100;
BA_ "GenMsgSendType" BO_ 752 0;
BA_ "VFrameFormat" BO_ 752 0;
BA_ "GenMsgCycleTime" BO_ 753 100;
BA_ "GenMsgSendType" BO_ 753 0;
BA_ "VFrameFormat" BO_ 753 0;
BA_ "VFrameFormat" BO_ 2683306152 1;
BA_ "GenMsgSendType" BO_ 2683306152 0;
BA_ "GenMsgCycleTime" BO_ 2683306152 10;
BA_ "VFrameFormat" BO_ 2683306153 1;
BA_ "GenMsgSendType" BO_ 2683306153 0;
BA_ "GenMsgCycleTime" BO_ 2683306153 10;
BA_ "VFrameFormat" BO_ 2683306154 1;
BA_ "GenMsgSendType" BO_ 2683306154 0;
BA_ "GenMsgCycleTime" BO_ 2683306154 10;
BA_ "VFrameFormat" BO_ 2683306155 1;
BA_ "GenMsgSendType" BO_ 2683306155 0;
BA_ "GenMsgCycleTime" BO_ 2683306155 10;
BA_ "VFrameFormat" BO_ 2683306156 1;
BA_ "GenMsgSendType" BO_ 2683306156 0;
BA_ "GenMsgCycleTime" BO_ 2683306156 10;
BA_ "VFrameFormat" BO_ 2683306157 1;
BA_ "GenMsgSendType" BO_ 2683306157 0;
BA_ "GenMsgCycleTime" BO_ 2683306157 100;
BA_ "VFrameFormat" BO_ 2683306158 1;
BA_ "GenMsgSendType" BO_ 2683306158 0;
BA_ "GenMsgCycleTime" BO_ 2683306158 100;
BA_ "VFrameFormat" BO_ 2683306145 1;
BA_ "GenMsgSendType" BO_ 2683306145 0;
BA_ "GenMsgCycleTime" BO_ 2683306145 1000;
BA_ "VFrameFormat" BO_ 2683306146 1;
BA_ "GenMsgSendType" BO_ 2683306146 0;
BA_ "GenMsgCycleTime" BO_ 2683306146 20;
BA_ "VFrameFormat" BO_ 2683306147 1;
BA_ "GenMsgSendType" BO_ 2683306147 0;
BA_ "GenMsgCycleTime" BO_ 2683306147 20;
BA_ "VFrameFormat" BO_ 2683306148 1;
BA_ "GenMsgSendType" BO_ 2683306148 0;
BA_ "GenMsgCycleTime" BO_ 2683306148 20;
BA_ "VFrameFormat" BO_ 2683306149 1;
BA_ "GenMsgSendType" BO_ 2683306149 0;
BA_ "GenMsgCycleTime" BO_ 2683306149 20;
BA_ "VFrameFormat" BO_ 2683306150 1;
BA_ "GenMsgSendType" BO_ 2683306150 0;
BA_ "GenMsgCycleTime" BO_ 2683306150 100;
BA_ "VFrameFormat" BO_ 2683306151 1;
BA_ "GenMsgSendType" BO_ 2683306151 0;
BA_ "GenMsgCycleTime" BO_ 2683306151 1000;
BA_ "GenMsgCycleTime" BO_ 555 100;
BA_ "GenMsgSendType" BO_ 555 0;
BA_ "VFrameFormat" BO_ 555 0;
BA_ "GenMsgSendType" BO_ 920 1;
BA_ "VFrameFormat" BO_ 920 0;
BA_ "GenMsgCycleTime" BO_ 699 100;
BA_ "GenMsgSendType" BO_ 699 0;
BA_ "VFrameFormat" BO_ 699 0;
BA_ "VFrameFormat" BO_ 2683306159 1;
BA_ "GenMsgSendType" BO_ 2683306159 1;
BA_ "GenMsgCycleTime" BO_ 2683306159 10;
BA_ "GenMsgCycleTime" BO_ 556 100;
BA_ "GenMsgSendType" BO_ 556 0;
BA_ "VFrameFormat" BO_ 556 0;
BA_ "GenMsgCycleTime" BO_ 757 100;
BA_ "GenMsgSendType" BO_ 757 0;
BA_ "VFrameFormat" BO_ 757 0;
BA_ "GenMsgCycleTime" BO_ 831 200;
BA_ "GenMsgSendType" BO_ 831 0;
BA_ "VFrameFormat" BO_ 831 0;
BA_ "GenMsgCycleTime" BO_ 834 200;
BA_ "GenMsgSendType" BO_ 834 0;
BA_ "VFrameFormat" BO_ 834 0;
BA_ "GenMsgCycleTime" BO_ 842 200;
BA_ "GenMsgSendType" BO_ 842 0;
BA_ "VFrameFormat" BO_ 842 0;
BA_ "GenMsgCycleTime" BO_ 926 500;
BA_ "GenMsgSendType" BO_ 926 0;
BA_ "VFrameFormat" BO_ 926 0;
BA_ "VFrameFormat" BO_ 2683306160 1;
BA_ "GenMsgSendType" BO_ 2683306160 1;
BA_ "GenMsgSendType" BO_ 2015 1;
BA_ "VFrameFormat" BO_ 2015 0;
BA_ "GenMsgSendType" BO_ 1790 1;
BA_ "VFrameFormat" BO_ 1790 0;
BA_ "GenMsgCycleTime" BO_ 537 20;
BA_ "GenMsgSendType" BO_ 537 0;
BA_ "VFrameFormat" BO_ 537 0;
BA_ "GenMsgCycleTime" BO_ 806 1000;
BA_ "GenMsgCycleTimeFast" BO_ 806 40;
BA_ "GenMsgSendType" BO_ 806 3;
BA_ "VFrameFormat" BO_ 806 0;
BA_ "GenMsgCycleTime" BO_ 885 20;
BA_ "GenMsgSendType" BO_ 885 0;
BA_ "VFrameFormat" BO_ 885 0;
BA_ "GenMsgCycleTime" BO_ 1507 200;
BA_ "GenMsgSendType" BO_ 1507 0;
BA_ "VFrameFormat" BO_ 1507 0;
BA_ "GenMsgCycleTime" BO_ 1506 200;
BA_ "GenMsgSendType" BO_ 1506 0;
BA_ "VFrameFormat" BO_ 1506 0;
BA_ "GenMsgCycleTime" BO_ 1510 200;
BA_ "GenMsgSendType" BO_ 1510 0;
BA_ "VFrameFormat" BO_ 1510 0;
BA_ "GenMsgCycleTime" BO_ 1533 200;
BA_ "GenMsgSendType" BO_ 1533 0;
BA_ "VFrameFormat" BO_ 1533 0;
BA_ "GenMsgCycleTime" BO_ 1376 200;
BA_ "GenMsgSendType" BO_ 1376 0;
BA_ "VFrameFormat" BO_ 1376 0;
BA_ "GenMsgCycleTime" BO_ 1406 200;
BA_ "GenMsgSendType" BO_ 1406 0;
BA_ "VFrameFormat" BO_ 1406 0;
BA_ "GenMsgCycleTime" BO_ 1508 200;
BA_ "GenMsgSendType" BO_ 1508 0;
BA_ "VFrameFormat" BO_ 1508 0;
BA_ "GenMsgCycleTime" BO_ 1531 200;
BA_ "GenMsgSendType" BO_ 1531 0;
BA_ "VFrameFormat" BO_ 1531 0;
BA_ "GenMsgCycleTime" BO_ 1509 200;
BA_ "GenMsgSendType" BO_ 1509 0;
BA_ "VFrameFormat" BO_ 1509 0;
BA_ "GenMsgCycleTime" BO_ 1359 200;
BA_ "GenMsgSendType" BO_ 1359 0;
BA_ "VFrameFormat" BO_ 1359 0;
BA_ "GenMsgSendType" BO_ 1662 1;
BA_ "VFrameFormat" BO_ 1662 0;
BA_ "EventCommandSignal" SG_ 864 VCU_AHFShutImme 0;
BA_ "GatewayedSignals" SG_ 864 VCU_AHFShutImme 0;
BA_ "GenSigSendType" SG_ 864 VCU_AHFShutImme 1;
BA_ "EventCommandSignal" SG_ 864 VCU_AHFDelayEn 0;
BA_ "GatewayedSignals" SG_ 864 VCU_AHFDelayEn 0;
BA_ "GenSigSendType" SG_ 864 VCU_AHFDelayEn 1;
BA_ "EventCommandSignal" SG_ 864 VCU_AHFActivationSt 0;
BA_ "GatewayedSignals" SG_ 864 VCU_AHFActivationSt 0;
BA_ "GenSigSendType" SG_ 864 VCU_AHFActivationSt 1;
BA_ "EventCommandSignal" SG_ 864 VCU_PlgConnSt 0;
BA_ "GatewayedSignals" SG_ 864 VCU_PlgConnSt 0;
BA_ "GenSigSendType" SG_ 864 VCU_PlgConnSt 1;
BA_ "EventCommandSignal" SG_ 438 VCU_DCU_SpdSet 0;
BA_ "GatewayedSignals" SG_ 438 VCU_DCU_SpdSet 0;
BA_ "GenSigInvalidValue" SG_ 438 VCU_DCU_SpdSet 65535;
BA_ "GenSigSendType" SG_ 438 VCU_DCU_SpdSet 1;
BA_ "EventCommandSignal" SG_ 438 VCU_CrntGearLvl_E 0;
BA_ "GatewayedSignals" SG_ 438 VCU_CrntGearLvl_E 0;
BA_ "GenSigSendType" SG_ 438 VCU_CrntGearLvl_E 1;
BA_ "EventCommandSignal" SG_ 438 VCU_DCU_SurgeDamperStReq 0;
BA_ "GatewayedSignals" SG_ 438 VCU_DCU_SurgeDamperStReq 0;
BA_ "GenSigSendType" SG_ 438 VCU_DCU_SurgeDamperStReq 1;
BA_ "EventCommandSignal" SG_ 438 VCU_DCU_TorqSet 0;
BA_ "GatewayedSignals" SG_ 438 VCU_DCU_TorqSet 0;
BA_ "GenSigInvalidValue" SG_ 438 VCU_DCU_TorqSet 2047;
BA_ "GenSigSendType" SG_ 438 VCU_DCU_TorqSet 1;
BA_ "GenSigTimeoutValue" SG_ 438 VCU_DCU_TorqSet 2046;
BA_ "EventCommandSignal" SG_ 438 VCU_DCU_SurgeDamperFactor 0;
BA_ "GatewayedSignals" SG_ 438 VCU_DCU_SurgeDamperFactor 0;
BA_ "GenSigInvalidValue" SG_ 438 VCU_DCU_SurgeDamperFactor 63;
BA_ "GenSigSendType" SG_ 438 VCU_DCU_SurgeDamperFactor 1;
BA_ "EventCommandSignal" SG_ 438 VCU_DCU_VehPwrAbnormal 0;
BA_ "GatewayedSignals" SG_ 438 VCU_DCU_VehPwrAbnormal 0;
BA_ "GenSigSendType" SG_ 438 VCU_DCU_VehPwrAbnormal 1;
BA_ "EventCommandSignal" SG_ 438 VCU_4_E_MsgCounter 0;
BA_ "GatewayedSignals" SG_ 438 VCU_4_E_MsgCounter 0;
BA_ "GenSigSendType" SG_ 438 VCU_4_E_MsgCounter 1;
BA_ "EventCommandSignal" SG_ 438 VCU_DCU_ModeReq 0;
BA_ "GatewayedSignals" SG_ 438 VCU_DCU_ModeReq 0;
BA_ "GenSigSendType" SG_ 438 VCU_DCU_ModeReq 1;
BA_ "GenSigStartValue" SG_ 438 VCU_DCU_ModeReq 2;
BA_ "EventCommandSignal" SG_ 438 VCU_4_E_Checksum 0;
BA_ "GatewayedSignals" SG_ 438 VCU_4_E_Checksum 0;
BA_ "GenSigSendType" SG_ 438 VCU_4_E_Checksum 1;
BA_ "GenSigStartValue" SG_ 438 VCU_4_E_Checksum 85;
BA_ "EventCommandSignal" SG_ 680 VCU_IPS_DCDCVoltLvSet 0;
BA_ "GatewayedSignals" SG_ 680 VCU_IPS_DCDCVoltLvSet 0;
BA_ "GenSigSendType" SG_ 680 VCU_IPS_DCDCVoltLvSet 1;
BA_ "GenSigStartValue" SG_ 680 VCU_IPS_DCDCVoltLvSet 58;
BA_ "EventCommandSignal" SG_ 680 VCU_IPS_DCDCModeReq 0;
BA_ "GatewayedSignals" SG_ 680 VCU_IPS_DCDCModeReq 0;
BA_ "GenSigSendType" SG_ 680 VCU_IPS_DCDCModeReq 1;
BA_ "GenSigStartValue" SG_ 680 VCU_IPS_DCDCModeReq 1;
BA_ "EventCommandSignal" SG_ 680 VCU_IPS_DCDCLvCurrLim 0;
BA_ "GatewayedSignals" SG_ 680 VCU_IPS_DCDCLvCurrLim 0;
BA_ "GenSigSendType" SG_ 680 VCU_IPS_DCDCLvCurrLim 1;
BA_ "EventCommandSignal" SG_ 680 VCU_5_E_MsgCounter 0;
BA_ "GatewayedSignals" SG_ 680 VCU_5_E_MsgCounter 0;
BA_ "GenSigSendType" SG_ 680 VCU_5_E_MsgCounter 1;
BA_ "EventCommandSignal" SG_ 680 VCU_5_E_Checksum 0;
BA_ "GatewayedSignals" SG_ 680 VCU_5_E_Checksum 0;
BA_ "GenSigSendType" SG_ 680 VCU_5_E_Checksum 1;
BA_ "GenSigStartValue" SG_ 680 VCU_5_E_Checksum 85;
BA_ "EventCommandSignal" SG_ 673 VCU_HvilSt 0;
BA_ "GatewayedSignals" SG_ 673 VCU_HvilSt 0;
BA_ "GenSigSendType" SG_ 673 VCU_HvilSt 1;
BA_ "EventCommandSignal" SG_ 673 VCU_BMS_SepaHeatEn 0;
BA_ "GatewayedSignals" SG_ 673 VCU_BMS_SepaHeatEn 0;
BA_ "GenSigSendType" SG_ 673 VCU_BMS_SepaHeatEn 1;
BA_ "EventCommandSignal" SG_ 673 VCU_IPS_OBCModeReq 0;
BA_ "GatewayedSignals" SG_ 673 VCU_IPS_OBCModeReq 0;
BA_ "GenSigSendType" SG_ 673 VCU_IPS_OBCModeReq 1;
BA_ "GenSigStartValue" SG_ 673 VCU_IPS_OBCModeReq 1;
BA_ "Remark" SG_ 673 VCU_IPS_OBCModeReq "4=Heating/V2C































其中V2C为混动用，后续混动上加热时移动V2C";
BA_ "EventCommandSignal" SG_ 673 VCU_IPS_OBCDsChDCCurrLim 0;
BA_ "GatewayedSignals" SG_ 673 VCU_IPS_OBCDsChDCCurrLim 0;
BA_ "GenSigSendType" SG_ 673 VCU_IPS_OBCDsChDCCurrLim 1;
BA_ "EventCommandSignal" SG_ 673 VCU_6_E_MsgCounter 0;
BA_ "GatewayedSignals" SG_ 673 VCU_6_E_MsgCounter 0;
BA_ "GenSigSendType" SG_ 673 VCU_6_E_MsgCounter 1;
BA_ "EventCommandSignal" SG_ 673 VCU_6_E_Checksum 0;
BA_ "GatewayedSignals" SG_ 673 VCU_6_E_Checksum 0;
BA_ "GenSigSendType" SG_ 673 VCU_6_E_Checksum 1;
BA_ "GenSigStartValue" SG_ 673 VCU_6_E_Checksum 85;
BA_ "EventCommandSignal" SG_ 419 VCU_DCU_IdcMax 0;
BA_ "GatewayedSignals" SG_ 419 VCU_DCU_IdcMax 0;
BA_ "GenSigSendType" SG_ 419 VCU_DCU_IdcMax 1;
BA_ "GenSigStartValue" SG_ 419 VCU_DCU_IdcMax 1022;
BA_ "EventCommandSignal" SG_ 419 VCU_DCU_IdcMin 0;
BA_ "GatewayedSignals" SG_ 419 VCU_DCU_IdcMin 0;
BA_ "GenSigSendType" SG_ 419 VCU_DCU_IdcMin 1;
BA_ "GenSigStartValue" SG_ 419 VCU_DCU_IdcMin 1;
BA_ "EventCommandSignal" SG_ 419 VCU_DCU_UdcMin 0;
BA_ "GatewayedSignals" SG_ 419 VCU_DCU_UdcMin 0;
BA_ "GenSigInvalidValue" SG_ 419 VCU_DCU_UdcMin 1023;
BA_ "GenSigSendType" SG_ 419 VCU_DCU_UdcMin 1;
BA_ "EventCommandSignal" SG_ 419 VCU_DCU_UdcMax 0;
BA_ "GatewayedSignals" SG_ 419 VCU_DCU_UdcMax 0;
BA_ "GenSigInvalidValue" SG_ 419 VCU_DCU_UdcMax 1023;
BA_ "GenSigSendType" SG_ 419 VCU_DCU_UdcMax 1;
BA_ "EventCommandSignal" SG_ 419 VCU_12_E_MsgCounter 0;
BA_ "GatewayedSignals" SG_ 419 VCU_12_E_MsgCounter 0;
BA_ "GenSigSendType" SG_ 419 VCU_12_E_MsgCounter 1;
BA_ "EventCommandSignal" SG_ 419 VCU_12_E_Checksum 0;
BA_ "GatewayedSignals" SG_ 419 VCU_12_E_Checksum 0;
BA_ "GenSigSendType" SG_ 419 VCU_12_E_Checksum 1;
BA_ "GenSigStartValue" SG_ 419 VCU_12_E_Checksum 85;
BA_ "EventCommandSignal" SG_ 371 VCU_DCU_TorqMin 0;
BA_ "GatewayedSignals" SG_ 371 VCU_DCU_TorqMin 0;
BA_ "GenSigSendType" SG_ 371 VCU_DCU_TorqMin 1;
BA_ "GenSigStartValue" SG_ 371 VCU_DCU_TorqMin 1;
BA_ "EventCommandSignal" SG_ 371 VCU_DCU_MaxTorqGradient 0;
BA_ "GatewayedSignals" SG_ 371 VCU_DCU_MaxTorqGradient 0;
BA_ "GenSigInvalidValue" SG_ 371 VCU_DCU_MaxTorqGradient 16383;
BA_ "GenSigSendType" SG_ 371 VCU_DCU_MaxTorqGradient 1;
BA_ "EventCommandSignal" SG_ 371 VCU_DCU_TorqMax 0;
BA_ "GatewayedSignals" SG_ 371 VCU_DCU_TorqMax 0;
BA_ "GenSigSendType" SG_ 371 VCU_DCU_TorqMax 1;
BA_ "GenSigStartValue" SG_ 371 VCU_DCU_TorqMax 1022;
BA_ "EventCommandSignal" SG_ 371 VCU_DCU_MaxTorqDampgCtl 0;
BA_ "GatewayedSignals" SG_ 371 VCU_DCU_MaxTorqDampgCtl 0;
BA_ "GenSigInvalidValue" SG_ 371 VCU_DCU_MaxTorqDampgCtl 255;
BA_ "GenSigSendType" SG_ 371 VCU_DCU_MaxTorqDampgCtl 1;
BA_ "EventCommandSignal" SG_ 371 VCU_13_E_MsgCounter 0;
BA_ "GatewayedSignals" SG_ 371 VCU_13_E_MsgCounter 0;
BA_ "GenSigSendType" SG_ 371 VCU_13_E_MsgCounter 1;
BA_ "EventCommandSignal" SG_ 371 VCU_13_E_Checksum 0;
BA_ "GatewayedSignals" SG_ 371 VCU_13_E_Checksum 0;
BA_ "GenSigSendType" SG_ 371 VCU_13_E_Checksum 1;
BA_ "GenSigStartValue" SG_ 371 VCU_13_E_Checksum 85;
BA_ "EventCommandSignal" SG_ 893 VCU_IPS_OBCChgVoltReq 0;
BA_ "GatewayedSignals" SG_ 893 VCU_IPS_OBCChgVoltReq 0;
BA_ "GenSigSendType" SG_ 893 VCU_IPS_OBCChgVoltReq 1;
BA_ "EventCommandSignal" SG_ 893 VCU_IPS_OBCChgCurrReq 0;
BA_ "GatewayedSignals" SG_ 893 VCU_IPS_OBCChgCurrReq 0;
BA_ "GenSigSendType" SG_ 893 VCU_IPS_OBCChgCurrReq 1;
BA_ "EventCommandSignal" SG_ 893 VCU_16_E_MsgCounter 0;
BA_ "GatewayedSignals" SG_ 893 VCU_16_E_MsgCounter 0;
BA_ "GenSigSendType" SG_ 893 VCU_16_E_MsgCounter 1;
BA_ "EventCommandSignal" SG_ 893 VCU_16_E_Checksum 0;
BA_ "GatewayedSignals" SG_ 893 VCU_16_E_Checksum 0;
BA_ "GenSigSendType" SG_ 893 VCU_16_E_Checksum 1;
BA_ "GenSigStartValue" SG_ 893 VCU_16_E_Checksum 85;
BA_ "EventCommandSignal" SG_ 779 VCU_AHFActivatePwr 0;
BA_ "GatewayedSignals" SG_ 779 VCU_AHFActivatePwr 0;
BA_ "GenSigSendType" SG_ 779 VCU_AHFActivatePwr 1;
BA_ "EventCommandSignal" SG_ 779 VCU_DCU_IdcMeasure 0;
BA_ "GatewayedSignals" SG_ 779 VCU_DCU_IdcMeasure 0;
BA_ "GenSigSendType" SG_ 779 VCU_DCU_IdcMeasure 1;
BA_ "EventCommandSignal" SG_ 779 VCU_SwapHvBattModeSt 0;
BA_ "GatewayedSignals" SG_ 779 VCU_SwapHvBattModeSt 0;
BA_ "GenSigSendType" SG_ 779 VCU_SwapHvBattModeSt 1;
BA_ "EventCommandSignal" SG_ 779 VCU_SwapHvBattModeStVD 0;
BA_ "GatewayedSignals" SG_ 779 VCU_SwapHvBattModeStVD 0;
BA_ "GenSigSendType" SG_ 779 VCU_SwapHvBattModeStVD 1;
BA_ "EventCommandSignal" SG_ 964 VCU_22_E_MsgCounter 0;
BA_ "GatewayedSignals" SG_ 964 VCU_22_E_MsgCounter 0;
BA_ "GenSigSendType" SG_ 964 VCU_22_E_MsgCounter 1;
BA_ "EventCommandSignal" SG_ 964 VCU_22_E_Checksum 0;
BA_ "GatewayedSignals" SG_ 964 VCU_22_E_Checksum 0;
BA_ "GenSigSendType" SG_ 964 VCU_22_E_Checksum 1;
BA_ "GenSigStartValue" SG_ 964 VCU_22_E_Checksum 85;
BA_ "EventCommandSignal" SG_ 983 VCU_TEL_AccPedalActPst 0;
BA_ "GatewayedSignals" SG_ 983 VCU_TEL_AccPedalActPst 0;
BA_ "GenSigSendType" SG_ 983 VCU_TEL_AccPedalActPst 1;
BA_ "EventCommandSignal" SG_ 357 VCU_DCU_SpdLmt 0;
BA_ "GatewayedSignals" SG_ 357 VCU_DCU_SpdLmt 0;
BA_ "GenSigSendType" SG_ 357 VCU_DCU_SpdLmt 1;
BA_ "EventCommandSignal" SG_ 357 VCU_BrkPedPst_E 0;
BA_ "GatewayedSignals" SG_ 357 VCU_BrkPedPst_E 0;
BA_ "GenSigSendType" SG_ 357 VCU_BrkPedPst_E 1;
BA_ "EventCommandSignal" SG_ 357 VCU_EMS_AccPedalActPst_E 0;
BA_ "GatewayedSignals" SG_ 357 VCU_EMS_AccPedalActPst_E 0;
BA_ "GenSigSendType" SG_ 357 VCU_EMS_AccPedalActPst_E 1;
BA_ "EventCommandSignal" SG_ 678 BMS_BattCurr 0;
BA_ "GatewayedSignals" SG_ 678 BMS_BattCurr 0;
BA_ "GenSigInvalidValue" SG_ 678 BMS_BattCurr 65535;
BA_ "GenSigSendType" SG_ 678 BMS_BattCurr 1;
BA_ "GenSigStartValue" SG_ 678 BMS_BattCurr 10000;
BA_ "EventCommandSignal" SG_ 678 BMS_BattVolt 0;
BA_ "GatewayedSignals" SG_ 678 BMS_BattVolt 0;
BA_ "GenSigInvalidValue" SG_ 678 BMS_BattVolt 1023;
BA_ "GenSigSendType" SG_ 678 BMS_BattVolt 1;
BA_ "EventCommandSignal" SG_ 678 BMS_DcChargerSt 0;
BA_ "GatewayedSignals" SG_ 678 BMS_DcChargerSt 0;
BA_ "GenSigSendType" SG_ 678 BMS_DcChargerSt 1;
BA_ "EventCommandSignal" SG_ 678 BMS_DCUBattSt 0;
BA_ "GatewayedSignals" SG_ 678 BMS_DCUBattSt 0;
BA_ "GenSigSendType" SG_ 678 BMS_DCUBattSt 1;
BA_ "EventCommandSignal" SG_ 678 BMS_PwrDwnReq 0;
BA_ "GatewayedSignals" SG_ 678 BMS_PwrDwnReq 0;
BA_ "GenSigSendType" SG_ 678 BMS_PwrDwnReq 1;
BA_ "EventCommandSignal" SG_ 678 BMS_1_MsgCounter 0;
BA_ "GatewayedSignals" SG_ 678 BMS_1_MsgCounter 0;
BA_ "GenSigSendType" SG_ 678 BMS_1_MsgCounter 1;
BA_ "EventCommandSignal" SG_ 678 BMS_1_Checksum 0;
BA_ "GatewayedSignals" SG_ 678 BMS_1_Checksum 0;
BA_ "GenSigSendType" SG_ 678 BMS_1_Checksum 1;
BA_ "GenSigStartValue" SG_ 678 BMS_1_Checksum 85;
BA_ "EventCommandSignal" SG_ 887 BMS_DCVoltRx 0;
BA_ "GatewayedSignals" SG_ 887 BMS_DCVoltRx 0;
BA_ "GenSigSendType" SG_ 887 BMS_DCVoltRx 1;
BA_ "EventCommandSignal" SG_ 887 BMS_DCCurrRx 0;
BA_ "GatewayedSignals" SG_ 887 BMS_DCCurrRx 0;
BA_ "GenSigSendType" SG_ 887 BMS_DCCurrRx 1;
BA_ "GenSigStartValue" SG_ 887 BMS_DCCurrRx 10000;
BA_ "EventCommandSignal" SG_ 444 BMS_SepaHeatSt 0;
BA_ "GatewayedSignals" SG_ 444 BMS_SepaHeatSt 0;
BA_ "GenSigSendType" SG_ 444 BMS_SepaHeatSt 1;
BA_ "EventCommandSignal" SG_ 444 BMS_16_MsgCounter 0;
BA_ "GatewayedSignals" SG_ 444 BMS_16_MsgCounter 0;
BA_ "GenSigSendType" SG_ 444 BMS_16_MsgCounter 1;
BA_ "EventCommandSignal" SG_ 444 BMS_16_Checksum 0;
BA_ "GatewayedSignals" SG_ 444 BMS_16_Checksum 0;
BA_ "GenSigSendType" SG_ 444 BMS_16_Checksum 1;
BA_ "GenSigStartValue" SG_ 444 BMS_16_Checksum 85;
BA_ "EventCommandSignal" SG_ 889 IPS_DCDCModeSt 0;
BA_ "GatewayedSignals" SG_ 889 IPS_DCDCModeSt 0;
BA_ "GenSigSendType" SG_ 889 IPS_DCDCModeSt 1;
BA_ "EventCommandSignal" SG_ 889 IPS_HVDCHVilSt 0;
BA_ "GatewayedSignals" SG_ 889 IPS_HVDCHVilSt 0;
BA_ "GenSigSendType" SG_ 889 IPS_HVDCHVilSt 1;
BA_ "EventCommandSignal" SG_ 889 IPS_DCDCVoltLvAct 0;
BA_ "GatewayedSignals" SG_ 889 IPS_DCDCVoltLvAct 0;
BA_ "GenSigSendType" SG_ 889 IPS_DCDCVoltLvAct 1;
BA_ "EventCommandSignal" SG_ 889 IPS_DCDCCurrHvAct 0;
BA_ "GatewayedSignals" SG_ 889 IPS_DCDCCurrHvAct 0;
BA_ "GenSigSendType" SG_ 889 IPS_DCDCCurrHvAct 1;
BA_ "EventCommandSignal" SG_ 889 IPS_DCDCCurrLvAct 0;
BA_ "GatewayedSignals" SG_ 889 IPS_DCDCCurrLvAct 0;
BA_ "GenSigSendType" SG_ 889 IPS_DCDCCurrLvAct 1;
BA_ "EventCommandSignal" SG_ 889 IPS_DCDCTempAct 0;
BA_ "GatewayedSignals" SG_ 889 IPS_DCDCTempAct 0;
BA_ "GenSigSendType" SG_ 889 IPS_DCDCTempAct 1;
BA_ "EventCommandSignal" SG_ 889 IPS_DCDC_2_MsgCounter 0;
BA_ "GatewayedSignals" SG_ 889 IPS_DCDC_2_MsgCounter 0;
BA_ "GenSigSendType" SG_ 889 IPS_DCDC_2_MsgCounter 1;
BA_ "EventCommandSignal" SG_ 889 IPS_KL15State 0;
BA_ "GatewayedSignals" SG_ 889 IPS_KL15State 0;
BA_ "GenSigSendType" SG_ 889 IPS_KL15State 1;
BA_ "EventCommandSignal" SG_ 889 IPS_DCDCVoltHvAct 0;
BA_ "GatewayedSignals" SG_ 889 IPS_DCDCVoltHvAct 0;
BA_ "GenSigSendType" SG_ 889 IPS_DCDCVoltHvAct 1;
BA_ "EventCommandSignal" SG_ 889 IPS_DCDC_2_Checksum 0;
BA_ "GatewayedSignals" SG_ 889 IPS_DCDC_2_Checksum 0;
BA_ "GenSigSendType" SG_ 889 IPS_DCDC_2_Checksum 1;
BA_ "GenSigStartValue" SG_ 889 IPS_DCDC_2_Checksum 85;
BA_ "EventCommandSignal" SG_ 897 IPS_DCDCKL30Volt 0;
BA_ "GatewayedSignals" SG_ 897 IPS_DCDCKL30Volt 0;
BA_ "GenSigSendType" SG_ 897 IPS_DCDCKL30Volt 1;
BA_ "EventCommandSignal" SG_ 897 IPS_DcdcHwSt 0;
BA_ "GatewayedSignals" SG_ 897 IPS_DcdcHwSt 0;
BA_ "GenSigSendType" SG_ 897 IPS_DcdcHwSt 1;
BA_ "EventCommandSignal" SG_ 897 IPS_DCDCFaultLampInd 0;
BA_ "GatewayedSignals" SG_ 897 IPS_DCDCFaultLampInd 0;
BA_ "GenSigSendType" SG_ 897 IPS_DCDCFaultLampInd 1;
BA_ "EventCommandSignal" SG_ 897 DCDC_RemoteDiagCode 0;
BA_ "GatewayedSignals" SG_ 897 DCDC_RemoteDiagCode 0;
BA_ "GenSigSendType" SG_ 897 DCDC_RemoteDiagCode 1;
BA_ "EventCommandSignal" SG_ 897 IPS_DCDCFaultLampIndOperFlag 0;
BA_ "GatewayedSignals" SG_ 897 IPS_DCDCFaultLampIndOperFlag 0;
BA_ "GenSigSendType" SG_ 897 IPS_DCDCFaultLampIndOperFlag 1;
BA_ "EventCommandSignal" SG_ 897 IPS_DCDCFaultLampIndFlag 0;
BA_ "GatewayedSignals" SG_ 897 IPS_DCDCFaultLampIndFlag 0;
BA_ "GenSigSendType" SG_ 897 IPS_DCDCFaultLampIndFlag 1;
BA_ "EventCommandSignal" SG_ 897 IPS_DCDCState1 0;
BA_ "GatewayedSignals" SG_ 897 IPS_DCDCState1 0;
BA_ "GenSigSendType" SG_ 897 IPS_DCDCState1 1;
BA_ "EventCommandSignal" SG_ 897 IPS_DCDCState2 0;
BA_ "GatewayedSignals" SG_ 897 IPS_DCDCState2 0;
BA_ "GenSigSendType" SG_ 897 IPS_DCDCState2 1;
BA_ "EventCommandSignal" SG_ 897 IPS_DCDCState3 0;
BA_ "GatewayedSignals" SG_ 897 IPS_DCDCState3 0;
BA_ "GenSigSendType" SG_ 897 IPS_DCDCState3 1;
BA_ "EventCommandSignal" SG_ 897 IPS_DCDCState4 0;
BA_ "GatewayedSignals" SG_ 897 IPS_DCDCState4 0;
BA_ "GenSigSendType" SG_ 897 IPS_DCDCState4 1;
BA_ "EventCommandSignal" SG_ 897 IPS_DCDCState5 0;
BA_ "GatewayedSignals" SG_ 897 IPS_DCDCState5 0;
BA_ "GenSigSendType" SG_ 897 IPS_DCDCState5 1;
BA_ "EventCommandSignal" SG_ 897 IPS_DCDCFlowReq 0;
BA_ "GatewayedSignals" SG_ 897 IPS_DCDCFlowReq 0;
BA_ "GenSigSendType" SG_ 897 IPS_DCDCFlowReq 1;
BA_ "EventCommandSignal" SG_ 924 IPS_DchgOverload 0;
BA_ "GatewayedSignals" SG_ 924 IPS_DchgOverload 0;
BA_ "GenSigSendType" SG_ 924 IPS_DchgOverload 1;
BA_ "EventCommandSignal" SG_ 924 IPS_OBCCC_St 0;
BA_ "GatewayedSignals" SG_ 924 IPS_OBCCC_St 0;
BA_ "GenSigSendType" SG_ 924 IPS_OBCCC_St 1;
BA_ "EventCommandSignal" SG_ 924 IPS_smo_ObcModeSt 0;
BA_ "GatewayedSignals" SG_ 924 IPS_smo_ObcModeSt 0;
BA_ "GenSigSendType" SG_ 924 IPS_smo_ObcModeSt 1;
BA_ "EventCommandSignal" SG_ 924 IPS_OBCDschDisable 0;
BA_ "GatewayedSignals" SG_ 924 IPS_OBCDschDisable 0;
BA_ "GenSigSendType" SG_ 924 IPS_OBCDschDisable 1;
BA_ "EventCommandSignal" SG_ 924 IPS_OBCModeSt 0;
BA_ "GatewayedSignals" SG_ 924 IPS_OBCModeSt 0;
BA_ "GenSigSendType" SG_ 924 IPS_OBCModeSt 1;
BA_ "Remark" SG_ 924 IPS_OBCModeSt "6=Heating/Discharge Overload































其中Discharge Overload为混动用，后续混动上加热时删除Discharge Overload";
BA_ "EventCommandSignal" SG_ 924 IPS_ACHvilSt 0;
BA_ "GatewayedSignals" SG_ 924 IPS_ACHvilSt 0;
BA_ "GenSigSendType" SG_ 924 IPS_ACHvilSt 1;
BA_ "EventCommandSignal" SG_ 924 IPS_OBCCC_Cap 0;
BA_ "GatewayedSignals" SG_ 924 IPS_OBCCC_Cap 0;
BA_ "GenSigSendType" SG_ 924 IPS_OBCCC_Cap 1;
BA_ "EventCommandSignal" SG_ 924 IPS_OBCCpS2St 0;
BA_ "GatewayedSignals" SG_ 924 IPS_OBCCpS2St 0;
BA_ "GenSigSendType" SG_ 924 IPS_OBCCpS2St 1;
BA_ "EventCommandSignal" SG_ 924 IPS_OBCCpFreqSt 0;
BA_ "GatewayedSignals" SG_ 924 IPS_OBCCpFreqSt 0;
BA_ "GenSigSendType" SG_ 924 IPS_OBCCpFreqSt 1;
BA_ "EventCommandSignal" SG_ 924 IPS_OBCCPSt 0;
BA_ "GatewayedSignals" SG_ 924 IPS_OBCCPSt 0;
BA_ "GenSigSendType" SG_ 924 IPS_OBCCPSt 1;
BA_ "EventCommandSignal" SG_ 924 IPS_OBCCp_DutyCycle 0;
BA_ "GatewayedSignals" SG_ 924 IPS_OBCCp_DutyCycle 0;
BA_ "GenSigSendType" SG_ 924 IPS_OBCCp_DutyCycle 1;
BA_ "EventCommandSignal" SG_ 924 IPS_OBCCPVolt 0;
BA_ "GatewayedSignals" SG_ 924 IPS_OBCCPVolt 0;
BA_ "GenSigSendType" SG_ 924 IPS_OBCCPVolt 1;
BA_ "EventCommandSignal" SG_ 924 IPS_OBC_1_MsgCounter 0;
BA_ "GatewayedSignals" SG_ 924 IPS_OBC_1_MsgCounter 0;
BA_ "GenSigSendType" SG_ 924 IPS_OBC_1_MsgCounter 1;
BA_ "EventCommandSignal" SG_ 924 IPS_OBCStStep 0;
BA_ "GatewayedSignals" SG_ 924 IPS_OBCStStep 0;
BA_ "GenSigSendType" SG_ 924 IPS_OBCStStep 1;
BA_ "EventCommandSignal" SG_ 924 IPS_OBC_1_Checksum 0;
BA_ "GatewayedSignals" SG_ 924 IPS_OBC_1_Checksum 0;
BA_ "GenSigSendType" SG_ 924 IPS_OBC_1_Checksum 1;
BA_ "GenSigStartValue" SG_ 924 IPS_OBC_1_Checksum 85;
BA_ "EventCommandSignal" SG_ 925 IPS_OBCState6 0;
BA_ "GatewayedSignals" SG_ 925 IPS_OBCState6 0;
BA_ "GenSigSendType" SG_ 925 IPS_OBCState6 1;
BA_ "EventCommandSignal" SG_ 925 IPS_OBCState7 0;
BA_ "GatewayedSignals" SG_ 925 IPS_OBCState7 0;
BA_ "GenSigSendType" SG_ 925 IPS_OBCState7 1;
BA_ "EventCommandSignal" SG_ 925 IPS_OBCState1 0;
BA_ "GatewayedSignals" SG_ 925 IPS_OBCState1 0;
BA_ "GenSigSendType" SG_ 925 IPS_OBCState1 1;
BA_ "EventCommandSignal" SG_ 925 IPS_OBCState2 0;
BA_ "GatewayedSignals" SG_ 925 IPS_OBCState2 0;
BA_ "GenSigSendType" SG_ 925 IPS_OBCState2 1;
BA_ "EventCommandSignal" SG_ 925 IPS_OBCState3 0;
BA_ "GatewayedSignals" SG_ 925 IPS_OBCState3 0;
BA_ "GenSigSendType" SG_ 925 IPS_OBCState3 1;
BA_ "EventCommandSignal" SG_ 925 IPS_OBCState4 0;
BA_ "GatewayedSignals" SG_ 925 IPS_OBCState4 0;
BA_ "GenSigSendType" SG_ 925 IPS_OBCState4 1;
BA_ "EventCommandSignal" SG_ 925 IPS_OBCState5 0;
BA_ "GatewayedSignals" SG_ 925 IPS_OBCState5 0;
BA_ "GenSigSendType" SG_ 925 IPS_OBCState5 1;
BA_ "EventCommandSignal" SG_ 925 IPS_OBCState8 0;
BA_ "GatewayedSignals" SG_ 925 IPS_OBCState8 0;
BA_ "GenSigSendType" SG_ 925 IPS_OBCState8 1;
BA_ "EventCommandSignal" SG_ 917 IPS_OBCUacActL1 0;
BA_ "GatewayedSignals" SG_ 917 IPS_OBCUacActL1 0;
BA_ "GenSigSendType" SG_ 917 IPS_OBCUacActL1 1;
BA_ "EventCommandSignal" SG_ 917 IPS_OBCUacActL2 0;
BA_ "GatewayedSignals" SG_ 917 IPS_OBCUacActL2 0;
BA_ "GenSigSendType" SG_ 917 IPS_OBCUacActL2 1;
BA_ "EventCommandSignal" SG_ 917 IPS_OBCUacActL3 0;
BA_ "GatewayedSignals" SG_ 917 IPS_OBCUacActL3 0;
BA_ "GenSigSendType" SG_ 917 IPS_OBCUacActL3 1;
BA_ "EventCommandSignal" SG_ 917 IPS_OBCCurrActL1 0;
BA_ "GatewayedSignals" SG_ 917 IPS_OBCCurrActL1 0;
BA_ "GenSigSendType" SG_ 917 IPS_OBCCurrActL1 1;
BA_ "EventCommandSignal" SG_ 917 IPS_OBCCurrActL2 0;
BA_ "GatewayedSignals" SG_ 917 IPS_OBCCurrActL2 0;
BA_ "GenSigSendType" SG_ 917 IPS_OBCCurrActL2 1;
BA_ "EventCommandSignal" SG_ 917 IPS_OBCCurrActL3 0;
BA_ "GatewayedSignals" SG_ 917 IPS_OBCCurrActL3 0;
BA_ "GenSigSendType" SG_ 917 IPS_OBCCurrActL3 1;
BA_ "EventCommandSignal" SG_ 917 IPS_OBCCC_Res 0;
BA_ "GatewayedSignals" SG_ 917 IPS_OBCCC_Res 0;
BA_ "GenSigSendType" SG_ 917 IPS_OBCCC_Res 1;
BA_ "EventCommandSignal" SG_ 746 IPS_OBCState9 0;
BA_ "GatewayedSignals" SG_ 746 IPS_OBCState9 0;
BA_ "GenSigSendType" SG_ 746 IPS_OBCState9 1;
BA_ "EventCommandSignal" SG_ 746 IPS_OBCChgPwrMax 0;
BA_ "GatewayedSignals" SG_ 746 IPS_OBCChgPwrMax 0;
BA_ "GenSigSendType" SG_ 746 IPS_OBCChgPwrMax 1;
BA_ "EventCommandSignal" SG_ 746 IPS_OBCHvDcCurrAct 0;
BA_ "GatewayedSignals" SG_ 746 IPS_OBCHvDcCurrAct 0;
BA_ "GenSigSendType" SG_ 746 IPS_OBCHvDcCurrAct 1;
BA_ "GenSigStartValue" SG_ 746 IPS_OBCHvDcCurrAct 1024;
BA_ "EventCommandSignal" SG_ 746 IPS_ChgCurRespAvail 0;
BA_ "GatewayedSignals" SG_ 746 IPS_ChgCurRespAvail 0;
BA_ "GenSigSendType" SG_ 746 IPS_ChgCurRespAvail 1;
BA_ "EventCommandSignal" SG_ 746 IPS_ChgCurResp 0;
BA_ "GatewayedSignals" SG_ 746 IPS_ChgCurResp 0;
BA_ "GenSigSendType" SG_ 746 IPS_ChgCurResp 1;
BA_ "EventCommandSignal" SG_ 746 IPS_OBCHvDcVoltAct 0;
BA_ "GatewayedSignals" SG_ 746 IPS_OBCHvDcVoltAct 0;
BA_ "GenSigSendType" SG_ 746 IPS_OBCHvDcVoltAct 1;
BA_ "EventCommandSignal" SG_ 746 IPS_HwSt 0;
BA_ "GatewayedSignals" SG_ 746 IPS_HwSt 0;
BA_ "GenSigSendType" SG_ 746 IPS_HwSt 1;
BA_ "EventCommandSignal" SG_ 884 IPS_OBCEngMilLampReq 0;
BA_ "GatewayedSignals" SG_ 884 IPS_OBCEngMilLampReq 0;
BA_ "GenSigSendType" SG_ 884 IPS_OBCEngMilLampReq 1;
BA_ "EventCommandSignal" SG_ 884 IPS_OBCFlowReq 0;
BA_ "GatewayedSignals" SG_ 884 IPS_OBCFlowReq 0;
BA_ "GenSigSendType" SG_ 884 IPS_OBCFlowReq 1;
BA_ "EventCommandSignal" SG_ 884 IPS_OBCFaultLampInd 0;
BA_ "GatewayedSignals" SG_ 884 IPS_OBCFaultLampInd 0;
BA_ "GenSigSendType" SG_ 884 IPS_OBCFaultLampInd 1;
BA_ "EventCommandSignal" SG_ 884 IPS_OBCFaultLampIndOperFlag 0;
BA_ "GatewayedSignals" SG_ 884 IPS_OBCFaultLampIndOperFlag 0;
BA_ "GenSigSendType" SG_ 884 IPS_OBCFaultLampIndOperFlag 1;
BA_ "EventCommandSignal" SG_ 884 IPS_OBCEnergyDirCap 0;
BA_ "GatewayedSignals" SG_ 884 IPS_OBCEnergyDirCap 0;
BA_ "GenSigSendType" SG_ 884 IPS_OBCEnergyDirCap 1;
BA_ "EventCommandSignal" SG_ 884 IPS_OBCTempAct 0;
BA_ "GatewayedSignals" SG_ 884 IPS_OBCTempAct 0;
BA_ "GenSigSendType" SG_ 884 IPS_OBCTempAct 1;
BA_ "EventCommandSignal" SG_ 884 IPS_OBCAcIso_Res 0;
BA_ "GatewayedSignals" SG_ 884 IPS_OBCAcIso_Res 0;
BA_ "GenSigSendType" SG_ 884 IPS_OBCAcIso_Res 1;
BA_ "GenSigStartValue" SG_ 884 IPS_OBCAcIso_Res 63;
BA_ "EventCommandSignal" SG_ 884 IPS_RemoteDiagCode 0;
BA_ "GatewayedSignals" SG_ 884 IPS_RemoteDiagCode 0;
BA_ "GenSigSendType" SG_ 884 IPS_RemoteDiagCode 1;
BA_ "EventCommandSignal" SG_ 884 IPS_OBCState10 0;
BA_ "GatewayedSignals" SG_ 884 IPS_OBCState10 0;
BA_ "GenSigSendType" SG_ 884 IPS_OBCState10 1;
BA_ "EventCommandSignal" SG_ 884 IPS_OBCState11 0;
BA_ "GatewayedSignals" SG_ 884 IPS_OBCState11 0;
BA_ "GenSigSendType" SG_ 884 IPS_OBCState11 1;
BA_ "EventCommandSignal" SG_ 884 IPS_OBCState12 0;
BA_ "GatewayedSignals" SG_ 884 IPS_OBCState12 0;
BA_ "GenSigSendType" SG_ 884 IPS_OBCState12 1;
BA_ "EventCommandSignal" SG_ 884 IPS_smd_DcdcModeSt 0;
BA_ "GatewayedSignals" SG_ 884 IPS_smd_DcdcModeSt 0;
BA_ "GenSigSendType" SG_ 884 IPS_smd_DcdcModeSt 1;
BA_ "EventCommandSignal" SG_ 884 IPS_WakeOriginSignal1 0;
BA_ "GatewayedSignals" SG_ 884 IPS_WakeOriginSignal1 0;
BA_ "GenSigSendType" SG_ 884 IPS_WakeOriginSignal1 1;
BA_ "EventCommandSignal" SG_ 980 IPS_TEL_DCDCFaultLampInd 0;
BA_ "GatewayedSignals" SG_ 980 IPS_TEL_DCDCFaultLampInd 0;
BA_ "GenSigSendType" SG_ 980 IPS_TEL_DCDCFaultLampInd 1;
BA_ "EventCommandSignal" SG_ 980 IPS_TEL_DCDCTempOvrErr 0;
BA_ "GatewayedSignals" SG_ 980 IPS_TEL_DCDCTempOvrErr 0;
BA_ "GenSigSendType" SG_ 980 IPS_TEL_DCDCTempOvrErr 1;
BA_ "EventCommandSignal" SG_ 980 IPS_TEL_DCDCModeSt 0;
BA_ "GatewayedSignals" SG_ 980 IPS_TEL_DCDCModeSt 0;
BA_ "GenSigSendType" SG_ 980 IPS_TEL_DCDCModeSt 1;
BA_ "EventCommandSignal" SG_ 980 IPS_ExportCode 0;
BA_ "GatewayedSignals" SG_ 980 IPS_ExportCode 0;
BA_ "GenSigSendType" SG_ 980 IPS_ExportCode 1;
BA_ "EventCommandSignal" SG_ 980 IPS_DCDCState11 0;
BA_ "GatewayedSignals" SG_ 980 IPS_DCDCState11 0;
BA_ "GenSigSendType" SG_ 980 IPS_DCDCState11 1;
BA_ "EventCommandSignal" SG_ 980 IPS_SwVersion 0;
BA_ "GatewayedSignals" SG_ 980 IPS_SwVersion 0;
BA_ "GenSigSendType" SG_ 980 IPS_SwVersion 1;
BA_ "EventCommandSignal" SG_ 980 IPS_DCDCState9 0;
BA_ "GatewayedSignals" SG_ 980 IPS_DCDCState9 0;
BA_ "GenSigSendType" SG_ 980 IPS_DCDCState9 1;
BA_ "EventCommandSignal" SG_ 980 IPS_DCDCState10 0;
BA_ "GatewayedSignals" SG_ 980 IPS_DCDCState10 0;
BA_ "GenSigSendType" SG_ 980 IPS_DCDCState10 1;
BA_ "EventCommandSignal" SG_ 980 IPS_DCDCState12 0;
BA_ "GatewayedSignals" SG_ 980 IPS_DCDCState12 0;
BA_ "GenSigSendType" SG_ 980 IPS_DCDCState12 1;
BA_ "EventCommandSignal" SG_ 980 IPS_OBCState13 0;
BA_ "GatewayedSignals" SG_ 980 IPS_OBCState13 0;
BA_ "GenSigSendType" SG_ 980 IPS_OBCState13 1;
BA_ "EventCommandSignal" SG_ 1011 IPS_OBCDiagErrCode 0;
BA_ "GatewayedSignals" SG_ 1011 IPS_OBCDiagErrCode 0;
BA_ "GenSigSendType" SG_ 1011 IPS_OBCDiagErrCode 1;
BA_ "EventCommandSignal" SG_ 1011 IPS_DCDCDiagErrCode 0;
BA_ "GatewayedSignals" SG_ 1011 IPS_DCDCDiagErrCode 0;
BA_ "GenSigSendType" SG_ 1011 IPS_DCDCDiagErrCode 1;
BA_ "EventCommandSignal" SG_ 1011 IPS_6_MsgCounter 0;
BA_ "GatewayedSignals" SG_ 1011 IPS_6_MsgCounter 0;
BA_ "GenSigSendType" SG_ 1011 IPS_6_MsgCounter 1;
BA_ "EventCommandSignal" SG_ 1011 IPS_DCDCState6 0;
BA_ "GatewayedSignals" SG_ 1011 IPS_DCDCState6 0;
BA_ "GenSigSendType" SG_ 1011 IPS_DCDCState6 1;
BA_ "EventCommandSignal" SG_ 1011 IPS_DCDCState7 0;
BA_ "GatewayedSignals" SG_ 1011 IPS_DCDCState7 0;
BA_ "GenSigSendType" SG_ 1011 IPS_DCDCState7 1;
BA_ "EventCommandSignal" SG_ 1011 IPS_DCDCState8 0;
BA_ "GatewayedSignals" SG_ 1011 IPS_DCDCState8 0;
BA_ "GenSigSendType" SG_ 1011 IPS_DCDCState8 1;
BA_ "EventCommandSignal" SG_ 1011 IPS_DCDCHVPwr 0;
BA_ "GatewayedSignals" SG_ 1011 IPS_DCDCHVPwr 0;
BA_ "GenSigSendType" SG_ 1011 IPS_DCDCHVPwr 1;
BA_ "EventCommandSignal" SG_ 1011 IPS_6_Checksum 0;
BA_ "GatewayedSignals" SG_ 1011 IPS_6_Checksum 0;
BA_ "GenSigSendType" SG_ 1011 IPS_6_Checksum 1;
BA_ "GenSigStartValue" SG_ 1011 IPS_6_Checksum 85;
BA_ "EventCommandSignal" SG_ 531 EVCC_OBC_CPDutycycle 0;
BA_ "GatewayedSignals" SG_ 531 EVCC_OBC_CPDutycycle 0;
BA_ "GenSigSendType" SG_ 531 EVCC_OBC_CPDutycycle 1;
BA_ "EventCommandSignal" SG_ 531 EVCC_S2_Drive 0;
BA_ "GatewayedSignals" SG_ 531 EVCC_S2_Drive 0;
BA_ "GenSigSendType" SG_ 531 EVCC_S2_Drive 1;
BA_ "EventCommandSignal" SG_ 531 EVCC_OBC_CpFreqSt 0;
BA_ "GatewayedSignals" SG_ 531 EVCC_OBC_CpFreqSt 0;
BA_ "GenSigSendType" SG_ 531 EVCC_OBC_CpFreqSt 1;
BA_ "EventCommandSignal" SG_ 531 EVCC_CCOUT_Drive 0;
BA_ "GatewayedSignals" SG_ 531 EVCC_CCOUT_Drive 0;
BA_ "GenSigSendType" SG_ 531 EVCC_CCOUT_Drive 1;
BA_ "EventCommandSignal" SG_ 531 EVCC_lostECAN 0;
BA_ "GatewayedSignals" SG_ 531 EVCC_lostECAN 0;
BA_ "GenSigSendType" SG_ 531 EVCC_lostECAN 1;
BA_ "EventCommandSignal" SG_ 531 EVCC_EVSERSNToNORMSCHG 0;
BA_ "GatewayedSignals" SG_ 531 EVCC_EVSERSNToNORMSCHG 0;
BA_ "GenSigSendType" SG_ 531 EVCC_EVSERSNToNORMSCHG 1;
BA_ "EventCommandSignal" SG_ 745 PTC_DownShiftSt 0;
BA_ "GatewayedSignals" SG_ 745 PTC_DownShiftSt 0;
BA_ "GenSigSendType" SG_ 745 PTC_DownShiftSt 1;
BA_ "EventCommandSignal" SG_ 745 PTC_UpShiftSt 0;
BA_ "GatewayedSignals" SG_ 745 PTC_UpShiftSt 0;
BA_ "GenSigSendType" SG_ 745 PTC_UpShiftSt 1;
BA_ "EventCommandSignal" SG_ 745 PTC_HeatPower 0;
BA_ "GatewayedSignals" SG_ 745 PTC_HeatPower 0;
BA_ "GenSigSendType" SG_ 745 PTC_HeatPower 1;
BA_ "EventCommandSignal" SG_ 745 PTC_HeatCurrent 0;
BA_ "GatewayedSignals" SG_ 745 PTC_HeatCurrent 0;
BA_ "GenSigSendType" SG_ 745 PTC_HeatCurrent 1;
BA_ "EventCommandSignal" SG_ 745 PTC_Fault 0;
BA_ "GatewayedSignals" SG_ 745 PTC_Fault 0;
BA_ "GenSigSendType" SG_ 745 PTC_Fault 1;
BA_ "EventCommandSignal" SG_ 745 PTC_InterTemp 0;
BA_ "GatewayedSignals" SG_ 745 PTC_InterTemp 0;
BA_ "GenSigSendType" SG_ 745 PTC_InterTemp 1;
BA_ "GenSigStartValue" SG_ 745 PTC_InterTemp 511;
BA_ "EventCommandSignal" SG_ 745 PTC_MOSTemp 0;
BA_ "GatewayedSignals" SG_ 745 PTC_MOSTemp 0;
BA_ "GenSigSendType" SG_ 745 PTC_MOSTemp 1;
BA_ "GenSigStartValue" SG_ 745 PTC_MOSTemp 255;
BA_ "EventCommandSignal" SG_ 745 PTC_ModeSt 0;
BA_ "GatewayedSignals" SG_ 745 PTC_ModeSt 0;
BA_ "GenSigSendType" SG_ 745 PTC_ModeSt 1;
BA_ "EventCommandSignal" SG_ 745 PTC_1_MsgCounter 0;
BA_ "GatewayedSignals" SG_ 745 PTC_1_MsgCounter 0;
BA_ "GenSigSendType" SG_ 745 PTC_1_MsgCounter 1;
BA_ "EventCommandSignal" SG_ 745 PTC_1_Checksum 0;
BA_ "GatewayedSignals" SG_ 745 PTC_1_Checksum 0;
BA_ "GenSigSendType" SG_ 745 PTC_1_Checksum 1;
BA_ "GenSigStartValue" SG_ 745 PTC_1_Checksum 85;
BA_ "EventCommandSignal" SG_ 369 DCU_RotSpdAct 0;
BA_ "GatewayedSignals" SG_ 369 DCU_RotSpdAct 0;
BA_ "GenSigInvalidValue" SG_ 369 DCU_RotSpdAct 65535;
BA_ "GenSigSendType" SG_ 369 DCU_RotSpdAct 1;
BA_ "GenSigStartValue" SG_ 369 DCU_RotSpdAct 32767;
BA_ "EventCommandSignal" SG_ 369 DCU_IdcAct 0;
BA_ "GatewayedSignals" SG_ 369 DCU_IdcAct 0;
BA_ "GenSigSendType" SG_ 369 DCU_IdcAct 1;
BA_ "GenSigStartValue" SG_ 369 DCU_IdcAct 1023;
BA_ "EventCommandSignal" SG_ 369 DCU_UdcAct 0;
BA_ "GatewayedSignals" SG_ 369 DCU_UdcAct 0;
BA_ "GenSigSendType" SG_ 369 DCU_UdcAct 1;
BA_ "EventCommandSignal" SG_ 369 DCU_TorqAct 0;
BA_ "GatewayedSignals" SG_ 369 DCU_TorqAct 0;
BA_ "GenSigSendType" SG_ 369 DCU_TorqAct 1;
BA_ "GenSigStartValue" SG_ 369 DCU_TorqAct 1023;
BA_ "GenSigTimeoutValue" SG_ 369 DCU_TorqAct 1023;
BA_ "EventCommandSignal" SG_ 369 DCU_1_MsgCounter 0;
BA_ "GatewayedSignals" SG_ 369 DCU_1_MsgCounter 0;
BA_ "GenSigSendType" SG_ 369 DCU_1_MsgCounter 1;
BA_ "EventCommandSignal" SG_ 369 DCU_ModeSt 0;
BA_ "GatewayedSignals" SG_ 369 DCU_ModeSt 0;
BA_ "GenSigSendType" SG_ 369 DCU_ModeSt 1;
BA_ "GenSigStartValue" SG_ 369 DCU_ModeSt 1;
BA_ "EventCommandSignal" SG_ 369 DCU_1_Checksum 0;
BA_ "GatewayedSignals" SG_ 369 DCU_1_Checksum 0;
BA_ "GenSigSendType" SG_ 369 DCU_1_Checksum 1;
BA_ "GenSigStartValue" SG_ 369 DCU_1_Checksum 85;
BA_ "EventCommandSignal" SG_ 377 DCU_bBigDataFlag 0;
BA_ "GatewayedSignals" SG_ 377 DCU_bBigDataFlag 0;
BA_ "GenSigSendType" SG_ 377 DCU_bBigDataFlag 1;
BA_ "EventCommandSignal" SG_ 377 DCU_Err2NoticeFlag 0;
BA_ "GatewayedSignals" SG_ 377 DCU_Err2NoticeFlag 0;
BA_ "GenSigSendType" SG_ 377 DCU_Err2NoticeFlag 1;
BA_ "EventCommandSignal" SG_ 377 DCU_ErrNotice 0;
BA_ "GatewayedSignals" SG_ 377 DCU_ErrNotice 0;
BA_ "GenSigSendType" SG_ 377 DCU_ErrNotice 1;
BA_ "EventCommandSignal" SG_ 377 DCU_ErrNoticeOperFlag 0;
BA_ "GatewayedSignals" SG_ 377 DCU_ErrNoticeOperFlag 0;
BA_ "GenSigSendType" SG_ 377 DCU_ErrNoticeOperFlag 1;
BA_ "EventCommandSignal" SG_ 377 DCU_AHFPowerEst 0;
BA_ "GatewayedSignals" SG_ 377 DCU_AHFPowerEst 0;
BA_ "GenSigSendType" SG_ 377 DCU_AHFPowerEst 1;
BA_ "EventCommandSignal" SG_ 377 DCU_ErrorLv3St 0;
BA_ "GatewayedSignals" SG_ 377 DCU_ErrorLv3St 0;
BA_ "GenSigSendType" SG_ 377 DCU_ErrorLv3St 1;
BA_ "EventCommandSignal" SG_ 377 DCU_RemoteDiagCode 0;
BA_ "GatewayedSignals" SG_ 377 DCU_RemoteDiagCode 0;
BA_ "GenSigSendType" SG_ 377 DCU_RemoteDiagCode 1;
BA_ "EventCommandSignal" SG_ 377 DCU_TypeSt 0;
BA_ "GatewayedSignals" SG_ 377 DCU_TypeSt 0;
BA_ "GenSigSendType" SG_ 377 DCU_TypeSt 1;
BA_ "EventCommandSignal" SG_ 377 DCU_AHFModeSt 0;
BA_ "GatewayedSignals" SG_ 377 DCU_AHFModeSt 0;
BA_ "GenSigSendType" SG_ 377 DCU_AHFModeSt 1;
BA_ "EventCommandSignal" SG_ 377 DCU_2_MsgCounter 0;
BA_ "GatewayedSignals" SG_ 377 DCU_2_MsgCounter 0;
BA_ "GenSigSendType" SG_ 377 DCU_2_MsgCounter 1;
BA_ "EventCommandSignal" SG_ 377 DCU_bDiagReq 0;
BA_ "GatewayedSignals" SG_ 377 DCU_bDiagReq 0;
BA_ "GenSigSendType" SG_ 377 DCU_bDiagReq 1;
BA_ "EventCommandSignal" SG_ 377 DCU_bReadyHV 0;
BA_ "GatewayedSignals" SG_ 377 DCU_bReadyHV 0;
BA_ "GenSigSendType" SG_ 377 DCU_bReadyHV 1;
BA_ "EventCommandSignal" SG_ 377 DCU_OffsetCalInd 0;
BA_ "GatewayedSignals" SG_ 377 DCU_OffsetCalInd 0;
BA_ "GenSigSendType" SG_ 377 DCU_OffsetCalInd 1;
BA_ "EventCommandSignal" SG_ 377 DCU_2_Checksum 0;
BA_ "GatewayedSignals" SG_ 377 DCU_2_Checksum 0;
BA_ "GenSigSendType" SG_ 377 DCU_2_Checksum 1;
BA_ "GenSigStartValue" SG_ 377 DCU_2_Checksum 85;
BA_ "EventCommandSignal" SG_ 385 DCU_TorqMax 0;
BA_ "GatewayedSignals" SG_ 385 DCU_TorqMax 0;
BA_ "GenSigSendType" SG_ 385 DCU_TorqMax 1;
BA_ "EventCommandSignal" SG_ 385 DCU_TorqMin 0;
BA_ "GatewayedSignals" SG_ 385 DCU_TorqMin 0;
BA_ "GenSigSendType" SG_ 385 DCU_TorqMin 1;
BA_ "GenSigStartValue" SG_ 385 DCU_TorqMin 1023;
BA_ "EventCommandSignal" SG_ 385 DCU_HvilSt 0;
BA_ "GatewayedSignals" SG_ 385 DCU_HvilSt 0;
BA_ "GenSigSendType" SG_ 385 DCU_HvilSt 1;
BA_ "EventCommandSignal" SG_ 385 DCU_SelfTorqMax 0;
BA_ "GatewayedSignals" SG_ 385 DCU_SelfTorqMax 0;
BA_ "GenSigSendType" SG_ 385 DCU_SelfTorqMax 1;
BA_ "EventCommandSignal" SG_ 385 DCU_SpdLmtActiveSt 0;
BA_ "GatewayedSignals" SG_ 385 DCU_SpdLmtActiveSt 0;
BA_ "GenSigSendType" SG_ 385 DCU_SpdLmtActiveSt 1;
BA_ "EventCommandSignal" SG_ 385 DCU_SelfTorqMin 0;
BA_ "GatewayedSignals" SG_ 385 DCU_SelfTorqMin 0;
BA_ "GenSigSendType" SG_ 385 DCU_SelfTorqMin 1;
BA_ "GenSigStartValue" SG_ 385 DCU_SelfTorqMin 1023;
BA_ "EventCommandSignal" SG_ 385 DCU_DiagErrCode 0;
BA_ "GatewayedSignals" SG_ 385 DCU_DiagErrCode 0;
BA_ "GenSigSendType" SG_ 385 DCU_DiagErrCode 1;
BA_ "EventCommandSignal" SG_ 385 DCU_DstActive 0;
BA_ "GatewayedSignals" SG_ 385 DCU_DstActive 0;
BA_ "GenSigSendType" SG_ 385 DCU_DstActive 1;
BA_ "EventCommandSignal" SG_ 385 DCU_GateDrvSt 0;
BA_ "GatewayedSignals" SG_ 385 DCU_GateDrvSt 0;
BA_ "GenSigSendType" SG_ 385 DCU_GateDrvSt 1;
BA_ "EventCommandSignal" SG_ 385 DCU_3_MsgCounter 0;
BA_ "GatewayedSignals" SG_ 385 DCU_3_MsgCounter 0;
BA_ "GenSigSendType" SG_ 385 DCU_3_MsgCounter 1;
BA_ "EventCommandSignal" SG_ 385 DCU_3_Checksum 0;
BA_ "GatewayedSignals" SG_ 385 DCU_3_Checksum 0;
BA_ "GenSigSendType" SG_ 385 DCU_3_Checksum 1;
BA_ "GenSigStartValue" SG_ 385 DCU_3_Checksum 85;
BA_ "EventCommandSignal" SG_ 882 DCU_InvtTemp 0;
BA_ "GatewayedSignals" SG_ 882 DCU_InvtTemp 0;
BA_ "GenSigSendType" SG_ 882 DCU_InvtTemp 1;
BA_ "GenSigStartValue" SG_ 882 DCU_InvtTemp 40;
BA_ "EventCommandSignal" SG_ 882 DCU_VoltageT30 0;
BA_ "GatewayedSignals" SG_ 882 DCU_VoltageT30 0;
BA_ "GenSigSendType" SG_ 882 DCU_VoltageT30 1;
BA_ "EventCommandSignal" SG_ 882 DCU_SysTempOvrInd 0;
BA_ "GatewayedSignals" SG_ 882 DCU_SysTempOvrInd 0;
BA_ "GenSigSendType" SG_ 882 DCU_SysTempOvrInd 1;
BA_ "EventCommandSignal" SG_ 882 DCU_RotTemp 0;
BA_ "GatewayedSignals" SG_ 882 DCU_RotTemp 0;
BA_ "GenSigSendType" SG_ 882 DCU_RotTemp 1;
BA_ "GenSigStartValue" SG_ 882 DCU_RotTemp 40;
BA_ "EventCommandSignal" SG_ 882 DCU_CooltReq 0;
BA_ "GatewayedSignals" SG_ 882 DCU_CooltReq 0;
BA_ "GenSigSendType" SG_ 882 DCU_CooltReq 1;
BA_ "EventCommandSignal" SG_ 882 DCU_FaultLampInd 0;
BA_ "GatewayedSignals" SG_ 882 DCU_FaultLampInd 0;
BA_ "GenSigSendType" SG_ 882 DCU_FaultLampInd 1;
BA_ "EventCommandSignal" SG_ 882 DCU_StatTemp 0;
BA_ "GatewayedSignals" SG_ 882 DCU_StatTemp 0;
BA_ "GenSigSendType" SG_ 882 DCU_StatTemp 1;
BA_ "GenSigStartValue" SG_ 882 DCU_StatTemp 40;
BA_ "EventCommandSignal" SG_ 882 DCU_TempCoolant 0;
BA_ "GatewayedSignals" SG_ 882 DCU_TempCoolant 0;
BA_ "GenSigSendType" SG_ 882 DCU_TempCoolant 1;
BA_ "GenSigStartValue" SG_ 882 DCU_TempCoolant 40;
BA_ "EventCommandSignal" SG_ 882 DCU_8_MsgCounter 0;
BA_ "GatewayedSignals" SG_ 882 DCU_8_MsgCounter 0;
BA_ "GenSigSendType" SG_ 882 DCU_8_MsgCounter 1;
BA_ "EventCommandSignal" SG_ 882 DCU_8_Checksum 0;
BA_ "GatewayedSignals" SG_ 882 DCU_8_Checksum 0;
BA_ "GenSigSendType" SG_ 882 DCU_8_Checksum 1;
BA_ "GenSigStartValue" SG_ 882 DCU_8_Checksum 85;
BA_ "EventCommandSignal" SG_ 910 DCU_DataNo 0;
BA_ "GatewayedSignals" SG_ 910 DCU_DataNo 0;
BA_ "GenSigSendType" SG_ 910 DCU_DataNo 1;
BA_ "GenSigStartValue" SG_ 910 DCU_DataNo 1;
BA_ "EventCommandSignal" SG_ 910 DCU_TEL_MotorNumOrder 0;
BA_ "GatewayedSignals" SG_ 910 DCU_TEL_MotorNumOrder 0;
BA_ "GenSigSendType" SG_ 910 DCU_TEL_MotorNumOrder 1;
BA_ "EventCommandSignal" SG_ 910 DCU_TEL_ECUTempOvrErr 0;
BA_ "GatewayedSignals" SG_ 910 DCU_TEL_ECUTempOvrErr 0;
BA_ "GenSigSendType" SG_ 910 DCU_TEL_ECUTempOvrErr 1;
BA_ "EventCommandSignal" SG_ 910 DCU_TEL_MotTempOvrErr 0;
BA_ "GatewayedSignals" SG_ 910 DCU_TEL_MotTempOvrErr 0;
BA_ "GenSigSendType" SG_ 910 DCU_TEL_MotTempOvrErr 1;
BA_ "EventCommandSignal" SG_ 910 DCU_TEL_MotorNumTotal 0;
BA_ "GatewayedSignals" SG_ 910 DCU_TEL_MotorNumTotal 0;
BA_ "GenSigSendType" SG_ 910 DCU_TEL_MotorNumTotal 1;
BA_ "EventCommandSignal" SG_ 910 DCU_TEL_InvtTemp 0;
BA_ "GatewayedSignals" SG_ 910 DCU_TEL_InvtTemp 0;
BA_ "GenSigInvalidValue" SG_ 910 DCU_TEL_InvtTemp 255;
BA_ "GenSigSendType" SG_ 910 DCU_TEL_InvtTemp 1;
BA_ "GenSigStartValue" SG_ 910 DCU_TEL_InvtTemp 40;
BA_ "EventCommandSignal" SG_ 910 DCU_TEL_RotSpdAct 0;
BA_ "GatewayedSignals" SG_ 910 DCU_TEL_RotSpdAct 0;
BA_ "GenSigInvalidValue" SG_ 910 DCU_TEL_RotSpdAct 65535;
BA_ "GenSigSendType" SG_ 910 DCU_TEL_RotSpdAct 1;
BA_ "EventCommandSignal" SG_ 910 DCU_TEL_TorqAct 0;
BA_ "GatewayedSignals" SG_ 910 DCU_TEL_TorqAct 0;
BA_ "GenSigInvalidValue" SG_ 910 DCU_TEL_TorqAct 65535;
BA_ "GenSigSendType" SG_ 910 DCU_TEL_TorqAct 1;
BA_ "EventCommandSignal" SG_ 910 DCU_TEL_StatTemp 0;
BA_ "GatewayedSignals" SG_ 910 DCU_TEL_StatTemp 0;
BA_ "GenSigInvalidValue" SG_ 910 DCU_TEL_StatTemp 255;
BA_ "GenSigSendType" SG_ 910 DCU_TEL_StatTemp 1;
BA_ "GenSigStartValue" SG_ 910 DCU_TEL_StatTemp 40;
BA_ "EventCommandSignal" SG_ 910 DCU_TEL_ModeSt 0;
BA_ "GatewayedSignals" SG_ 910 DCU_TEL_ModeSt 0;
BA_ "GenSigSendType" SG_ 910 DCU_TEL_ModeSt 1;
BA_ "EventCommandSignal" SG_ 910 DCU_TEL_CurrActAmend 0;
BA_ "GatewayedSignals" SG_ 910 DCU_TEL_CurrActAmend 0;
BA_ "GenSigSendType" SG_ 910 DCU_TEL_CurrActAmend 1;
BA_ "EventCommandSignal" SG_ 910 DCU_TEL_UdcAct 0;
BA_ "GatewayedSignals" SG_ 910 DCU_TEL_UdcAct 0;
BA_ "GenSigSendType" SG_ 910 DCU_TEL_UdcAct 1;
BA_ "EventCommandSignal" SG_ 910 DCU_TEL_BattCurr 0;
BA_ "GatewayedSignals" SG_ 910 DCU_TEL_BattCurr 0;
BA_ "GenSigSendType" SG_ 910 DCU_TEL_BattCurr 1;
BA_ "EventCommandSignal" SG_ 376 DCU_ADC_MCUBlkst 0;
BA_ "GatewayedSignals" SG_ 376 DCU_ADC_MCUBlkst 0;
BA_ "GenSigInvalidValue" SG_ 376 DCU_ADC_MCUBlkst 7;
BA_ "GenSigSendType" SG_ 376 DCU_ADC_MCUBlkst 1;
BA_ "Remark" SG_ 376 DCU_ADC_MCUBlkst "智驾3.0接口";
BA_ "EventCommandSignal" SG_ 376 DCU_ADC_SpdSvModAvl 0;
BA_ "GatewayedSignals" SG_ 376 DCU_ADC_SpdSvModAvl 0;
BA_ "GenSigSendType" SG_ 376 DCU_ADC_SpdSvModAvl 1;
BA_ "Remark" SG_ 376 DCU_ADC_SpdSvModAvl "智驾3.0接口";
BA_ "EventCommandSignal" SG_ 376 DCU_ADC_MCUStandstill 0;
BA_ "GatewayedSignals" SG_ 376 DCU_ADC_MCUStandstill 0;
BA_ "GenSigSendType" SG_ 376 DCU_ADC_MCUStandstill 1;
BA_ "Remark" SG_ 376 DCU_ADC_MCUStandstill "智驾3.0接口";
BA_ "EventCommandSignal" SG_ 376 DCU_ADC_MCUSpdSVModFit 0;
BA_ "GatewayedSignals" SG_ 376 DCU_ADC_MCUSpdSVModFit 0;
BA_ "GenSigInvalidValue" SG_ 376 DCU_ADC_MCUSpdSVModFit 7;
BA_ "GenSigSendType" SG_ 376 DCU_ADC_MCUSpdSVModFit 1;
BA_ "Remark" SG_ 376 DCU_ADC_MCUSpdSVModFit "智驾3.0接口";
BA_ "EventCommandSignal" SG_ 376 DCU_ADC_MCUVehSldSt 0;
BA_ "GatewayedSignals" SG_ 376 DCU_ADC_MCUVehSldSt 0;
BA_ "GenSigSendType" SG_ 376 DCU_ADC_MCUVehSldSt 1;
BA_ "Remark" SG_ 376 DCU_ADC_MCUVehSldSt "智驾3.0接口";
BA_ "EventCommandSignal" SG_ 376 DCU_ADC_ModeSt 0;
BA_ "GatewayedSignals" SG_ 376 DCU_ADC_ModeSt 0;
BA_ "GenSigSendType" SG_ 376 DCU_ADC_ModeSt 1;
BA_ "GenSigStartValue" SG_ 376 DCU_ADC_ModeSt 1;
BA_ "Remark" SG_ 376 DCU_ADC_ModeSt "智驾3.0接口";
BA_ "EventCommandSignal" SG_ 376 DCU_ADC_MCUReqTq 0;
BA_ "GatewayedSignals" SG_ 376 DCU_ADC_MCUReqTq 0;
BA_ "GenSigInvalidValue" SG_ 376 DCU_ADC_MCUReqTq 2047;
BA_ "GenSigSendType" SG_ 376 DCU_ADC_MCUReqTq 1;
BA_ "GenSigStartValue" SG_ 376 DCU_ADC_MCUReqTq 1023;
BA_ "Remark" SG_ 376 DCU_ADC_MCUReqTq "智驾3.0接口";
BA_ "EventCommandSignal" SG_ 376 DCU_ADC_RotSpdAct 0;
BA_ "GatewayedSignals" SG_ 376 DCU_ADC_RotSpdAct 0;
BA_ "GenSigInvalidValue" SG_ 376 DCU_ADC_RotSpdAct 65535;
BA_ "GenSigSendType" SG_ 376 DCU_ADC_RotSpdAct 1;
BA_ "GenSigStartValue" SG_ 376 DCU_ADC_RotSpdAct 32767;
BA_ "Remark" SG_ 376 DCU_ADC_RotSpdAct "智驾3.0接口";
BA_ "EventCommandSignal" SG_ 376 DCU_10_MsgCounter 0;
BA_ "GatewayedSignals" SG_ 376 DCU_10_MsgCounter 0;
BA_ "GenSigSendType" SG_ 376 DCU_10_MsgCounter 1;
BA_ "Remark" SG_ 376 DCU_10_MsgCounter "智驾3.0接口";
BA_ "EventCommandSignal" SG_ 376 DCU_10_Checksum 0;
BA_ "GatewayedSignals" SG_ 376 DCU_10_Checksum 0;
BA_ "GenSigSendType" SG_ 376 DCU_10_Checksum 1;
BA_ "Remark" SG_ 376 DCU_10_Checksum "智驾3.0接口";
BA_ "EventCommandSignal" SG_ 752 DCU_AHFPwrMax 0;
BA_ "GatewayedSignals" SG_ 752 DCU_AHFPwrMax 0;
BA_ "GenSigSendType" SG_ 752 DCU_AHFPwrMax 1;
BA_ "EventCommandSignal" SG_ 752 DCU_AHFPwrMin 0;
BA_ "GatewayedSignals" SG_ 752 DCU_AHFPwrMin 0;
BA_ "GenSigSendType" SG_ 752 DCU_AHFPwrMin 1;
BA_ "EventCommandSignal" SG_ 752 DCU_AHFTorqueReq 0;
BA_ "GatewayedSignals" SG_ 752 DCU_AHFTorqueReq 0;
BA_ "GenSigInvalidValue" SG_ 752 DCU_AHFTorqueReq 2048;
BA_ "GenSigSendType" SG_ 752 DCU_AHFTorqueReq 1;
BA_ "EventCommandSignal" SG_ 752 DCU_AHFTorqueAct 0;
BA_ "GatewayedSignals" SG_ 752 DCU_AHFTorqueAct 0;
BA_ "GenSigInvalidValue" SG_ 752 DCU_AHFTorqueAct 2048;
BA_ "GenSigSendType" SG_ 752 DCU_AHFTorqueAct 1;
BA_ "EventCommandSignal" SG_ 752 DCU_11_MsgCounter 0;
BA_ "GatewayedSignals" SG_ 752 DCU_11_MsgCounter 0;
BA_ "GenSigSendType" SG_ 752 DCU_11_MsgCounter 1;
BA_ "EventCommandSignal" SG_ 752 DCU_11_Checksum 0;
BA_ "GatewayedSignals" SG_ 752 DCU_11_Checksum 0;
BA_ "GenSigSendType" SG_ 752 DCU_11_Checksum 1;
BA_ "GenSigStartValue" SG_ 752 DCU_11_Checksum 85;
BA_ "EventCommandSignal" SG_ 753 DCU_FusastSafePathReq 0;
BA_ "GatewayedSignals" SG_ 753 DCU_FusastSafePathReq 0;
BA_ "GenSigSendType" SG_ 753 DCU_FusastSafePathReq 1;
BA_ "EventCommandSignal" SG_ 753 DCU_FusaQDisChargeReq 0;
BA_ "GatewayedSignals" SG_ 753 DCU_FusaQDisChargeReq 0;
BA_ "GenSigSendType" SG_ 753 DCU_FusaQDisChargeReq 1;
BA_ "EventCommandSignal" SG_ 753 DCU_FusaModeSt 0;
BA_ "GatewayedSignals" SG_ 753 DCU_FusaModeSt 0;
BA_ "GenSigSendType" SG_ 753 DCU_FusaModeSt 1;
BA_ "EventCommandSignal" SG_ 753 DCU_FusastPWMEna 0;
BA_ "GatewayedSignals" SG_ 753 DCU_FusastPWMEna 0;
BA_ "GenSigSendType" SG_ 753 DCU_FusastPWMEna 1;
BA_ "EventCommandSignal" SG_ 753 DCU_FusaErrCode 0;
BA_ "GatewayedSignals" SG_ 753 DCU_FusaErrCode 0;
BA_ "GenSigSendType" SG_ 753 DCU_FusaErrCode 1;
BA_ "EventCommandSignal" SG_ 753 DCU_FusaTorqAct 0;
BA_ "GatewayedSignals" SG_ 753 DCU_FusaTorqAct 0;
BA_ "GenSigSendType" SG_ 753 DCU_FusaTorqAct 1;
BA_ "EventCommandSignal" SG_ 753 DCU_FusaRotSpdAct 0;
BA_ "GatewayedSignals" SG_ 753 DCU_FusaRotSpdAct 0;
BA_ "GenSigSendType" SG_ 753 DCU_FusaRotSpdAct 1;
BA_ "EventCommandSignal" SG_ 753 DCU_12_MsgCounter 0;
BA_ "GatewayedSignals" SG_ 753 DCU_12_MsgCounter 0;
BA_ "GenSigSendType" SG_ 753 DCU_12_MsgCounter 1;
BA_ "EventCommandSignal" SG_ 753 DCU_12_Checksum 0;
BA_ "GatewayedSignals" SG_ 753 DCU_12_Checksum 0;
BA_ "GenSigSendType" SG_ 753 DCU_12_Checksum 1;
BA_ "GenSigStartValue" SG_ 753 DCU_12_Checksum 85;
BA_ "EventCommandSignal" SG_ 555 DCU_EOP_SpdSet 0;
BA_ "GatewayedSignals" SG_ 555 DCU_EOP_SpdSet 0;
BA_ "GenSigSendType" SG_ 555 DCU_EOP_SpdSet 1;
BA_ "EventCommandSignal" SG_ 555 DCU_EOP_OilTempAct 0;
BA_ "GatewayedSignals" SG_ 555 DCU_EOP_OilTempAct 0;
BA_ "GenSigSendType" SG_ 555 DCU_EOP_OilTempAct 1;
BA_ "GenSigStartValue" SG_ 555 DCU_EOP_OilTempAct 100;
BA_ "EventCommandSignal" SG_ 555 DCU_EOP_TrqAntiJerk 0;
BA_ "GatewayedSignals" SG_ 555 DCU_EOP_TrqAntiJerk 0;
BA_ "GenSigSendType" SG_ 555 DCU_EOP_TrqAntiJerk 1;
BA_ "EventCommandSignal" SG_ 555 DCU_EOP_stTorqLmtTsc 0;
BA_ "GatewayedSignals" SG_ 555 DCU_EOP_stTorqLmtTsc 0;
BA_ "GenSigSendType" SG_ 555 DCU_EOP_stTorqLmtTsc 1;
BA_ "EventCommandSignal" SG_ 555 DCU_EOP_1_MsgCounter 0;
BA_ "GatewayedSignals" SG_ 555 DCU_EOP_1_MsgCounter 0;
BA_ "GenSigSendType" SG_ 555 DCU_EOP_1_MsgCounter 1;
BA_ "EventCommandSignal" SG_ 555 DCU_EOP_1_Checksum 0;
BA_ "GatewayedSignals" SG_ 555 DCU_EOP_1_Checksum 0;
BA_ "GenSigSendType" SG_ 555 DCU_EOP_1_Checksum 1;
BA_ "GenSigStartValue" SG_ 555 DCU_EOP_1_Checksum 85;
BA_ "EventCommandSignal" SG_ 920 DCU_BigData_Byte1 0;
BA_ "GatewayedSignals" SG_ 920 DCU_BigData_Byte1 0;
BA_ "GenSigSendType" SG_ 920 DCU_BigData_Byte1 1;
BA_ "Remark" SG_ 920 DCU_BigData_Byte1 "埃安DCU大数据报文";
BA_ "EventCommandSignal" SG_ 920 DCU_BigData_Byte2 0;
BA_ "GatewayedSignals" SG_ 920 DCU_BigData_Byte2 0;
BA_ "GenSigSendType" SG_ 920 DCU_BigData_Byte2 1;
BA_ "Remark" SG_ 920 DCU_BigData_Byte2 "埃安DCU大数据报文";
BA_ "EventCommandSignal" SG_ 920 DCU_BigData_Byte3 0;
BA_ "GatewayedSignals" SG_ 920 DCU_BigData_Byte3 0;
BA_ "GenSigSendType" SG_ 920 DCU_BigData_Byte3 1;
BA_ "Remark" SG_ 920 DCU_BigData_Byte3 "埃安DCU大数据报文";
BA_ "EventCommandSignal" SG_ 920 DCU_BigData_Byte4 0;
BA_ "GatewayedSignals" SG_ 920 DCU_BigData_Byte4 0;
BA_ "GenSigSendType" SG_ 920 DCU_BigData_Byte4 1;
BA_ "Remark" SG_ 920 DCU_BigData_Byte4 "埃安DCU大数据报文";
BA_ "EventCommandSignal" SG_ 920 DCU_BigData_Byte5 0;
BA_ "GatewayedSignals" SG_ 920 DCU_BigData_Byte5 0;
BA_ "GenSigSendType" SG_ 920 DCU_BigData_Byte5 1;
BA_ "Remark" SG_ 920 DCU_BigData_Byte5 "埃安DCU大数据报文";
BA_ "EventCommandSignal" SG_ 920 DCU_BigData_Byte6 0;
BA_ "GatewayedSignals" SG_ 920 DCU_BigData_Byte6 0;
BA_ "GenSigSendType" SG_ 920 DCU_BigData_Byte6 1;
BA_ "Remark" SG_ 920 DCU_BigData_Byte6 "埃安DCU大数据报文";
BA_ "EventCommandSignal" SG_ 920 DCU_BigData_Byte7 0;
BA_ "GatewayedSignals" SG_ 920 DCU_BigData_Byte7 0;
BA_ "GenSigSendType" SG_ 920 DCU_BigData_Byte7 1;
BA_ "Remark" SG_ 920 DCU_BigData_Byte7 "埃安DCU大数据报文";
BA_ "EventCommandSignal" SG_ 920 DCU_BigData_Byte8 0;
BA_ "GatewayedSignals" SG_ 920 DCU_BigData_Byte8 0;
BA_ "GenSigSendType" SG_ 920 DCU_BigData_Byte8 1;
BA_ "Remark" SG_ 920 DCU_BigData_Byte8 "埃安DCU大数据报文";
BA_ "EventCommandSignal" SG_ 699 NIDU_BigDataNo 0;
BA_ "GatewayedSignals" SG_ 699 NIDU_BigDataNo 0;
BA_ "GenSigSendType" SG_ 699 NIDU_BigDataNo 1;
BA_ "GenSigStartValue" SG_ 699 NIDU_BigDataNo 1;
BA_ "Remark" SG_ 699 NIDU_BigDataNo "NIDU大数据报文";
BA_ "EventCommandSignal" SG_ 699 DCU_Fault1 0;
BA_ "GatewayedSignals" SG_ 699 DCU_Fault1 0;
BA_ "GenSigSendType" SG_ 699 DCU_Fault1 1;
BA_ "Remark" SG_ 699 DCU_Fault1 "NIDU大数据报文";
BA_ "EventCommandSignal" SG_ 699 DCU_Fault2 0;
BA_ "GatewayedSignals" SG_ 699 DCU_Fault2 0;
BA_ "GenSigSendType" SG_ 699 DCU_Fault2 1;
BA_ "Remark" SG_ 699 DCU_Fault2 "NIDU大数据报文";
BA_ "EventCommandSignal" SG_ 699 DCU_Fault3 0;
BA_ "GatewayedSignals" SG_ 699 DCU_Fault3 0;
BA_ "GenSigSendType" SG_ 699 DCU_Fault3 1;
BA_ "Remark" SG_ 699 DCU_Fault3 "NIDU大数据报文";
BA_ "EventCommandSignal" SG_ 699 DCU_Fault4 0;
BA_ "GatewayedSignals" SG_ 699 DCU_Fault4 0;
BA_ "GenSigSendType" SG_ 699 DCU_Fault4 1;
BA_ "Remark" SG_ 699 DCU_Fault4 "NIDU大数据报文";
BA_ "EventCommandSignal" SG_ 699 DCU_FusaFaultInfo7 0;
BA_ "GatewayedSignals" SG_ 699 DCU_FusaFaultInfo7 0;
BA_ "GenSigSendType" SG_ 699 DCU_FusaFaultInfo7 1;
BA_ "Remark" SG_ 699 DCU_FusaFaultInfo7 "NIDU大数据报文";
BA_ "EventCommandSignal" SG_ 699 DCU_FusaFaultInfo8 0;
BA_ "GatewayedSignals" SG_ 699 DCU_FusaFaultInfo8 0;
BA_ "GenSigSendType" SG_ 699 DCU_FusaFaultInfo8 1;
BA_ "Remark" SG_ 699 DCU_FusaFaultInfo8 "NIDU大数据报文";
BA_ "EventCommandSignal" SG_ 556 EOP_SpdAct 0;
BA_ "GatewayedSignals" SG_ 556 EOP_SpdAct 0;
BA_ "GenSigSendType" SG_ 556 EOP_SpdAct 1;
BA_ "EventCommandSignal" SG_ 556 EOP_IdcAct 0;
BA_ "GatewayedSignals" SG_ 556 EOP_IdcAct 0;
BA_ "GenSigSendType" SG_ 556 EOP_IdcAct 1;
BA_ "EventCommandSignal" SG_ 556 EOP_CANCommunicationFailure 0;
BA_ "GatewayedSignals" SG_ 556 EOP_CANCommunicationFailure 0;
BA_ "GenSigSendType" SG_ 556 EOP_CANCommunicationFailure 1;
BA_ "EventCommandSignal" SG_ 556 EOP_SensorFailure 0;
BA_ "GatewayedSignals" SG_ 556 EOP_SensorFailure 0;
BA_ "GenSigSendType" SG_ 556 EOP_SensorFailure 1;
BA_ "EventCommandSignal" SG_ 556 EOP_DriverCircuitFailure 0;
BA_ "GatewayedSignals" SG_ 556 EOP_DriverCircuitFailure 0;
BA_ "GenSigSendType" SG_ 556 EOP_DriverCircuitFailure 1;
BA_ "EventCommandSignal" SG_ 556 EOP_OverTemperature 0;
BA_ "GatewayedSignals" SG_ 556 EOP_OverTemperature 0;
BA_ "GenSigSendType" SG_ 556 EOP_OverTemperature 1;
BA_ "EventCommandSignal" SG_ 556 EOP_OverVoltage 0;
BA_ "GatewayedSignals" SG_ 556 EOP_OverVoltage 0;
BA_ "GenSigSendType" SG_ 556 EOP_OverVoltage 1;
BA_ "EventCommandSignal" SG_ 556 EOP_LowVoltage 0;
BA_ "GatewayedSignals" SG_ 556 EOP_LowVoltage 0;
BA_ "GenSigSendType" SG_ 556 EOP_LowVoltage 1;
BA_ "EventCommandSignal" SG_ 556 EOP_OverCurrent 0;
BA_ "GatewayedSignals" SG_ 556 EOP_OverCurrent 0;
BA_ "GenSigSendType" SG_ 556 EOP_OverCurrent 1;
BA_ "EventCommandSignal" SG_ 556 EOP_MotorStallingFailure 0;
BA_ "GatewayedSignals" SG_ 556 EOP_MotorStallingFailure 0;
BA_ "GenSigSendType" SG_ 556 EOP_MotorStallingFailure 1;
BA_ "EventCommandSignal" SG_ 556 EOP_ErrLevel 0;
BA_ "GatewayedSignals" SG_ 556 EOP_ErrLevel 0;
BA_ "GenSigSendType" SG_ 556 EOP_ErrLevel 1;
BA_ "EventCommandSignal" SG_ 556 EOP_LimitCurrentFlag 0;
BA_ "GatewayedSignals" SG_ 556 EOP_LimitCurrentFlag 0;
BA_ "GenSigSendType" SG_ 556 EOP_LimitCurrentFlag 1;
BA_ "EventCommandSignal" SG_ 556 EOP_SelfCheckSt 0;
BA_ "GatewayedSignals" SG_ 556 EOP_SelfCheckSt 0;
BA_ "GenSigSendType" SG_ 556 EOP_SelfCheckSt 1;
BA_ "EventCommandSignal" SG_ 556 EOP_UdcAct 0;
BA_ "GatewayedSignals" SG_ 556 EOP_UdcAct 0;
BA_ "GenSigSendType" SG_ 556 EOP_UdcAct 1;
BA_ "EventCommandSignal" SG_ 556 EOP_HighTempDePwrFlag 0;
BA_ "GatewayedSignals" SG_ 556 EOP_HighTempDePwrFlag 0;
BA_ "GenSigSendType" SG_ 556 EOP_HighTempDePwrFlag 1;
BA_ "EventCommandSignal" SG_ 556 EOP_1_MsgCounter 0;
BA_ "GatewayedSignals" SG_ 556 EOP_1_MsgCounter 0;
BA_ "GenSigSendType" SG_ 556 EOP_1_MsgCounter 1;
BA_ "EventCommandSignal" SG_ 556 EOP_1_Checksum 0;
BA_ "GatewayedSignals" SG_ 556 EOP_1_Checksum 0;
BA_ "GenSigSendType" SG_ 556 EOP_1_Checksum 1;
BA_ "GenSigStartValue" SG_ 556 EOP_1_Checksum 85;
BA_ "EventCommandSignal" SG_ 757 ITS_MotorLoopEstimatedFlow 0;
BA_ "GatewayedSignals" SG_ 757 ITS_MotorLoopEstimatedFlow 0;
BA_ "GenSigSendType" SG_ 757 ITS_MotorLoopEstimatedFlow 1;
BA_ "EventCommandSignal" SG_ 757 ITS_MotorLoopEstimatedFlowVD 0;
BA_ "GatewayedSignals" SG_ 757 ITS_MotorLoopEstimatedFlowVD 0;
BA_ "GenSigSendType" SG_ 757 ITS_MotorLoopEstimatedFlowVD 1;
BA_ "EventCommandSignal" SG_ 757 ITS_AHFSt 0;
BA_ "GatewayedSignals" SG_ 757 ITS_AHFSt 0;
BA_ "GenSigSendType" SG_ 757 ITS_AHFSt 1;
BA_ "EventCommandSignal" SG_ 757 ITS_AHFOnReq 0;
BA_ "GatewayedSignals" SG_ 757 ITS_AHFOnReq 0;
BA_ "GenSigSendType" SG_ 757 ITS_AHFOnReq 1;
BA_ "GenSigStartValue" SG_ 757 ITS_AHFOnReq 1;
BA_ "EventCommandSignal" SG_ 757 ITS_PTCOnReq 0;
BA_ "GatewayedSignals" SG_ 757 ITS_PTCOnReq 0;
BA_ "GenSigSendType" SG_ 757 ITS_PTCOnReq 1;
BA_ "GenSigStartValue" SG_ 757 ITS_PTCOnReq 3;
BA_ "EventCommandSignal" SG_ 757 ITS_PTCSt 0;
BA_ "GatewayedSignals" SG_ 757 ITS_PTCSt 0;
BA_ "GenSigSendType" SG_ 757 ITS_PTCSt 1;
BA_ "GenSigTimeoutValue" SG_ 757 ITS_PTCSt 1;
BA_ "EventCommandSignal" SG_ 757 ITS_1_E_MsgCounter 0;
BA_ "GatewayedSignals" SG_ 757 ITS_1_E_MsgCounter 0;
BA_ "GenSigSendType" SG_ 757 ITS_1_E_MsgCounter 1;
BA_ "EventCommandSignal" SG_ 757 ITS_1_E_Checksum 0;
BA_ "GatewayedSignals" SG_ 757 ITS_1_E_Checksum 0;
BA_ "GenSigSendType" SG_ 757 ITS_1_E_Checksum 1;
BA_ "GenSigStartValue" SG_ 757 ITS_1_E_Checksum 85;
BA_ "EventCommandSignal" SG_ 831 ITS_ECPPwrConsump 0;
BA_ "GatewayedSignals" SG_ 831 ITS_ECPPwrConsump 0;
BA_ "GenSigInvalidValue" SG_ 831 ITS_ECPPwrConsump 2047;
BA_ "GenSigSendType" SG_ 831 ITS_ECPPwrConsump 1;
BA_ "EventCommandSignal" SG_ 834 ITS_MotorInletTemp 0;
BA_ "GatewayedSignals" SG_ 834 ITS_MotorInletTemp 0;
BA_ "GenSigSendType" SG_ 834 ITS_MotorInletTemp 1;
BA_ "EventCommandSignal" SG_ 834 ITS_MotorInletTempErr 0;
BA_ "GatewayedSignals" SG_ 834 ITS_MotorInletTempErr 1;
BA_ "GenSigSendType" SG_ 834 ITS_MotorInletTempErr 1;
BA_ "EventCommandSignal" SG_ 834 ITS_3_E_MsgCounter 0;
BA_ "GatewayedSignals" SG_ 834 ITS_3_E_MsgCounter 1;
BA_ "GenSigSendType" SG_ 834 ITS_3_E_MsgCounter 1;
BA_ "EventCommandSignal" SG_ 834 ITS_3_E_Checksum 0;
BA_ "GatewayedSignals" SG_ 834 ITS_3_E_Checksum 1;
BA_ "GenSigStartValue" SG_ 834 ITS_3_E_Checksum 85;
BA_ "GenSigSendType" SG_ 834 ITS_3_E_Checksum 1;
BA_ "EventCommandSignal" SG_ 842 ITS_BattOutletTsnsrErrCode 0;
BA_ "GatewayedSignals" SG_ 842 ITS_BattOutletTsnsrErrCode 0;
BA_ "GenSigSendType" SG_ 842 ITS_BattOutletTsnsrErrCode 1;
BA_ "EventCommandSignal" SG_ 842 ITS_ChlrExvErrCode 0;
BA_ "GatewayedSignals" SG_ 842 ITS_ChlrExvErrCode 0;
BA_ "GenSigSendType" SG_ 842 ITS_ChlrExvErrCode 1;
BA_ "EventCommandSignal" SG_ 842 ITS_RawExterTempVD 0;
BA_ "GatewayedSignals" SG_ 842 ITS_RawExterTempVD 0;
BA_ "GenSigSendType" SG_ 842 ITS_RawExterTempVD 1;
BA_ "EventCommandSignal" SG_ 842 ITS_PTCTargetDuty 0;
BA_ "GatewayedSignals" SG_ 842 ITS_PTCTargetDuty 0;
BA_ "GenSigSendType" SG_ 842 ITS_PTCTargetDuty 1;
BA_ "EventCommandSignal" SG_ 842 ITS_RawExterTemp 0;
BA_ "GatewayedSignals" SG_ 842 ITS_RawExterTemp 0;
BA_ "GenSigSendType" SG_ 842 ITS_RawExterTemp 1;
BA_ "GenSigStartValue" SG_ 842 ITS_RawExterTemp 120;
BA_ "GenSigTimeoutValue" SG_ 842 ITS_RawExterTemp 120;
BA_ "EventCommandSignal" SG_ 926 TEL_Time_Year 0;
BA_ "GatewayedSignals" SG_ 926 TEL_Time_Year 0;
BA_ "GenSigSendType" SG_ 926 TEL_Time_Year 1;
BA_ "GenSigStartValue" SG_ 926 TEL_Time_Year 15;
BA_ "EventCommandSignal" SG_ 926 TEL_Time_Month 0;
BA_ "GatewayedSignals" SG_ 926 TEL_Time_Month 0;
BA_ "GenSigSendType" SG_ 926 TEL_Time_Month 1;
BA_ "GenSigStartValue" SG_ 926 TEL_Time_Month 1;
BA_ "EventCommandSignal" SG_ 926 TEL_Time_Hour 0;
BA_ "GatewayedSignals" SG_ 926 TEL_Time_Hour 0;
BA_ "GenSigSendType" SG_ 926 TEL_Time_Hour 1;
BA_ "GenSigStartValue" SG_ 926 TEL_Time_Hour 1;
BA_ "EventCommandSignal" SG_ 926 TEL_Time_Day 0;
BA_ "GatewayedSignals" SG_ 926 TEL_Time_Day 0;
BA_ "GenSigSendType" SG_ 926 TEL_Time_Day 1;
BA_ "GenSigStartValue" SG_ 926 TEL_Time_Day 1;
BA_ "EventCommandSignal" SG_ 926 TEL_Time_Min 0;
BA_ "GatewayedSignals" SG_ 926 TEL_Time_Min 0;
BA_ "GenSigSendType" SG_ 926 TEL_Time_Min 1;
BA_ "GenSigStartValue" SG_ 926 TEL_Time_Min 1;
BA_ "EventCommandSignal" SG_ 926 TEL_TimeVD 0;
BA_ "GatewayedSignals" SG_ 926 TEL_TimeVD 0;
BA_ "GenSigSendType" SG_ 926 TEL_TimeVD 1;
BA_ "EventCommandSignal" SG_ 926 TEL_BookChrgSt 0;
BA_ "GatewayedSignals" SG_ 926 TEL_BookChrgSt 0;
BA_ "GenSigSendType" SG_ 926 TEL_BookChrgSt 1;
BA_ "EventCommandSignal" SG_ 926 TEL_Time_Sec 0;
BA_ "GatewayedSignals" SG_ 926 TEL_Time_Sec 0;
BA_ "GenSigSendType" SG_ 926 TEL_Time_Sec 1;
BA_ "GenSigStartValue" SG_ 926 TEL_Time_Sec 1;
BA_ "EventCommandSignal" SG_ 2015 Func_Diag_Rx 1;
BA_ "GatewayedSignals" SG_ 2015 Func_Diag_Rx 0;
BA_ "GenSigSendType" SG_ 2015 Func_Diag_Rx 0;
BA_ "EventCommandSignal" SG_ 1790 NIDU_Diag_Response 1;
BA_ "GatewayedSignals" SG_ 1790 NIDU_Diag_Response 0;
BA_ "GenSigSendType" SG_ 1790 NIDU_Diag_Response 0;
BA_ "EventCommandSignal" SG_ 537 BCS_VDCActiveSt 0;
BA_ "GatewayedSignals" SG_ 537 BCS_VDCActiveSt 0;
BA_ "GenSigSendType" SG_ 537 BCS_VDCActiveSt 1;
BA_ "EventCommandSignal" SG_ 537 BCS_TCSActiveSt 0;
BA_ "GatewayedSignals" SG_ 537 BCS_TCSActiveSt 0;
BA_ "GenSigSendType" SG_ 537 BCS_TCSActiveSt 1;
BA_ "EventCommandSignal" SG_ 537 BCS_ABSActiveSt 0;
BA_ "GatewayedSignals" SG_ 537 BCS_ABSActiveSt 0;
BA_ "GenSigSendType" SG_ 537 BCS_ABSActiveSt 1;
BA_ "EventCommandSignal" SG_ 537 BCS_FLWheelSpd 0;
BA_ "GatewayedSignals" SG_ 537 BCS_FLWheelSpd 0;
BA_ "GenSigSendType" SG_ 537 BCS_FLWheelSpd 1;
BA_ "EventCommandSignal" SG_ 537 BCS_FRWheelSpd 0;
BA_ "GatewayedSignals" SG_ 537 BCS_FRWheelSpd 0;
BA_ "GenSigSendType" SG_ 537 BCS_FRWheelSpd 1;
BA_ "EventCommandSignal" SG_ 537 BCS_MasterCylinderPr 0;
BA_ "GatewayedSignals" SG_ 537 BCS_MasterCylinderPr 0;
BA_ "GenSigSendType" SG_ 537 BCS_MasterCylinderPr 1;
BA_ "EventCommandSignal" SG_ 537 BCS_EngTorqDecActiveSt 0;
BA_ "GatewayedSignals" SG_ 537 BCS_EngTorqDecActiveSt 0;
BA_ "GenSigSendType" SG_ 537 BCS_EngTorqDecActiveSt 1;
BA_ "EventCommandSignal" SG_ 537 BCS_RegenModuleActive 0;
BA_ "GatewayedSignals" SG_ 537 BCS_RegenModuleActive 0;
BA_ "GenSigSendType" SG_ 537 BCS_RegenModuleActive 1;
BA_ "EventCommandSignal" SG_ 537 EPS_SteeringAngle 0;
BA_ "GatewayedSignals" SG_ 537 EPS_SteeringAngle 0;
BA_ "GenSigInvalidValue" SG_ 537 EPS_SteeringAngle 65535;
BA_ "GenSigSendType" SG_ 537 EPS_SteeringAngle 1;
BA_ "GenSigStartValue" SG_ 537 EPS_SteeringAngle 7800;
BA_ "GenSigTimeoutValue" SG_ 537 EPS_SteeringAngle 65535;
BA_ "EventCommandSignal" SG_ 806 ACU_ACChgCurCfg 0;
BA_ "GatewayedSignals" SG_ 806 ACU_ACChgCurCfg 0;
BA_ "GenSigSendType" SG_ 806 ACU_ACChgCurCfg 1;
BA_ "EventCommandSignal" SG_ 885 BCM_KeySt 0;
BA_ "GatewayedSignals" SG_ 885 BCM_KeySt 0;
BA_ "GenSigSendType" SG_ 885 BCM_KeySt 1;
BA_ "EventCommandSignal" SG_ 1507 VCU_NMNodeAddress 0;
BA_ "GatewayedSignals" SG_ 1507 VCU_NMNodeAddress 0;
BA_ "GenSigSendType" SG_ 1507 VCU_NMNodeAddress 1;
BA_ "GenSigStartValue" SG_ 1507 VCU_NMNodeAddress 227;
BA_ "EventCommandSignal" SG_ 1507 VCU_NMDataField1 0;
BA_ "GatewayedSignals" SG_ 1507 VCU_NMDataField1 0;
BA_ "GenSigSendType" SG_ 1507 VCU_NMDataField1 1;
BA_ "EventCommandSignal" SG_ 1507 VCU_NMWakeupOrigin_ECAN 0;
BA_ "GatewayedSignals" SG_ 1507 VCU_NMWakeupOrigin_ECAN 0;
BA_ "GenSigSendType" SG_ 1507 VCU_NMWakeupOrigin_ECAN 1;
BA_ "EventCommandSignal" SG_ 1507 VCU_SubNetWakeRq 0;
BA_ "GatewayedSignals" SG_ 1507 VCU_SubNetWakeRq 0;
BA_ "GenSigSendType" SG_ 1507 VCU_SubNetWakeRq 1;
BA_ "EventCommandSignal" SG_ 1507 VCU_NMKeepingOrigin 0;
BA_ "GatewayedSignals" SG_ 1507 VCU_NMKeepingOrigin 0;
BA_ "GenSigSendType" SG_ 1507 VCU_NMKeepingOrigin 1;
BA_ "EventCommandSignal" SG_ 1507 VCU_NMDataField2 0;
BA_ "GatewayedSignals" SG_ 1507 VCU_NMDataField2 0;
BA_ "GenSigSendType" SG_ 1507 VCU_NMDataField2 1;
BA_ "EventCommandSignal" SG_ 1506 BMS_NodeAddress 0;
BA_ "GatewayedSignals" SG_ 1506 BMS_NodeAddress 0;
BA_ "GenSigSendType" SG_ 1506 BMS_NodeAddress 1;
BA_ "GenSigStartValue" SG_ 1506 BMS_NodeAddress 226;
BA_ "EventCommandSignal" SG_ 1506 BMS_NMDataField1 0;
BA_ "GatewayedSignals" SG_ 1506 BMS_NMDataField1 0;
BA_ "GenSigSendType" SG_ 1506 BMS_NMDataField1 1;
BA_ "EventCommandSignal" SG_ 1506 BMS_NMWakeupOrigin 0;
BA_ "GatewayedSignals" SG_ 1506 BMS_NMWakeupOrigin 0;
BA_ "GenSigSendType" SG_ 1506 BMS_NMWakeupOrigin 1;
BA_ "EventCommandSignal" SG_ 1506 BMS_SubNetWakeRq 0;
BA_ "GatewayedSignals" SG_ 1506 BMS_SubNetWakeRq 0;
BA_ "GenSigSendType" SG_ 1506 BMS_SubNetWakeRq 1;
BA_ "EventCommandSignal" SG_ 1506 BMS_NMKeepingOrigin 0;
BA_ "GatewayedSignals" SG_ 1506 BMS_NMKeepingOrigin 0;
BA_ "GenSigSendType" SG_ 1506 BMS_NMKeepingOrigin 1;
BA_ "EventCommandSignal" SG_ 1506 BMS_NMDataField2 0;
BA_ "GatewayedSignals" SG_ 1506 BMS_NMDataField2 0;
BA_ "GenSigSendType" SG_ 1506 BMS_NMDataField2 1;
BA_ "EventCommandSignal" SG_ 1510 IPS_NMNodeAddress 0;
BA_ "GatewayedSignals" SG_ 1510 IPS_NMNodeAddress 0;
BA_ "GenSigSendType" SG_ 1510 IPS_NMNodeAddress 1;
BA_ "GenSigStartValue" SG_ 1510 IPS_NMNodeAddress 230;
BA_ "EventCommandSignal" SG_ 1510 IPS_NMDataField1 0;
BA_ "GatewayedSignals" SG_ 1510 IPS_NMDataField1 0;
BA_ "GenSigSendType" SG_ 1510 IPS_NMDataField1 1;
BA_ "EventCommandSignal" SG_ 1510 IPS_NMWakeupOrigin 0;
BA_ "GatewayedSignals" SG_ 1510 IPS_NMWakeupOrigin 0;
BA_ "GenSigSendType" SG_ 1510 IPS_NMWakeupOrigin 1;
BA_ "EventCommandSignal" SG_ 1510 IPS_SubNetWakeRq 0;
BA_ "GatewayedSignals" SG_ 1510 IPS_SubNetWakeRq 0;
BA_ "GenSigSendType" SG_ 1510 IPS_SubNetWakeRq 1;
BA_ "EventCommandSignal" SG_ 1510 IPS_NMKeepingOrigin 0;
BA_ "GatewayedSignals" SG_ 1510 IPS_NMKeepingOrigin 0;
BA_ "GenSigSendType" SG_ 1510 IPS_NMKeepingOrigin 1;
BA_ "EventCommandSignal" SG_ 1510 IPS_NMDataField2 0;
BA_ "GatewayedSignals" SG_ 1510 IPS_NMDataField2 0;
BA_ "GenSigSendType" SG_ 1510 IPS_NMDataField2 1;
BA_ "EventCommandSignal" SG_ 1533 EVCC_NMNodeAddress 0;
BA_ "GatewayedSignals" SG_ 1533 EVCC_NMNodeAddress 0;
BA_ "GenSigSendType" SG_ 1533 EVCC_NMNodeAddress 1;
BA_ "GenSigStartValue" SG_ 1533 EVCC_NMNodeAddress 253;
BA_ "EventCommandSignal" SG_ 1533 EVCC_NMDataField1 0;
BA_ "GatewayedSignals" SG_ 1533 EVCC_NMDataField1 0;
BA_ "GenSigSendType" SG_ 1533 EVCC_NMDataField1 1;
BA_ "EventCommandSignal" SG_ 1533 EVCC_NMWakeupOrigin 0;
BA_ "GatewayedSignals" SG_ 1533 EVCC_NMWakeupOrigin 0;
BA_ "GenSigSendType" SG_ 1533 EVCC_NMWakeupOrigin 1;
BA_ "EventCommandSignal" SG_ 1533 EVCC_SubNetWakeRq 0;
BA_ "GatewayedSignals" SG_ 1533 EVCC_SubNetWakeRq 0;
BA_ "GenSigSendType" SG_ 1533 EVCC_SubNetWakeRq 1;
BA_ "EventCommandSignal" SG_ 1533 EVCC_NMKeepingOrigin 0;
BA_ "GatewayedSignals" SG_ 1533 EVCC_NMKeepingOrigin 0;
BA_ "GenSigSendType" SG_ 1533 EVCC_NMKeepingOrigin 1;
BA_ "EventCommandSignal" SG_ 1533 EVCC_NMDataField2 0;
BA_ "GatewayedSignals" SG_ 1533 EVCC_NMDataField2 0;
BA_ "GenSigSendType" SG_ 1533 EVCC_NMDataField2 1;
BA_ "EventCommandSignal" SG_ 1376 EOP_NMNodeAddress 0;
BA_ "GatewayedSignals" SG_ 1376 EOP_NMNodeAddress 0;
BA_ "GenSigSendType" SG_ 1376 EOP_NMNodeAddress 1;
BA_ "GenSigStartValue" SG_ 1376 EOP_NMNodeAddress 96;
BA_ "EventCommandSignal" SG_ 1376 EOP_NMDataField1 0;
BA_ "GatewayedSignals" SG_ 1376 EOP_NMDataField1 0;
BA_ "GenSigSendType" SG_ 1376 EOP_NMDataField1 1;
BA_ "EventCommandSignal" SG_ 1376 EOP_NMWakeupOrigin 0;
BA_ "GatewayedSignals" SG_ 1376 EOP_NMWakeupOrigin 0;
BA_ "GenSigSendType" SG_ 1376 EOP_NMWakeupOrigin 1;
BA_ "EventCommandSignal" SG_ 1376 EOP_SubNetWakeRq 0;
BA_ "GatewayedSignals" SG_ 1376 EOP_SubNetWakeRq 0;
BA_ "GenSigSendType" SG_ 1376 EOP_SubNetWakeRq 1;
BA_ "EventCommandSignal" SG_ 1376 EOP_NMKeepingOrigin 0;
BA_ "GatewayedSignals" SG_ 1376 EOP_NMKeepingOrigin 0;
BA_ "GenSigSendType" SG_ 1376 EOP_NMKeepingOrigin 1;
BA_ "EventCommandSignal" SG_ 1376 EOP_NMDataField2 0;
BA_ "GatewayedSignals" SG_ 1376 EOP_NMDataField2 0;
BA_ "GenSigSendType" SG_ 1376 EOP_NMDataField2 1;
BA_ "EventCommandSignal" SG_ 1406 NIDU_NMNodeAddress 0;
BA_ "GatewayedSignals" SG_ 1406 NIDU_NMNodeAddress 0;
BA_ "GenSigSendType" SG_ 1406 NIDU_NMNodeAddress 1;
BA_ "GenSigStartValue" SG_ 1406 NIDU_NMNodeAddress 126;
BA_ "EventCommandSignal" SG_ 1406 NIDU_NMDataField1 0;
BA_ "GatewayedSignals" SG_ 1406 NIDU_NMDataField1 0;
BA_ "GenSigSendType" SG_ 1406 NIDU_NMDataField1 1;
BA_ "EventCommandSignal" SG_ 1406 NIDU_NMWakeupOrigin 0;
BA_ "GatewayedSignals" SG_ 1406 NIDU_NMWakeupOrigin 0;
BA_ "GenSigSendType" SG_ 1406 NIDU_NMWakeupOrigin 1;
BA_ "EventCommandSignal" SG_ 1406 NIDU_SubNetWakeRq 0;
BA_ "GatewayedSignals" SG_ 1406 NIDU_SubNetWakeRq 0;
BA_ "GenSigSendType" SG_ 1406 NIDU_SubNetWakeRq 1;
BA_ "EventCommandSignal" SG_ 1406 NIDU_NMKeepingOrigin 0;
BA_ "GatewayedSignals" SG_ 1406 NIDU_NMKeepingOrigin 0;
BA_ "GenSigSendType" SG_ 1406 NIDU_NMKeepingOrigin 1;
BA_ "EventCommandSignal" SG_ 1406 NIDU_NMDataField2 0;
BA_ "GatewayedSignals" SG_ 1406 NIDU_NMDataField2 0;
BA_ "GenSigSendType" SG_ 1406 NIDU_NMDataField2 1;
BA_ "EventCommandSignal" SG_ 1508 DCU_NMNodeAddress 0;
BA_ "GatewayedSignals" SG_ 1508 DCU_NMNodeAddress 0;
BA_ "GenSigSendType" SG_ 1508 DCU_NMNodeAddress 1;
BA_ "GenSigStartValue" SG_ 1508 DCU_NMNodeAddress 228;
BA_ "EventCommandSignal" SG_ 1508 DCU_NMDataField1 0;
BA_ "GatewayedSignals" SG_ 1508 DCU_NMDataField1 0;
BA_ "GenSigSendType" SG_ 1508 DCU_NMDataField1 1;
BA_ "EventCommandSignal" SG_ 1508 DCU_NMWakeupOrigin 0;
BA_ "GatewayedSignals" SG_ 1508 DCU_NMWakeupOrigin 0;
BA_ "GenSigSendType" SG_ 1508 DCU_NMWakeupOrigin 1;
BA_ "EventCommandSignal" SG_ 1508 DCU_SubNetWakeRq 0;
BA_ "GatewayedSignals" SG_ 1508 DCU_SubNetWakeRq 0;
BA_ "GenSigSendType" SG_ 1508 DCU_SubNetWakeRq 1;
BA_ "EventCommandSignal" SG_ 1508 DCU_NMKeepingOrigin 0;
BA_ "GatewayedSignals" SG_ 1508 DCU_NMKeepingOrigin 0;
BA_ "GenSigSendType" SG_ 1508 DCU_NMKeepingOrigin 1;
BA_ "EventCommandSignal" SG_ 1508 DCU_NMDataField2 0;
BA_ "GatewayedSignals" SG_ 1508 DCU_NMDataField2 0;
BA_ "GenSigSendType" SG_ 1508 DCU_NMDataField2 1;
BA_ "EventCommandSignal" SG_ 1531 ITS_NMNodeAddress 0;
BA_ "GatewayedSignals" SG_ 1531 ITS_NMNodeAddress 0;
BA_ "GenSigSendType" SG_ 1531 ITS_NMNodeAddress 1;
BA_ "GenSigStartValue" SG_ 1531 ITS_NMNodeAddress 251;
BA_ "EventCommandSignal" SG_ 1531 ITS_NMDataField1 0;
BA_ "GatewayedSignals" SG_ 1531 ITS_NMDataField1 0;
BA_ "GenSigSendType" SG_ 1531 ITS_NMDataField1 1;
BA_ "EventCommandSignal" SG_ 1531 ITS_NMWakeupOrigin 0;
BA_ "GatewayedSignals" SG_ 1531 ITS_NMWakeupOrigin 0;
BA_ "GenSigSendType" SG_ 1531 ITS_NMWakeupOrigin 1;
BA_ "EventCommandSignal" SG_ 1531 ITS_SubNetWakeRq 0;
BA_ "GatewayedSignals" SG_ 1531 ITS_SubNetWakeRq 0;
BA_ "GenSigSendType" SG_ 1531 ITS_SubNetWakeRq 1;
BA_ "EventCommandSignal" SG_ 1531 ITS_NMKeepingOrigin 0;
BA_ "GatewayedSignals" SG_ 1531 ITS_NMKeepingOrigin 0;
BA_ "GenSigSendType" SG_ 1531 ITS_NMKeepingOrigin 1;
BA_ "EventCommandSignal" SG_ 1531 ITS_NMDataField2 0;
BA_ "GatewayedSignals" SG_ 1531 ITS_NMDataField2 0;
BA_ "GenSigSendType" SG_ 1531 ITS_NMDataField2 1;
BA_ "EventCommandSignal" SG_ 1509 GCU_NodeAddress 0;
BA_ "GatewayedSignals" SG_ 1509 GCU_NodeAddress 0;
BA_ "GenSigSendType" SG_ 1509 GCU_NodeAddress 1;
BA_ "GenSigStartValue" SG_ 1509 GCU_NodeAddress 229;
BA_ "EventCommandSignal" SG_ 1509 GCU_NMDataField1 0;
BA_ "GatewayedSignals" SG_ 1509 GCU_NMDataField1 0;
BA_ "GenSigSendType" SG_ 1509 GCU_NMDataField1 1;
BA_ "EventCommandSignal" SG_ 1509 GCU_NMWakeupOrignin 0;
BA_ "GatewayedSignals" SG_ 1509 GCU_NMWakeupOrignin 0;
BA_ "GenSigSendType" SG_ 1509 GCU_NMWakeupOrignin 1;
BA_ "EventCommandSignal" SG_ 1509 GCU_SubNetWakeRq 0;
BA_ "GatewayedSignals" SG_ 1509 GCU_SubNetWakeRq 0;
BA_ "GenSigSendType" SG_ 1509 GCU_SubNetWakeRq 1;
BA_ "EventCommandSignal" SG_ 1509 GCU_NMKeepingOrigin 0;
BA_ "GatewayedSignals" SG_ 1509 GCU_NMKeepingOrigin 0;
BA_ "GenSigSendType" SG_ 1509 GCU_NMKeepingOrigin 1;
BA_ "EventCommandSignal" SG_ 1509 GCU_NMDataField2 0;
BA_ "GatewayedSignals" SG_ 1509 GCU_NMDataField2 0;
BA_ "GenSigSendType" SG_ 1509 GCU_NMDataField2 1;
BA_ "EventCommandSignal" SG_ 1359 GWM_NMNodeAddress 0;
BA_ "GatewayedSignals" SG_ 1359 GWM_NMNodeAddress 0;
BA_ "GenSigSendType" SG_ 1359 GWM_NMNodeAddress 1;
BA_ "GenSigStartValue" SG_ 1359 GWM_NMNodeAddress 79;
BA_ "EventCommandSignal" SG_ 1359 GWM_NMDataField1 0;
BA_ "GatewayedSignals" SG_ 1359 GWM_NMDataField1 0;
BA_ "GenSigSendType" SG_ 1359 GWM_NMDataField1 1;
BA_ "EventCommandSignal" SG_ 1359 GWM_NMWakeupOrigin_ECAN 0;
BA_ "GatewayedSignals" SG_ 1359 GWM_NMWakeupOrigin_ECAN 0;
BA_ "GenSigSendType" SG_ 1359 GWM_NMWakeupOrigin_ECAN 1;
BA_ "EventCommandSignal" SG_ 1359 GWM_SubNetWakeRq 0;
BA_ "GatewayedSignals" SG_ 1359 GWM_SubNetWakeRq 0;
BA_ "GenSigSendType" SG_ 1359 GWM_SubNetWakeRq 1;
BA_ "EventCommandSignal" SG_ 1359 GWM_NMKeepingOrigin 0;
BA_ "GatewayedSignals" SG_ 1359 GWM_NMKeepingOrigin 0;
BA_ "GenSigSendType" SG_ 1359 GWM_NMKeepingOrigin 1;
BA_ "EventCommandSignal" SG_ 1359 GWM_NMKeepingOrigin2 0;
BA_ "GatewayedSignals" SG_ 1359 GWM_NMKeepingOrigin2 0;
BA_ "GenSigSendType" SG_ 1359 GWM_NMKeepingOrigin2 1;
BA_ "EventCommandSignal" SG_ 1359 GWM_NMDataField2 0;
BA_ "GatewayedSignals" SG_ 1359 GWM_NMDataField2 0;
BA_ "GenSigSendType" SG_ 1359 GWM_NMDataField2 1;
BA_ "EventCommandSignal" SG_ 1662 NIDU_Diag_Request 1;
BA_ "GatewayedSignals" SG_ 1662 NIDU_Diag_Request 0;
BA_ "GenSigSendType" SG_ 1662 NIDU_Diag_Request 0;
VAL_ 864 VCU_AHFShutImme 0 "No request" 1 "immediate shutdown" ;
VAL_ 864 VCU_AHFDelayEn 0 "Disable delay" 1 "Enable delay" ;
VAL_ 864 VCU_AHFActivationSt 0 "AHF inactive" 1 "AHF active" 2 "Reserved" 3 "Reserved" 4 "Reserved" 5 "Reserved" 6 "Reserved" 7 "Reserved" ;
VAL_ 864 VCU_PlgConnSt 0 "Not connected" 1 "Plug connector connected" ;
VAL_ 438 VCU_CrntGearLvl_E 0 "Invalid" 1 "'D' Drive gear" 2 "'N' Neutral gear" 3 "'R' Reverse gear" 4 "'P' Park gear" 5 "Not used" 6 "Not used" 7 "Not used" ;
VAL_ 438 VCU_DCU_SurgeDamperStReq 0 "DstC_off" 1 "DstC_ext" 2 "DstC_int_ext" 3 "Reserved" ;
VAL_ 438 VCU_DCU_VehPwrAbnormal 0 "OK" 1 "NOK" ;
VAL_ 438 VCU_DCU_ModeReq 0 "Reserved" 1 "Init" 2 "Standby" 3 "Ready" 4 "TrqCtrl" 5 "SpdCtrl" 6 "Discharge" 7 "AHFCtrl" 8 "Reserved" 9 "Offsetcal" 10 "Power off" 11 "Reserved" 12 "Reserved" 13 "Reserved" 14 "Reserved" 15 "Reserved" ;
VAL_ 680 VCU_IPS_DCDCModeReq 0 "no request, sleep indication allowed" 1 "Standby requested - No power conversion" 2 "Buck Mode request" 3 "Reserved" 4 "Service_General" 5 "Reserved" 6 "Reserved" 7 "Reserved" ;
VAL_ 673 VCU_HvilSt 0 "HVIL generator is ready but HVIL result is not available" 1 "HVIL is closed" 2 "HVIL is interrupted" 3 "Failure" ;
VAL_ 673 VCU_BMS_SepaHeatEn 0 "Disable" 1 "Enable" ;
VAL_ 673 VCU_IPS_OBCModeReq 0 "no request" 1 "Standby" 2 "Charging" 3 "Discharging" 4 "Heating/V2C" 5 "V2L&V2C" 6 "Reserved" 7 "Reserved" ;
VAL_ 779 VCU_SwapHvBattModeSt 0 "Invalid" 1 "Not Swap mode" 2 "Swap mode" 3 "Swap mode (Hv power down)" ;
VAL_ 779 VCU_SwapHvBattModeStVD 0 "Not valid" 1 "Valid" ;
VAL_ 678 BMS_DcChargerSt 0 "DC unplugged" 1 "DC plugged & DC wake-up inactive" 2 "DC plugged & DC wake-up active" 3 "Reserved" ;
VAL_ 678 BMS_DCUBattSt 0 "HVBattCntctr_Open" 1 "HVBattCntctr_Closed" ;
VAL_ 678 BMS_PwrDwnReq 0 "NotRequest" 1 "Request" ;
VAL_ 444 BMS_SepaHeatSt 0 "Not work" 1 "separate heat state" 2 "separating" 3 "reserve" ;
VAL_ 889 IPS_DCDCModeSt 0 "Init" 1 "Disconnected" 2 "Connected (HV is active)" 3 "Active - Buck Mode" 4 "Reserved" 5 "Reserved" 6 "Reserved" 7 "Failure" ;
VAL_ 889 IPS_HVDCHVilSt 0 "HVIL generator is ready but HVIL result is not available" 1 "HVIL is closed" 2 "HVIL is interrupted" 3 "Failure" ;
VAL_ 889 IPS_KL15State 0 "off" 1 "on" ;
VAL_ 897 IPS_DcdcHwSt 1 "DCDC" 0 "IPS" ;
VAL_ 897 IPS_DCDCFaultLampInd 0 "Lamp off" 1 "Lamp on" ;
VAL_ 897 DCDC_RemoteDiagCode 0 "NO Fault" 1 "A DTC" 2 "B DTC" 3 "C DTC" ;
VAL_ 897 IPS_DCDCFaultLampIndOperFlag 0 "No prompt" 1 "Prompt" ;
VAL_ 897 IPS_DCDCFaultLampIndFlag 0 "No prompt" 1 "Prompt" ;
VAL_ 924 IPS_DchgOverload 0 "not overload" 1 "overload" ;
VAL_ 924 IPS_OBCCC_St 7 "failure" 6 "charger connected(European standard charging)" 5 "Connected DC charing(European standard charging)" 4 "Connected V2L" 3 "Reserved" 2 "Connected charging/ V2V" 1 "half connected charging/ V2V/ V2L" 0 "disconnected" ;
VAL_ 924 IPS_OBCDschDisable 0 "CP state is not oK" 1 "CP Duty&Frequency&Volt is OK" ;
VAL_ 924 IPS_OBCModeSt 0 "Init" 1 "Disconnected" 2 "Connected (HV is active)" 3 "Active - Charging" 4 "Active - V2L discharging" 5 "Active -  V2V discharging" 6 "Heating/Discharge Overload" 7 "Failure" ;
VAL_ 924 IPS_ACHvilSt 0 "HVIL generator is ready but HVIL result is not available" 1 "HVIL is closed" 2 "HVIL is interrupted" 3 "Failure" ;
VAL_ 924 IPS_OBCCC_Cap 0 "Not valid" 1 "10A" 2 "16A" 3 "32A" 4 "64A" 5 "Reserved" 6 "Reserved" 7 "Reserved" ;
VAL_ 924 IPS_OBCCpS2St 0 "S2 is off" 1 "S2 is on" ;
VAL_ 924 IPS_OBCCpFreqSt 0 "The frequency is beyond 900Hz to 1100Hz" 1 "The frequency is between 900Hz to 1100Hz" ;
VAL_ 924 IPS_OBCCPSt 0 "CP state is not oK" 1 "CP Duty&Frequency&Volt is OK" ;
VAL_ 924 IPS_OBCStStep 0 "Step1" 1 "Step2" 2 "Step3" 3 "Step4" ;
VAL_ 746 IPS_ChgCurRespAvail 0 "Not available;" 1 "Available;" ;
VAL_ 746 IPS_ChgCurResp 0 "Default；" 1 "4A；" 2 "8A；" 3 "12A；" 4 "16A；" 5 "20A；" 6 "24A；" 7 "28A；" 8 "32A；" ;
VAL_ 884 IPS_OBCEngMilLampReq 1 "Request;" 0 "No request;" ;
VAL_ 884 IPS_OBCFaultLampInd 0 "Lamp off" 1 "Lamp on" ;
VAL_ 884 IPS_OBCFaultLampIndOperFlag 0 "No prompt" 1 "Prompt" ;
VAL_ 884 IPS_OBCEnergyDirCap 0 "Unidirectional" 1 "Bidirectional" ;
VAL_ 884 IPS_RemoteDiagCode 0 "NO Fault" 1 "A DTC" 2 "B DTC" 3 "C DTC" ;
VAL_ 980 IPS_TEL_DCDCFaultLampInd 0 "Lamp off" 1 "Lamp on" ;
VAL_ 980 IPS_TEL_DCDCTempOvrErr 0 "OK" 1 "Error" ;
VAL_ 980 IPS_TEL_DCDCModeSt 0 "Init" 1 "Buck" 2 "OFF" 3 "Reserved" ;
VAL_ 1011 IPS_OBCDiagErrCode 0 "(0) No error" 62 "(62)OBC (IPS) is derating" 63 "(63)OBC(IPS) is not able to work" ;
VAL_ 1011 IPS_DCDCDiagErrCode 0 "(0) No error" 86 "(86)DCDC (IPS) is derating" 87 "(87)DCDC (IPS) is not able to work" ;
VAL_ 531 EVCC_S2_Drive 0 "Undriven" 1 "Driven" ;
VAL_ 531 EVCC_OBC_CpFreqSt 0 "The frequency is beyond 900Hz to 1100Hz" 1 "The frequency is between 900Hz to 1100Hz" ;
VAL_ 531 EVCC_CCOUT_Drive 0 "Undriven" 1 "Driven" ;
VAL_ 531 EVCC_lostECAN 0 "ECAN no lost" 1 "ECAN lost" ;
VAL_ 531 EVCC_EVSERSNToNORMSCHG 0 "No Failure" 1 "BST" 2 "OBC S2" 3 "CP Duty 100%" ;
VAL_ 745 PTC_DownShiftSt 0 "NO off& downshift" 1 "off or downshift" ;
VAL_ 745 PTC_UpShiftSt 0 "NO on& upshift" 1 "on or upshift" ;
VAL_ 745 PTC_ModeSt 1 "initial" 2 "standby" 4 "working" 8 "failure" ;
VAL_ 369 DCU_ModeSt 0 "Reserved" 1 "Init" 2 "Standby" 3 "Ready" 4 "TrqCtrl" 5 "SpdCtrl" 6 "Discharge" 7 "AHFCtrl" 8 "Failure" 9 "Offsetcal" 10 "Power off" 11 "Reserved" 12 "Reserved" 13 "Reserved" 14 "Reserved" 15 "Reserved" 16 "Reserved" ;
VAL_ 377 DCU_bBigDataFlag 0 "No request" 1 "Request" ;
VAL_ 377 DCU_Err2NoticeFlag 1 "Prompt" 0 "No prompt" ;
VAL_ 377 DCU_ErrNotice 0 "reseved" 1 "PwrLimitlevel1" 2 "PwrLimitlevel2" 3 "Pwrloss" 4 "reseved" 5 "reseved" 6 "reseved" 7 "reseved" ;
VAL_ 377 DCU_ErrNoticeOperFlag 1 "Prompt" 0 "No prompt" ;
VAL_ 377 DCU_RemoteDiagCode 0 "NO Fault" 1 "A DTC" 2 "B DTC" 3 "C DTC" ;
VAL_ 377 DCU_TypeSt 0 "Not valid" 1 "Type1" 2 "Type2" 3 "Type3" 4 "Type4" 5 "Type5" 6 "Reserved" 7 "Reserved" 8 "Reserved" 9 "Reserved" 10 "Reserved" 11 "Reserved" 12 "Reserved" 13 "Reserved" 14 "Reserved" 15 "Reserved" ;
VAL_ 377 DCU_bDiagReq 0 "No Active" 1 "Active" ;
VAL_ 377 DCU_bReadyHV 0 "No Active" 1 "Active" ;
VAL_ 377 DCU_OffsetCalInd 0 "Default / nok" 1 "Calibration succeeded" ;
VAL_ 385 DCU_HvilSt 0 "HVIL generator is ready but HVIL result is not available" 1 "HVIL is closed" 2 "HVIL is interrupted" 3 "Failure" ;
VAL_ 385 DCU_SpdLmtActiveSt 0 "No active" 1 "Active" ;
VAL_ 385 DCU_DstActive 0 "No Active" 1 "Active" ;
VAL_ 385 DCU_GateDrvSt 0 "FreeWheel" 1 "PWMrun" 2 "Discharge" 3 "ShortCircuit" ;
VAL_ 882 DCU_SysTempOvrInd 0 "Lamp off" 1 "Lamp on" ;
VAL_ 882 DCU_FaultLampInd 0 "Lamp off" 1 "Lamp on" ;
VAL_ 910 DCU_TEL_ECUTempOvrErr 1 "Error;" 0 "No error;" ;
VAL_ 910 DCU_TEL_MotTempOvrErr 1 "Error;" 0 "No error;" ;
VAL_ 910 DCU_TEL_ModeSt 4 "Standby;" 3 "Stop;" 2 "Generate electricity;" 1 "Electricity consumed;" 0 "Reserved;" 5 "Reserved;" 6 "Reserved;" 7 "Reserved;" ;
VAL_ 376 DCU_ADC_MCUBlkst 0 "no block" 1 "block" 2 "reserved" ;
VAL_ 376 DCU_ADC_SpdSvModAvl 0 "not available" 1 "available" ;
VAL_ 376 DCU_ADC_MCUStandstill 0 "not standstill" 1 "standstill" ;
VAL_ 376 DCU_ADC_MCUSpdSVModFit 0 "no fault" 1 "excessive output torque fault" ;
VAL_ 376 DCU_ADC_MCUVehSldSt 0 "not slide" 1 "slide" ;
VAL_ 376 DCU_ADC_ModeSt 0 "Reserved" 1 "Init" 2 "Standby" 3 "Ready" 4 "TrqCtrl" 5 "SpdCtrl" 6 "Discharge" 7 "AHFCtrl" 8 "Failure" 9 "Offsetcal" 10 "Power off" 11 "Reserved" 12 "Reserved" 13 "Reserved" 14 "Reserved" 15 "Reserved" 16 "Reserved" ;
VAL_ 555 DCU_EOP_SpdSet 4095 "Error" 0 "Init" ;
VAL_ 556 EOP_ErrLevel 7 "reserved" 6 "reserved" 5 "reserved" 4 "Error unable to work" 3 "communication fail EOP is able to work following the strategy of itself" 2 "Error but still can work limit the EOP power as 50% or less (TBD)" 1 "Error but still can work" 0 "Normal" ;
VAL_ 757 ITS_MotorLoopEstimatedFlowVD 0 "Invaild" 1 "Valid" 2 "Reserved" 3 "Reserved" ;
VAL_ 757 ITS_AHFSt 0 "NO off& downshift" 1 "off or downshift" ;
VAL_ 757 ITS_AHFOnReq 0 "Reserve" 1 "AHF off" 2 "AHF on" 3 "Reserve" ;
VAL_ 757 ITS_PTCOnReq 0 "Reserve" 1 "PTC off" 2 "PTC on" 3 "Reserve" ;
VAL_ 757 ITS_PTCSt 0 "No OFF & downshift" 1 "OFF or downshift" ;
VAL_ 831 ITS_ECPPwrConsump 2047 "Signal not available" ;
VAL_ 834 ITS_MotorInletTemp 3050 "Invalid Value" ;
VAL_ 834 ITS_MotorInletTempErr 0 "No error" 1 "Error" ;
VAL_ 842 ITS_RawExterTempVD 0 "Not valid" 1 "Valid" ;
VAL_ 926 TEL_TimeVD 0 "Not valid" 1 "Valid" ;
VAL_ 926 TEL_BookChrgSt 0 "Not booking" 1 "Not started in cycle mode" 2 "In the time of cycle mode" 3 "Not started in signal mode" 4 "In the time of signal mode" 5 "End in single mode" 6 "Reserved" 7 "Reserved" ;
VAL_ 537 BCS_VDCActiveSt 0 "Not active" 1 "Active" ;
VAL_ 537 BCS_TCSActiveSt 0 "Not active" 1 "Active" ;
VAL_ 537 BCS_ABSActiveSt 0 "Not active" 1 "Active" ;
VAL_ 537 BCS_EngTorqDecActiveSt 0 "Not active" 1 "Active" ;
VAL_ 537 BCS_RegenModuleActive 0 "Not Active" 1 "Active" ;
VAL_ 806 ACU_ACChgCurCfg 0 "No command；" 1 "4A；" 2 "8A；" 3 "12A；" 4 "16A；" 5 "20A；" 6 "24A；" 7 "28A；" 8 "32A；" ;
VAL_ 885 BCM_KeySt 0 "Off" 1 "Acc" 2 "On" 3 "Crank" ;
VAL_ 1507 VCU_NMWakeupOrigin_ECAN 0 "Reserved" 1 "Message wakeup" 2 "Not used" 3 "LIN slaver wake up" 17 "IGN ACC" 18 "IGN ON" 19 "Message wake up ACAN" 20 "Message wake up PCAN" 21 "Message wake up ECAN" ;
VAL_ 1507 VCU_SubNetWakeRq 0 "No request" 1 "Wake up" 0 "No request" 1 "Wake up" 0 "No request" 1 "Wake up" 0 "No request" 1 "Wake up" 0 "No request" 1 "Wake up" 0 "No request" 1 "Wake up" 0 "No request" 1 "Wake up" ;
VAL_ 1507 VCU_NMKeepingOrigin 0 "No request" 1 "Request" ;
VAL_ 1506 BMS_NMWakeupOrigin 0 "Reserved" 1 "NW Message wakeup" 2 "Not used" 3 "Not used" 4 "Not used" 5 "Not used" 6 "Not used" 7 "Not used" 8 "Not used" 9 "Not used" 10 "Not used" 11 "Not used" 12 "Not used" 13 "Not used" 14 "Not used" 15 "Not used" 16 "Not used" 17 "Not used" 18 "IGN ON" 19 "Not used" 20 "Not used" 21 "Not used" 22 "Not used" 23 "Not used" 24 "Not used" 25 "Not used" 26 "Not used" 27 "Not used" 28 "Not used" 29 "Not used" 30 "Not used" 31 "Not used" 32 "Not used" 33 "Not used" 34 "Not used" 35 "Not used" 36 "Not used" 37 "Not used" 38 "Not used" 39 "Not used" 40 "Not used" 41 "Not used" 42 "Not used" 43 "Not used" 44 "Not used" 45 "Not used" 46 "Not used" 47 "Not used" 48 "Not used" 49 "Not used" 50 "Not used" 51 "Not used" 52 "Not used" 53 "Not used" 54 "Not used" 55 "Not used" 56 "Not used" 57 "Not used" 58 "Not used" 59 "Not used" 60 "Not used" 61 "Not used" 62 "Not used" 63 "Not used" 64 "Not used" 65 "Not used" 66 "Not used" 67 "Not used" 68 "Not used" 69 "Not used" 70 "Not used" 71 "Not used" 72 "Not used" 73 "Not used" 74 "Not used" 75 "Not used" 76 "Not used" 77 "Not used" 78 "Not used" 79 "Not used" 80 "Not used" 81 "Not used" 82 "Not used" 83 "Not used" 84 "Not used" 85 "Not used" 86 "Not used" 87 "Not used" 88 "Not used" 89 "Not used" 90 "Not used" 91 "Not used" 92 "Not used" 93 "Not used" 94 "Not used" 95 "Not used" 96 "Not used" 97 "Not used" 98 "Not used" 99 "Not used" 100 "A+" 101 "Not used" 102 "CC2" 103 "Data Upload" 104 "Battery Check" 105 "Not used" 106 "Not used" 107 "Not used" 108 "Not used" 109 "Not used" 110 "Not used" 111 "Not used" 112 "Not used" 113 "Not used" 114 "Not used" 115 "Not used" 116 "Not used" 117 "Not used" 118 "Not used" 119 "Not used" 120 "Not used" 121 "Not used" 122 "Not used" 123 "Not used" 124 "Not used" 125 "Not used" 126 "Not used" 127 "Not used" 128 "Not used" 129 "Not used" 130 "Not used" 131 "Not used" 132 "Not used" 133 "Not used" 134 "Not used" 135 "Not used" 136 "Not used" 137 "Not used" 138 "Not used" 139 "Not used" 140 "Not used" 141 "Not used" 142 "Not used" 143 "Not used" 144 "Not used" 145 "Not used" 146 "Not used" 147 "Not used" 148 "Not used" 149 "Not used" 150 "Not used" 151 "Not used" 152 "Not used" 153 "Not used" 154 "Not used" 155 "Not used" 156 "Not used" 157 "Not used" 158 "Not used" 159 "Not used" 160 "Not used" 161 "Not used" 162 "Not used" 163 "Not used" 164 "Not used" 165 "Not used" 166 "Not used" 167 "Not used" 168 "Not used" 169 "Not used" 170 "Not used" 171 "Not used" 172 "Not used" 173 "Not used" 174 "Not used" 175 "Not used" 176 "Not used" 177 "Not used" 178 "Not used" 179 "Not used" 180 "Not used" 181 "Not used" 182 "Not used" 183 "Not used" 184 "Not used" 185 "Not used" 186 "Not used" 187 "Not used" 188 "Not used" 189 "Not used" 190 "Not used" 191 "Not used" 192 "Not used" 193 "Not used" 194 "Not used" 195 "Not used" 196 "Not used" 197 "Not used" 198 "Not used" 199 "Not used" 200 "Not used" 201 "Not used" 202 "Not used" 203 "Not used" 204 "Not used" 205 "Not used" 206 "Not used" 207 "Not used" 208 "Not used" 209 "Not used" 210 "Not used" 211 "Not used" 212 "Not used" 213 "Not used" 214 "Not used" 215 "Not used" 216 "Not used" 217 "Not used" 218 "Not used" 219 "Not used" 220 "Not used" 221 "Not used" 222 "Not used" 223 "Not used" 224 "Not used" 225 "Not used" 226 "Not used" 227 "Not used" 228 "Not used" 229 "Not used" 230 "Not used" 231 "Not used" 232 "Not used" 233 "Not used" 234 "Not used" 235 "Not used" 236 "Not used" 237 "Not used" 238 "Not used" 239 "Not used" 240 "Not used" 241 "Not used" 242 "Not used" 243 "Not used" 244 "Not used" 245 "Not used" 246 "Not used" 247 "Not used" 248 "Not used" 249 "Not used" 250 "Not used" 251 "Not used" 252 "Not used" 253 "Not used" 254 "Not used" 255 "Not used" ;
VAL_ 1506 BMS_SubNetWakeRq 0 "No request" 1 "Wake up" 0 "No request" 1 "Wake up" 0 "No request" 1 "Wake up" 0 "No request" 1 "Wake up" 0 "No request" 1 "Wake up" 0 "No request" 1 "Wake up" 0 "No request" 1 "Wake up" ;
VAL_ 1506 BMS_NMKeepingOrigin 0 "No request" 1 "Request" ;
VAL_ 1510 IPS_NMWakeupOrigin 0 "Reserved" 1 "Message wake up" 18 "IGN ON" 96 "CC" 97 "CP" ;
VAL_ 1510 IPS_SubNetWakeRq 0 "No request" 1 "Wake up" 0 "No request" 1 "Wake up" 0 "No request" 1 "Wake up" 0 "No request" 1 "Wake up" 0 "No request" 1 "Wake up" 0 "No request" 1 "Wake up" 0 "No request" 1 "Wake up" ;
VAL_ 1510 IPS_NMKeepingOrigin 0 "No request" 1 "Request" 0 "No request" 1 "Request" 0 "No request" 1 "Request" ;
VAL_ 1533 EVCC_NMWakeupOrigin 0 "Reserved" 1 "Message wake up" 18 "IGN ON" 96 "CC" 97 "CP" ;
VAL_ 1533 EVCC_SubNetWakeRq 0 "No request" 1 "Wake up" 0 "No request" 1 "Wake up" 0 "No request" 1 "Wake up" 0 "No request" 1 "Wake up" 0 "No request" 1 "Wake up" 0 "No request" 1 "Wake up" 0 "No request" 1 "Wake up" ;
VAL_ 1533 EVCC_NMKeepingOrigin 0 "No request" 1 "Request" 0 "No request" 1 "Request" ;
VAL_ 1376 EOP_NMWakeupOrigin 0 "Reserve" 1 "Message wake up" 2 "Not used" 3 "Not used" 4 "Not used" 5 "Not used" 6 "Not used" 7 "Not used" 8 "Not used" 9 "Not used" 10 "Not used" 11 "Not used" 12 "Not used" 13 "Not used" 14 "Not used" 15 "Not used" 16 "Not used" 17 "Not used" 18 "Not used" 19 "Not used" 20 "Not used" 21 "Not used" 22 "Not used" 23 "Not used" 24 "Not used" 25 "Not used" 26 "Not used" 27 "Not used" 28 "Not used" 29 "Not used" 30 "Not used" 31 "Not used" 32 "Not used" 33 "Not used" 34 "Not used" 35 "Not used" 36 "Not used" 37 "Not used" 38 "Not used" 39 "Not used" 40 "Not used" 41 "Not used" 42 "Not used" 43 "Not used" 44 "Not used" 45 "Not used" 46 "Not used" 47 "Not used" 48 "Not used" 49 "Not used" 50 "Not used" 51 "Not used" 52 "Not used" 53 "Not used" 54 "Not used" 55 "Not used" 56 "Not used" 57 "Not used" 58 "Not used" 59 "Not used" 60 "Not used" 61 "Not used" 62 "Not used" 63 "Not used" 64 "Not used" 65 "Not used" 66 "Not used" 67 "Not used" 68 "Not used" 69 "Not used" 70 "Not used" 71 "Not used" 72 "Not used" 73 "Not used" 74 "Not used" 75 "Not used" 76 "Not used" 77 "Not used" 78 "Not used" 79 "Not used" 80 "Not used" 81 "Not used" 82 "Not used" 83 "Not used" 84 "Not used" 85 "Not used" 86 "Not used" 87 "Not used" 88 "Not used" 89 "Not used" 90 "Not used" 91 "Not used" 92 "Not used" 93 "Not used" 94 "Not used" 95 "Not used" 96 "Not used" 97 "Not used" 98 "Not used" 99 "Not used" 100 "Not used" 101 "Not used" 102 "Not used" 103 "Not used" 104 "Not used" 105 "Not used" 106 "Not used" 107 "Not used" 108 "Not used" 109 "Not used" 110 "Not used" 111 "Not used" 112 "Not used" 113 "Not used" 114 "Not used" 115 "Not used" 116 "Not used" 117 "Not used" 118 "Not used" 119 "Not used" 120 "Not used" 121 "Not used" 122 "Not used" 123 "Not used" 124 "Not used" 125 "Not used" 126 "Not used" 127 "Not used" 128 "Not used" 129 "Not used" 130 "Not used" 131 "Not used" 132 "Not used" 133 "Not used" 134 "Not used" 135 "Not used" 136 "Not used" 137 "Not used" 138 "Not used" 139 "Not used" 140 "Not used" 141 "Not used" 142 "Not used" 143 "Not used" 144 "Not used" 145 "Not used" 146 "Not used" 147 "Not used" 148 "Not used" 149 "Not used" 150 "Not used" 151 "Not used" 152 "Not used" 153 "Not used" 154 "Not used" 155 "Not used" 156 "Not used" 157 "Not used" 158 "Not used" 159 "Not used" 160 "Not used" 161 "Not used" 162 "Not used" 163 "Not used" 164 "Not used" 165 "Not used" 166 "Not used" 167 "Not used" 168 "Not used" 169 "Not used" 170 "Not used" 171 "Not used" 172 "Not used" 173 "Not used" 174 "Not used" 175 "Not used" 176 "Not used" 177 "Not used" 178 "Not used" 179 "Not used" 180 "Not used" 181 "Not used" 182 "Not used" 183 "Not used" 184 "Not used" 185 "Not used" 186 "Not used" 187 "Not used" 188 "Not used" 189 "Not used" 190 "Not used" 191 "Not used" 192 "Not used" 193 "Not used" 194 "Not used" 195 "Not used" 196 "Not used" 197 "Not used" 198 "Not used" 199 "Not used" 200 "Not used" 201 "Not used" 202 "Not used" 203 "Not used" 204 "Not used" 205 "Not used" 206 "Not used" 207 "Not used" 208 "Not used" 209 "Not used" 210 "Not used" 211 "Not used" 212 "Not used" 213 "Not used" 214 "Not used" 215 "Not used" 216 "Not used" 217 "Not used" 218 "Not used" 219 "Not used" 220 "Not used" 221 "Not used" 222 "Not used" 223 "Not used" 224 "Not used" 225 "Not used" 226 "Not used" 227 "Not used" 228 "Not used" 229 "Not used" 230 "Not used" 231 "Not used" 232 "Not used" 233 "Not used" 234 "Not used" 235 "Not used" 236 "Not used" 237 "Not used" 238 "Not used" 239 "Not used" 240 "Not used" 241 "Not used" 242 "Not used" 243 "Not used" 244 "Not used" 245 "Not used" 246 "Not used" 247 "Not used" 248 "Not used" 249 "Not used" 250 "Not used" 251 "Not used" 252 "Not used" 253 "Not used" 254 "Not used" 255 "Not used" ;
VAL_ 1376 EOP_SubNetWakeRq 0 "No request" 1 "Wake up" 0 "No request" 1 "Wake up" 0 "No request" 1 "Wake up" 0 "No request" 1 "Wake up" 0 "No request" 1 "Wake up" 0 "No request" 1 "Wake up" 0 "No request" 1 "Wake up" ;
VAL_ 1406 NIDU_NMWakeupOrigin 0 "Reserve" 1 "Message wake up" 2 "Not used" 3 "Not used" 4 "Not used" 5 "Not used" 6 "Not used" 7 "Not used" 8 "Not used" 9 "Not used" 10 "Not used" 11 "Not used" 12 "Not used" 13 "Not used" 14 "Not used" 15 "Not used" 16 "Not used" 17 "Not used" 18 "IGN ON" 19 "Not used" 20 "Not used" 21 "Not used" 22 "Not used" 23 "Not used" 24 "Not used" 25 "Not used" 26 "Not used" 27 "Not used" 28 "Not used" 29 "Not used" 30 "Not used" 31 "Not used" 32 "Not used" 33 "Not used" 34 "Not used" 35 "Not used" 36 "Not used" 37 "Not used" 38 "Not used" 39 "Not used" 40 "Not used" 41 "Not used" 42 "Not used" 43 "Not used" 44 "Not used" 45 "Not used" 46 "Not used" 47 "Not used" 48 "Not used" 49 "Not used" 50 "Not used" 51 "Not used" 52 "Not used" 53 "Not used" 54 "Not used" 55 "Not used" 56 "Not used" 57 "Not used" 58 "Not used" 59 "Not used" 60 "Not used" 61 "Not used" 62 "Not used" 63 "Not used" 64 "Not used" 65 "Not used" 66 "Not used" 67 "Not used" 68 "Not used" 69 "Not used" 70 "Not used" 71 "Not used" 72 "Not used" 73 "Not used" 74 "Not used" 75 "Not used" 76 "Not used" 77 "Not used" 78 "Not used" 79 "Not used" 80 "Not used" 81 "Not used" 82 "Not used" 83 "Not used" 84 "Not used" 85 "Not used" 86 "Not used" 87 "Not used" 88 "Not used" 89 "Not used" 96 "CC" 97 "CP" ;
VAL_ 1406 NIDU_SubNetWakeRq 0 "No request" 1 "Wake up" 0 "No request" 1 "Wake up" 0 "No request" 1 "Wake up" 0 "No request" 1 "Wake up" 0 "No request" 1 "Wake up" 0 "No request" 1 "Wake up" 0 "No request" 1 "Wake up" ;
VAL_ 1406 NIDU_NMKeepingOrigin 0 "No request" 1 "Request" ;
VAL_ 1508 DCU_NMWakeupOrigin 0 "Reserve" 1 "Message wake up" 2 "Not used" 3 "Not used" 4 "Not used" 5 "Not used" 6 "Not used" 7 "Not used" 8 "Not used" 9 "Not used" 10 "Not used" 11 "Not used" 12 "Not used" 13 "Not used" 14 "Not used" 15 "Not used" 16 "Not used" 17 "Not used" 18 "IGN ON" 19 "Not used" 20 "Not used" 21 "Not used" 22 "Not used" 23 "Not used" 24 "Not used" 25 "Not used" 26 "Not used" 27 "Not used" 28 "Not used" 29 "Not used" 30 "Not used" 31 "Not used" 32 "Not used" 33 "Not used" 34 "Not used" 35 "Not used" 36 "Not used" 37 "Not used" 38 "Not used" 39 "Not used" 40 "Not used" 41 "Not used" 42 "Not used" 43 "Not used" 44 "Not used" 45 "Not used" 46 "Not used" 47 "Not used" 48 "Not used" 49 "Not used" 50 "Not used" 51 "Not used" 52 "Not used" 53 "Not used" 54 "Not used" 55 "Not used" 56 "Not used" 57 "Not used" 58 "Not used" 59 "Not used" 60 "Not used" 61 "Not used" 62 "Not used" 63 "Not used" 64 "Not used" 65 "Not used" 66 "Not used" 67 "Not used" 68 "Not used" 69 "Not used" 70 "Not used" 71 "Not used" 72 "Not used" 73 "Not used" 74 "Not used" 75 "Not used" 76 "Not used" 77 "Not used" 78 "Not used" 79 "Not used" 80 "Not used" 81 "Not used" 82 "Not used" 83 "Not used" 84 "Not used" 85 "Not used" 86 "Not used" 87 "Not used" 88 "Not used" 89 "Not used" 90 "Not used" 91 "Not used" 92 "Not used" 93 "Not used" 94 "Not used" 95 "Not used" 96 "Not used" 97 "Not used" 98 "Not used" 99 "Not used" 100 "Not used" 101 "Not used" 102 "Not used" 103 "Not used" 104 "Not used" 105 "Not used" 106 "Not used" 107 "Not used" 108 "Not used" 109 "Not used" 110 "Not used" 111 "Not used" 112 "Not used" 113 "Not used" 114 "Not used" 115 "Not used" 116 "Not used" 117 "Not used" 118 "Not used" 119 "Not used" 120 "Not used" 121 "Not used" 122 "Not used" 123 "Not used" 124 "Not used" 125 "Not used" 126 "Not used" 127 "Not used" 128 "Not used" 129 "Not used" 130 "Not used" 131 "Not used" 132 "Not used" 133 "Not used" 134 "Not used" 135 "Not used" 136 "Not used" 137 "Not used" 138 "Not used" 139 "Not used" 140 "Not used" 141 "Not used" 142 "Not used" 143 "Not used" 144 "Not used" 145 "Not used" 146 "Not used" 147 "Not used" 148 "Not used" 149 "Not used" 150 "Not used" 151 "Not used" 152 "Not used" 153 "Not used" 154 "Not used" 155 "Not used" 156 "Not used" 157 "Not used" 158 "Not used" 159 "Not used" 160 "Not used" 161 "Not used" 162 "Not used" 163 "Not used" 164 "Not used" 165 "Not used" 166 "Not used" 167 "Not used" 168 "Not used" 169 "Not used" 170 "Not used" 171 "Not used" 172 "Not used" 173 "Not used" 174 "Not used" 175 "Not used" 176 "Not used" 177 "Not used" 178 "Not used" 179 "Not used" 180 "Not used" 181 "Not used" 182 "Not used" 183 "Not used" 184 "Not used" 185 "Not used" 186 "Not used" 187 "Not used" 188 "Not used" 189 "Not used" 190 "Not used" 191 "Not used" 192 "Not used" 193 "Not used" 194 "Not used" 195 "Not used" 196 "Not used" 197 "Not used" 198 "Not used" 199 "Not used" 200 "Not used" 201 "Not used" 202 "Not used" 203 "Not used" 204 "Not used" 205 "Not used" 206 "Not used" 207 "Not used" 208 "Not used" 209 "Not used" 210 "Not used" 211 "Not used" 212 "Not used" 213 "Not used" 214 "Not used" 215 "Not used" 216 "Not used" 217 "Not used" 218 "Not used" 219 "Not used" 220 "Not used" 221 "Not used" 222 "Not used" 223 "Not used" 224 "Not used" 225 "Not used" 226 "Not used" 227 "Not used" 228 "Not used" 229 "Not used" 230 "Not used" 231 "Not used" 232 "Not used" 233 "Not used" 234 "Not used" 235 "Not used" 236 "Not used" 237 "Not used" 238 "Not used" 239 "Not used" 240 "Not used" 241 "Not used" 242 "Not used" 243 "Not used" 244 "Not used" 245 "Not used" 246 "Not used" 247 "Not used" 248 "Not used" 249 "Not used" 250 "Not used" 251 "Not used" 252 "Not used" 253 "Not used" 254 "Not used" 255 "Not used" ;
VAL_ 1508 DCU_SubNetWakeRq 0 "No request" 1 "Wake up" 0 "No request" 1 "Wake up" 0 "No request" 1 "Wake up" 0 "No request" 1 "Wake up" 0 "No request" 1 "Wake up" 0 "No request" 1 "Wake up" 0 "No request" 1 "Wake up" ;
VAL_ 1508 DCU_NMKeepingOrigin 0 "No request" 1 "Request" ;
VAL_ 1531 ITS_NMWakeupOrigin 0 "Reserve" 1 "Message wake up" 2 "TimedVentilation" 3 "Not used" 4 "Not used" 5 "Not used" 6 "Not used" 7 "Not used" 8 "Not used" 9 "Not used" 10 "Not used" 11 "Not used" 12 "Not used" 13 "Not used" 14 "Not used" 15 "Not used" 16 "Not used" 17 "Not used" 18 "IGN ON" 19 "Not used" 20 "Not used" 21 "Not used" 22 "Not used" 23 "Not used" 24 "Not used" 25 "Not used" 26 "Not used" 27 "Not used" 28 "Not used" 29 "Not used" 30 "Not used" 31 "Not used" 32 "Not used" 33 "Not used" 34 "Not used" 35 "Not used" 36 "Not used" 37 "Not used" 38 "Not used" 39 "Not used" 40 "Not used" 41 "Not used" 42 "Not used" 43 "Not used" 44 "Not used" 45 "Not used" 46 "Not used" 47 "Not used" 48 "Not used" 49 "Not used" 50 "Not used" 51 "Not used" 52 "Not used" 53 "Not used" 54 "Not used" 55 "Not used" 56 "Not used" 57 "Not used" 58 "Not used" 59 "Not used" 60 "Not used" 61 "Not used" 62 "Not used" 63 "Not used" 64 "Not used" 65 "Not used" 66 "Not used" 67 "Not used" 68 "Not used" 69 "Not used" 70 "Not used" 71 "Not used" 72 "Not used" 73 "Not used" 74 "Not used" 75 "Not used" 76 "Not used" 77 "Not used" 78 "Not used" 79 "Not used" 80 "Not used" 81 "Not used" 82 "Not used" 83 "Not used" 84 "Not used" 85 "Not used" 86 "Not used" 87 "Not used" 88 "Not used" 89 "Not used" 90 "Not used" 91 "Not used" 92 "Not used" 93 "Not used" 94 "Not used" 95 "Not used" 96 "Not used" 97 "Not used" 98 "Not used" 99 "Not used" 100 "Not used" 101 "Not used" 102 "Not used" 103 "Not used" 104 "Not used" 105 "Not used" 106 "Not used" 107 "Not used" 108 "Not used" 109 "Not used" 110 "Not used" 111 "Not used" 112 "Not used" 113 "Not used" 114 "Not used" 115 "Not used" 116 "Not used" 117 "Not used" 118 "Not used" 119 "Not used" 120 "Not used" 121 "Not used" 122 "Not used" 123 "Not used" 124 "Not used" 125 "Not used" 126 "Not used" 127 "Not used" 128 "Not used" 129 "Not used" 130 "Not used" 131 "Not used" 132 "Not used" 133 "Not used" 134 "Not used" 135 "Not used" 136 "Not used" 137 "Not used" 138 "Not used" 139 "Not used" 140 "Not used" 141 "Not used" 142 "Not used" 143 "Not used" 144 "Not used" 145 "Not used" 146 "Not used" 147 "Not used" 148 "Not used" 149 "Not used" 150 "Not used" 151 "Not used" 152 "Not used" 153 "Not used" 154 "Not used" 155 "Not used" 156 "Not used" 157 "Not used" 158 "Not used" 159 "Not used" 160 "Not used" 161 "Not used" 162 "Not used" 163 "Not used" 164 "Not used" 165 "Not used" 166 "Not used" 167 "Not used" 168 "Not used" 169 "Not used" 170 "Not used" 171 "Not used" 172 "Not used" 173 "Not used" 174 "Not used" 175 "Not used" 176 "Not used" 177 "Not used" 178 "Not used" 179 "Not used" 180 "Not used" 181 "Not used" 182 "Not used" 183 "Not used" 184 "Not used" 185 "Not used" 186 "Not used" 187 "Not used" 188 "Not used" 189 "Not used" 190 "Not used" 191 "Not used" 192 "Not used" 193 "Not used" 194 "Not used" 195 "Not used" 196 "Not used" 197 "Not used" 198 "Not used" 199 "Not used" 200 "Not used" 201 "Not used" 202 "Not used" 203 "Not used" 204 "Not used" 205 "Not used" 206 "Not used" 207 "Not used" 208 "Not used" 209 "Not used" 210 "Not used" 211 "Not used" 212 "Not used" 213 "Not used" 214 "Not used" 215 "Not used" 216 "Not used" 217 "Not used" 218 "Not used" 219 "Not used" 220 "Not used" 221 "Not used" 222 "Not used" 223 "Not used" 224 "Not used" 225 "Not used" 226 "Not used" 227 "Not used" 228 "Not used" 229 "Not used" 230 "Not used" 231 "Not used" 232 "Not used" 233 "Not used" 234 "Not used" 235 "Not used" 236 "Not used" 237 "Not used" 238 "Not used" 239 "Not used" 240 "Not used" 241 "Not used" 242 "Not used" 243 "Not used" 244 "Not used" 245 "Not used" 246 "Not used" 247 "Not used" 248 "Not used" 249 "Not used" 250 "Not used" 251 "Not used" 252 "Not used" 253 "Not used" 254 "Not used" 255 "Not used" ;
VAL_ 1531 ITS_SubNetWakeRq 0 "No request" 1 "Wake up" 0 "No request" 1 "Wake up" 0 "No request" 1 "Wake up" 0 "No request" 1 "Wake up" 0 "No request" 1 "Wake up" 0 "No request" 1 "Wake up" 0 "No request" 1 "Wake up" ;
VAL_ 1531 ITS_NMKeepingOrigin 0 "No request" 1 "request" 0 "No request" 1 "request" ;
VAL_ 1509 GCU_NMWakeupOrignin 0 "default value;" 1 "Message wake up;" 18 "IGN ON;" ;
VAL_ 1509 GCU_SubNetWakeRq 0 "No request" 1 "Wake up" 0 "No request" 1 "Wake up" 0 "No request" 1 "Wake up" 0 "No request" 1 "Wake up" 0 "No request" 1 "Wake up" 0 "No request" 1 "Wake up" 0 "No request" 1 "Wake up" ;
VAL_ 1509 GCU_NMKeepingOrigin 0 "No request" 1 "Request" ;
VAL_ 1359 GWM_NMWakeupOrigin_ECAN 3 "LIN slaver wake up" 18 "IGN ON" 112 "ACAN NM wake up" 113 "BCAN NM wake up" 114 "ECAN NM wake up" 115 "PCAN NM wake up" 116 "ICAN NM wake up" 117 "TCAN NM wake up" 118 "DCAN NM wake up" 119 "LCAN NM wake up" 120 "Network Non-sleep Node Monitoring wake up" 121 "OTA Mode wake up" 122 "DCAN Diagnostic message wake up" 123 "TCAN Diagnostic message wake up" 124 "reserved" 125 "reserved" 126 "reserved" 127 "reserved" 128 "reserved" 129 "reserved" 130 "reserved" ;
VAL_ 1359 GWM_SubNetWakeRq 0 "No request" 1 "Wake up" 0 "No request" 1 "Wake up" 0 "No request" 1 "Wake up" 0 "No request" 1 "Wake up" 0 "No request" 1 "Wake up" 0 "No request" 1 "Wake up" 0 "No request" 1 "Wake up" ;
VAL_ 1359 GWM_NMKeepingOrigin 0 "No request" 1 "Request" 0 "No request" 1 "Request" 0 "No request" 1 "Request" 0 "No request" 1 "Request" 0 "No request" 1 "Request" 0 "No request" 1 "Request" ;
VAL_ 1359 GWM_NMKeepingOrigin2 0 "No request" 1 "Wake up" 0 "No request" 1 "Wake up" 0 "No request" 1 "Wake up" 0 "No request" 1 "Wake up" 0 "No request" 1 "Wake up" 0 "No request" 1 "Wake up" 0 "No request" 1 "Wake up" 0 "No request" 1 "Wake up" ;
